VERSION ""

NS_ :

BS_:

BU_: Dummy_PCE EBOOST_OBD_PCE EOCM2cp_K2_PCE EPSb_PCE SDM_PCE EBCM_PCE EPSa_PCE CMMb_PCE CMMa_PCE CGM3b_PCE ADIMa_PCE
VAL_TABLE_ vt_BooleanValues 1 "true" 0 "false" ;
VAL_TABLE_ StgOvrdDetn 3 "Disabled" 2 "False" 1 "True" 0 "Initialization" ;
VAL_TABLE_ PriADSCmdMsgStat 3 "Dual Communication Failure" 2 "Secondary Communication Failed" 1 "Main Communication Failed" 0 "Communication Normal" ;
VAL_TABLE_ PriBrkSysArbStat 7 "Supervisor Override" 6 "Automatic Brake Apply 2" 5 "Automatic Brake Apply 1" 4 "CoPilot Override Request Honored" 3 "Redundant ADS Request Honored" 2 "Main ADS Request Honored" 1 "No Autonomous Request" 0 "Unknown" ;
VAL_TABLE_ StrgCmndMsgStat 3 "Dual Communication Failure" 2 "Redundant Communication Failed" 1 "Primary Communication Failed" 0 "Communication Normal" ;
VAL_TABLE_ StrgCmndMsgUtlzd 1 "Redundant Controller" 0 "Primary Controller" ;
VAL_TABLE_ AutoEstBrkTrqAppStat 2 "Valid" 1 "Reduced Accuracy" 0 "Invalid" ;
VAL_TABLE_ AutoBrkSysDrInfcStat 3 "Failed" 2 "Driver Intervention Not Detected" 1 "Driver Intervention Detected" 0 "Unknown" ;
VAL_TABLE_ BrkPedDrvOvrdDtdESC 3 "Unknown" 2 "External Source Building Pressure" 1 "ESC Building System Pressure" 0 "ESC System Pressure Inactive" ;
VAL_TABLE_ ActrBrkFldFlwReqStat 2 "qTarget_EBRmaxPerformance" 1 "qTarget_EBR" 0 "qTarget_Off" ;
VAL_TABLE_ EstWhlBrkPrsStat 3 "Invalid" 2 "Reduced Accuracy" 1 "Valid" 0 "Unknown" ;
VAL_TABLE_ SpltMuCntrl 2 "Split Driver Side High" 1 "Split Driver Side Low" 0 "Inactive" ;
VAL_TABLE_ PriBrkModStat 3 "Failed" 2 "Active" 1 "Available" 0 "Not Available" ;
VAL_TABLE_ PrkBrkReqiB 1 "Apply" 0 "No Request" ;
VAL_TABLE_ ExtBrkReqStat 3 "External Brake Req Active" 2 "External Brake Req Available" 1 "External Brake Req Not Available" 0 "Unknown" ;
VAL_TABLE_ PedOvrdBrkiBst 3 "Unknown" 2 "External Override of Brake Pedal" 1 "iBooster EBR in Control" 0 "iBooster Inactive" ;
VAL_TABLE_ Qualifier 2 "Faulted" 1 "Normal" 0 "Unknown" ;
VAL_TABLE_ iBstStat 7 "iBooster Ready" 6 "iBooster PostRun Reduced" 5 "iBooster Reduced" 2 "iBooster Diagnosis" 1 "iBooster Failure iBoosterOff" 0 "Unknown" 3 "iBooster Autonomous Diagnosis" 4 "iBooster Standalone" ;
VAL_TABLE_ BrkRngLmtgStat 3 "Request Rate Limited" 2 "Req Value Limited Maximum" 1 "Req Value Limited Minimum" 0 "Request Not Limited" ;
VAL_TABLE_ BrkSysStat 6 "Degraded Mode 5" 5 "Degraded Mode 4" 4 "Degraded Mode 3" 3 "Degraded Mode 2" 2 "Degraded Mode 1" 1 "Full Function" 0 "Unknown" ;
VAL_TABLE_ SecBrkModSbSte 5 "Loss of Request" 4 "Full System" 3 "Failed Operational" 2 "Failed Degraded" 1 "Unable to Execute Requests" 0 "Faulted" ;
VAL_TABLE_ SecBrkModCapStat 1 "Active" 0 "Not Active" ;
VAL_TABLE_ EstSrfcMuTyp 3 "Invalid" 2 "Actual Surface Estimate" 1 "Minimum Surface Estimate" 0 "Unknown" ;
VAL_TABLE_ SecBrkModStat 3 "Failed" 2 "Active" 1 "Available" 0 "Not Available" ;
VAL_TABLE_ StgSysOtptStat 3 "Failed" 2 "Single Controller" 1 "Fail Operational" 0 "Unknown" ;
VAL_TABLE_ StgOtptTempLmtgSte 4 "Voltage" 3 "Thermal" 2 "Safety Limit Exceeded" 1 "Normal" 0 "Unknown" 7 "ECU Fault Limited" 6 "Friction Limited" 5 "Lash Exceeded" ;
VAL_TABLE_ AutoStrgCmndStat 6 "Failed" 5 "Emergency Steering Profile" 4 "Temporarily Limited" 3 "Active" 2 "Ready" 1 "Temporarily Inhibited" 0 "Unknown" ;
VAL_TABLE_ EPSWAR_ReqdState 2 "Active" 1 "Inactive" 0 "No Action" ;
VAL_TABLE_ EPBReq 2 "Request Release" 1 "Request Apply" 0 "No Request" ;
VAL_TABLE_ AutoBrkReqType 2 "Standstill Hold Request" 1 "Brake Torque Request" 0 "No Request" 3 "Brake Prefill" ;
VAL_TABLE_ ABRS2_SAAYawMtReqScBsSt 7 "Not Used 2" 6 "Not Used 1" 5 "Request Out Of Range" 4 "CAN Error" 3 "Failed" 2 "Limited" 1 "Active" 0 "Not Active" ;
VAL_TABLE_ ABRS2_BcupESCDatInpSt 1 "Failed" 0 "Normal" ;
VAL_TABLE_ ABRS2_ACCAutBkRqPrBsSt 7 "Not Used 2" 6 "Not Used 1" 5 "Request Out Of Range" 4 "CAN Error" 3 "Failed" 2 "Limited" 1 "Active" 0 "Not Active" ;
VAL_TABLE_ WhlRotDrctnlStatus 0 "Unknown" 1 "Forward" 2 "Reverse" 3 "Not Supported" 4 "Failed" 5 "Reserved 1" 6 "Reserved 2" 7 "Reserved 3" ;
VAL_TABLE_ ChsSysTrnsShfBhvRq 7 "Upshift" 6 "Downshift" 5 "Minimum Inertia" 4 "Immediate Mode" 3 "Inhibit Shift" 2 "Inhibit Upshift" 1 "Inhibit Downshift" 0 "No Action" ;
VAL_TABLE_ NotEventSta 2 "Pretensioner Deployment Event" 1 "Near Deployment Event" 0 "No Event" 3 "Airbag Deployment Event" ;
VAL_TABLE_ VDAvailability 1 "VirtualDeviceAvailable" 0 "VirtualDeviceUnavailable" ;
VAL_TABLE_ MaskStates 1 "Use Data" 0 "Don't Use Data" ;
VAL_TABLE_ VehSpdAvgDrvnSrc 1 "Wheel Speed" 0 "Transmission Output Speed" ;
VAL_TABLE_ StrWhlAngSenCalStat 2 "Calibrated" 1 "Estimated" 0 "Unknown" ;
VAL_TABLE_ EngSpdStat 3 "Invalid" 1 "Degraded Operation" 0 "Normal Operation" ;
VAL_TABLE_ Vtsig_Diagpresreqstat 4 "Request Cancelled " 3 "Secondary Braking Req Honored" 2 "Primary Braking Request Honored" 1 "No Dynamic Request" 0 "Unknown" ;
VAL_TABLE_ VD_CoPilotSysFltStat 5 "Copilot System Failure" 4 "Partial Function Fault Detected" 3 "Redundancy Fault Detected" 2 "Environmental Interference" 1 "Operational" 0 "Unknown" ;
VAL_TABLE_ SecVehSpdSrcDrvnRed 3 "Transmission Output Speed" 2 "Averaged Driven Wheel Speed" 1 "Motor RPM" 0 " No Source Available" ;
VAL_TABLE_ EPBStat 3 "Failed" 2 "Reduced Performance" 1 "Normal" 0 "Unknown" ;
VAL_TABLE_ EPBApplSt 3 "Applied" 2 "Transitioning" 1 "Released" 0 "Unknown" ;
VAL_TABLE_ BrkFldLvlIndStat 1 "Failed" 0 "Normal" ;
VAL_TABLE_ SystemStatus 3 "Failed" 2 "Active" 1 "Available" 0 "Unknown" ;
VAL_TABLE_ StrgAngTrqBsdEstSrfcMuConf 2 "Indeterminate" 1 "Use Data" 0 "Do Not Use Data" ;
VAL_TABLE_ VehMdMngrSt 0 "Unknown" 1 "Manual" 2 "Autonomous Supervised" 3 "Supervisor Override" 4 "Autonomous Unsupervised" 5 "Failed" ;
VAL_TABLE_ SysBkUpPwrMd 3 "Crank Request" 2 "Run" 1 "Accessory" 0 "Off" ;
VAL_TABLE_ SysPwrMd 3 "Crank Request" 2 "Run" 1 "Accessory" 0 "Off" ;
VAL_TABLE_ ValidityStates 1 "Invalid" 0 "Valid" ;

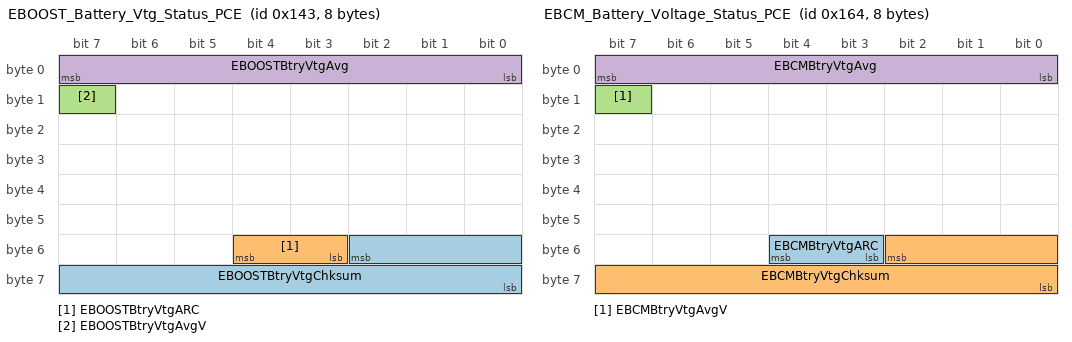
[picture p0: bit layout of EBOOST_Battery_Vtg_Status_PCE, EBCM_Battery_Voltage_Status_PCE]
BO_ 323 EBOOST_Battery_Vtg_Status_PCE: 8 EBOOST_OBD_PCE
 SG_ EBOOSTBtryVtgChksum : 50|11@0+ (1,0) [0|2047] ""  CGM3b_PCE
 SG_ EBOOSTBtryVtgARC : 52|2@0+ (1,0) [0|3] ""  CGM3b_PCE
 SG_ EBOOSTBtryVtgAvgV : 15|1@0+ (1,0) [0|1] ""  CGM3b_PCE
 SG_ EBOOSTBtryVtgAvg : 7|8@0+ (0.1,0) [0|25.5] "V"  CGM3b_PCE

BO_ 356 EBCM_Battery_Voltage_Status_PCE: 8 EBCM_PCE
 SG_ EBCMBtryVtgARC : 52|2@0+ (1,0) [0|3] ""  CGM3b_PCE
 SG_ EBCMBtryVtgChksum : 50|11@0+ (1,0) [0|2047] ""  CGM3b_PCE
 SG_ EBCMBtryVtgAvgV : 15|1@0+ (1,0) [0|1] ""  CGM3b_PCE
 SG_ EBCMBtryVtgAvg : 7|8@0+ (0.1,0) [0|25.5] "V"  CGM3b_PCE

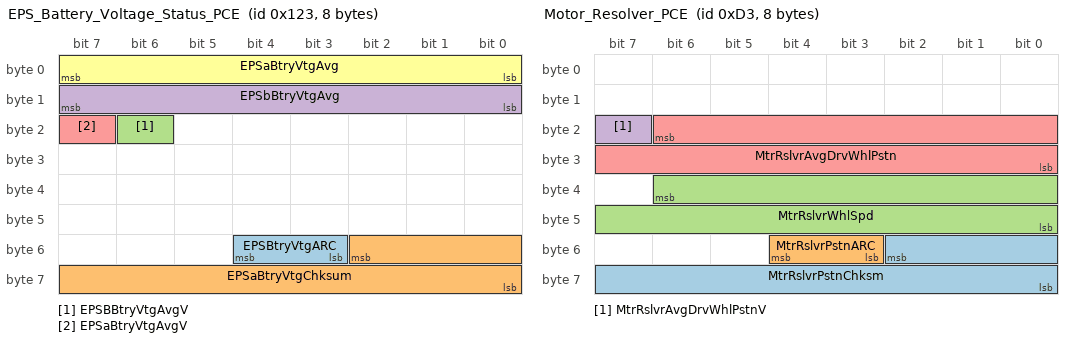
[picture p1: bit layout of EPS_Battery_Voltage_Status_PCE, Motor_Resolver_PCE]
BO_ 291 EPS_Battery_Voltage_Status_PCE: 8 EPSa_PCE
 SG_ EPSBtryVtgARC : 52|2@0+ (1,0) [0|3] ""  CGM3b_PCE
 SG_ EPSaBtryVtgChksum : 50|11@0+ (1,0) [0|2047] ""  CGM3b_PCE
 SG_ EPSBBtryVtgAvgV : 22|1@0+ (1,0) [0|1] ""  CGM3b_PCE
 SG_ EPSbBtryVtgAvg : 15|8@0+ (0.1,0) [0|25.5] "V"  CGM3b_PCE
 SG_ EPSaBtryVtgAvgV : 23|1@0+ (1,0) [0|1] ""  CGM3b_PCE
 SG_ EPSaBtryVtgAvg : 7|8@0+ (0.1,0) [0|25.5] "V"  CGM3b_PCE

BO_ 211 Motor_Resolver_PCE: 8 CGM3b_PCE
 SG_ MtrRslvrPstnChksm : 50|11@0+ (1,0) [0|2047] ""  CMMb_PCE,CMMa_PCE
 SG_ MtrRslvrPstnARC : 52|2@0+ (1,0) [0|3] ""  CMMb_PCE,CMMa_PCE
 SG_ MtrRslvrWhlSpd : 38|15@0+ (0.005035400390625,-15) [-15|149.994964599609] "radians/s"  CMMb_PCE,CMMa_PCE
 SG_ MtrRslvrAvgDrvWhlPstnV : 23|1@0+ (1,0) [0|1] ""  CMMb_PCE,CMMa_PCE
 SG_ MtrRslvrAvgDrvWhlPstn : 22|15@0+ (1,0) [0|32768] "Count"  CMMb_PCE,CMMa_PCE

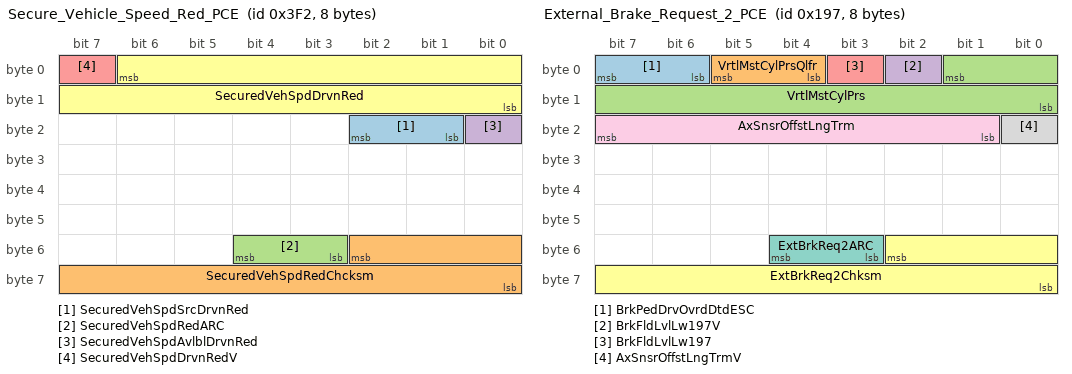
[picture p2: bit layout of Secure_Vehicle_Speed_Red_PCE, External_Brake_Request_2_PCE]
BO_ 1010 Secure_Vehicle_Speed_Red_PCE: 8 CGM3b_PCE
 SG_ SecuredVehSpdSrcDrvnRed : 18|2@0+ (1,0) [0|3] ""  EPSa_PCE,EBOOST_OBD_PCE
 SG_ SecuredVehSpdRedChcksm : 50|11@0+ (1,0) [0|2047] ""  EPSa_PCE,EBOOST_OBD_PCE
 SG_ SecuredVehSpdRedARC : 52|2@0+ (1,0) [0|3] ""  EPSa_PCE,EBOOST_OBD_PCE
 SG_ SecuredVehSpdAvlblDrvnRed : 16|1@0+ (1,0) [0|1] ""  EPSa_PCE,EBOOST_OBD_PCE
 SG_ SecuredVehSpdDrvnRedV : 7|1@0+ (1,0) [0|1] ""  EPSa_PCE,EBOOST_OBD_PCE
 SG_ SecuredVehSpdDrvnRed : 6|15@0+ (0.015625,0) [0|511.984375] "km/h"  EPSa_PCE,EBOOST_OBD_PCE

BO_ 1620 USDT_Resp_From_EBoost_PCE: 8 EBOOST_OBD_PCE
 SG_ DgnInf : 7|64@0+ (1,0) [0|1.84467440737096E+019] ""  CGM3b_PCE

BO_ 1611 USDT_Resp_From_EOCM2cp_K2_PCE: 8 EOCM2cp_K2_PCE
 SG_ DgnInf : 7|64@0+ (1,0) [0|1.84467440737096E+019] ""  CGM3b_PCE

BO_ 584 USDT_Req_to_EPSb_PCE: 8 CGM3b_PCE
 SG_ DgnInf : 7|64@0+ (1,0) [0|1.84467440737096E+019] ""  EPSb_PCE

BO_ 587 USDT_Req_to_EOCM2cp_K2_PCE: 8 CGM3b_PCE
 SG_ DgnInf : 7|64@0+ (1,0) [0|1.84467440737096E+019] ""  EOCM2cp_K2_PCE

BO_ 407 External_Brake_Request_2_PCE: 8 EBCM_PCE
 SG_ BrkPedDrvOvrdDtdESC : 7|2@0+ (1,0) [0|3] ""  EBOOST_OBD_PCE
 SG_ VrtlMstCylPrsQlfr : 5|2@0+ (1,0) [0|3] ""  EBOOST_OBD_PCE
 SG_ VrtlMstCylPrs : 1|10@0+ (0.25,0) [0|250] "bar"  EBOOST_OBD_PCE
 SG_ BrkFldLvlLw197V : 2|1@0+ (1,0) [0|1] ""  ADIMa_PCE,EBOOST_OBD_PCE
 SG_ BrkFldLvlLw197 : 3|1@0+ (1,0) [0|1] ""  ADIMa_PCE,EBOOST_OBD_PCE
 SG_ ExtBrkReq2Chksm : 50|11@0+ (1,0) [0|2047] ""  EBOOST_OBD_PCE
 SG_ ExtBrkReq2ARC : 52|2@0+ (1,0) [0|3] ""  EBOOST_OBD_PCE
 SG_ AxSnsrOffstLngTrmV : 16|1@0+ (1,0) [0|1] ""  EBOOST_OBD_PCE
 SG_ AxSnsrOffstLngTrm : 23|7@0+ (0.0675,-4) [-4|3.9375] "m/s2"  EBOOST_OBD_PCE

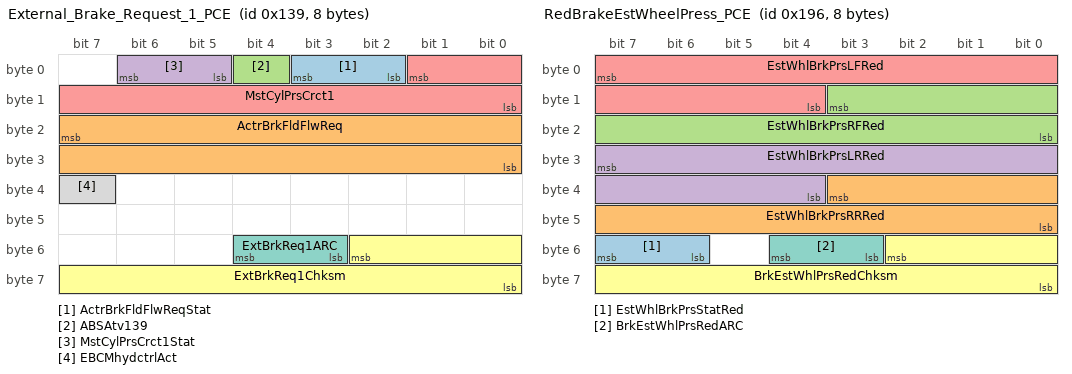
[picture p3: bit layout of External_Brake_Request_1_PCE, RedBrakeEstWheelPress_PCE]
BO_ 313 External_Brake_Request_1_PCE: 8 EBCM_PCE
 SG_ ActrBrkFldFlwReqStat : 3|2@0+ (1,0) [0|3] ""  EBOOST_OBD_PCE
 SG_ ActrBrkFldFlwReq : 23|16@0+ (0.0076904296875,-252) [-252|252] "mL/s"  EBOOST_OBD_PCE
 SG_ ABSAtv139 : 4|1@0+ (1,0) [0|1] ""  EBOOST_OBD_PCE
 SG_ MstCylPrsCrct1Stat : 6|2@0+ (1,0) [0|3] ""  ADIMa_PCE,EBOOST_OBD_PCE
 SG_ MstCylPrsCrct1 : 1|10@0+ (0.3,0) [0|276.6] "bar"  ADIMa_PCE,EBOOST_OBD_PCE
 SG_ ExtBrkReq1Chksm : 50|11@0+ (1,0) [0|2047] ""  EBOOST_OBD_PCE
 SG_ ExtBrkReq1ARC : 52|2@0+ (1,0) [0|3] ""  EBOOST_OBD_PCE
 SG_ EBCMhydctrlAct : 39|1@0+ (1,0) [0|1] ""  EBOOST_OBD_PCE

BO_ 406 RedBrakeEstWheelPress_PCE: 8 EBCM_PCE
 SG_ EstWhlBrkPrsStatRed : 55|2@0+ (1,0) [0|3] ""  EBOOST_OBD_PCE,ADIMa_PCE
 SG_ EstWhlBrkPrsRRRed : 35|12@0+ (10,0) [0|40950] "kPa"  EBOOST_OBD_PCE,ADIMa_PCE
 SG_ EstWhlBrkPrsRFRed : 11|12@0+ (10,0) [0|40950] "kPa"  EBOOST_OBD_PCE,ADIMa_PCE
 SG_ EstWhlBrkPrsLRRed : 31|12@0+ (10,0) [0|40950] "kPa"  EBOOST_OBD_PCE,ADIMa_PCE
 SG_ EstWhlBrkPrsLFRed : 7|12@0+ (10,0) [0|40950] "kPa"  EBOOST_OBD_PCE,ADIMa_PCE
 SG_ BrkEstWhlPrsRedChksm : 50|11@0+ (1,0) [0|2047] ""  EBOOST_OBD_PCE,ADIMa_PCE
 SG_ BrkEstWhlPrsRedARC : 52|2@0+ (1,0) [0|3] ""  EBOOST_OBD_PCE,ADIMa_PCE

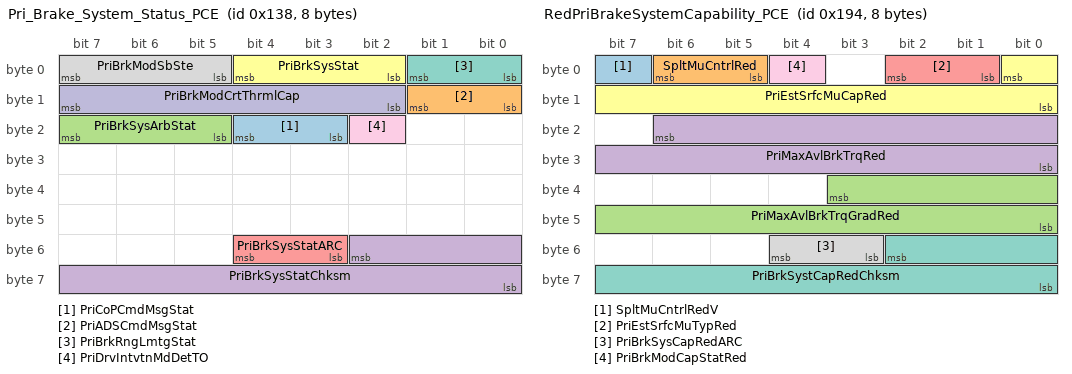
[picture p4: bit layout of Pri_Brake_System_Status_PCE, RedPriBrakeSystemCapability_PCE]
BO_ 312 Pri_Brake_System_Status_PCE: 8 EBCM_PCE
 SG_ PriCoPCmdMsgStat : 20|2@0+ (1,0) [0|3] ""  EBOOST_OBD_PCE,ADIMa_PCE
 SG_ PriADSCmdMsgStat : 9|2@0+ (1,0) [0|3] ""  EBOOST_OBD_PCE,ADIMa_PCE
 SG_ PriBrkSysArbStat : 23|3@0+ (1,0) [0|7] ""  EBOOST_OBD_PCE,ADIMa_PCE
 SG_ PriBrkSysStatChksm : 50|11@0+ (1,0) [0|2047] ""  ADIMa_PCE,EBOOST_OBD_PCE
 SG_ PriBrkSysStatARC : 52|2@0+ (1,0) [0|3] ""  ADIMa_PCE,EBOOST_OBD_PCE
 SG_ PriBrkSysStat : 4|3@0+ (1,0) [0|7] ""  ADIMa_PCE,EBOOST_OBD_PCE
 SG_ PriBrkRngLmtgStat : 1|2@0+ (1,0) [0|3] ""  ADIMa_PCE,EBOOST_OBD_PCE
 SG_ PriBrkModSbSte : 7|3@0+ (1,0) [0|7] ""  ADIMa_PCE,EBOOST_OBD_PCE
 SG_ PriDrvIntvtnMdDetTO : 18|1@0+ (1,0) [0|1] ""  ADIMa_PCE,EBOOST_OBD_PCE
 SG_ PriBrkModCrtThrmlCap : 15|6@0+ (1.5873,0) [0|100] "%"  EBOOST_OBD_PCE,ADIMa_PCE

BO_ 404 RedPriBrakeSystemCapability_PCE: 8 EBCM_PCE
 SG_ SpltMuCntrlRedV : 7|1@0+ (1,0) [0|1] ""  ADIMa_PCE
 SG_ SpltMuCntrlRed : 6|2@0+ (1,0) [0|3] ""  ADIMa_PCE
 SG_ PriMaxAvlBrkTrqGradRed : 35|12@0+ (100,0) [0|409500] ""  ADIMa_PCE
 SG_ PriMaxAvlBrkTrqRed : 22|15@0+ (2,-65534) [-65534|0] "Nm"  ADIMa_PCE
 SG_ PriEstSrfcMuTypRed : 2|2@0+ (1,0) [0|3] ""  ADIMa_PCE
 SG_ PriEstSrfcMuCapRed : 0|9@0+ (0.006,0) [0|3.066] ""  ADIMa_PCE
 SG_ PriBrkSystCapRedChksm : 50|11@0+ (1,0) [0|2047] ""  ADIMa_PCE
 SG_ PriBrkSysCapRedARC : 52|2@0+ (1,0) [0|3] ""  ADIMa_PCE
 SG_ PriBrkModCapStatRed : 4|1@0+ (1,0) [0|1] ""  ADIMa_PCE

BO_ 596 USDT_Req_to_EBoost_PCE: 8 CGM3b_PCE
 SG_ DgnInf : 7|64@0+ (1,0) [0|1.84467440737096E+019] ""  EBOOST_OBD_PCE

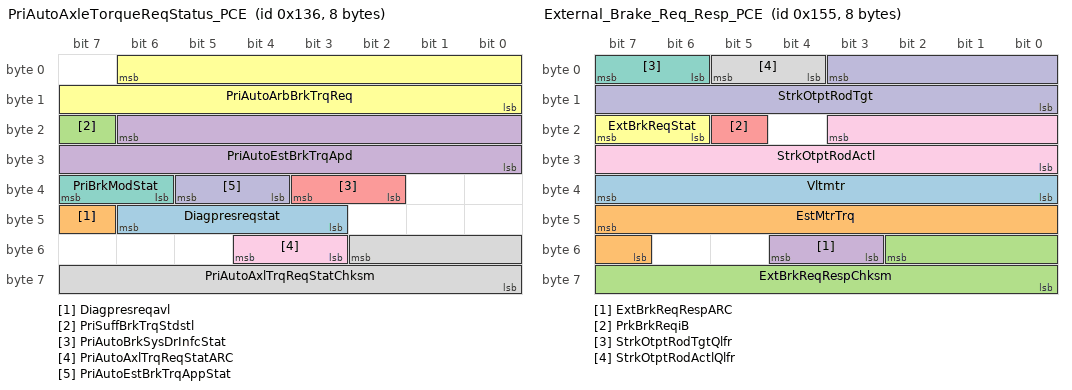
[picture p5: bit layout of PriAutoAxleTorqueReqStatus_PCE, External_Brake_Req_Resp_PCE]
BO_ 310 PriAutoAxleTorqueReqStatus_PCE: 8 EBCM_PCE
 SG_ Diagpresreqstat : 46|4@0+ (1,0) [0|0] ""  ADIMa_PCE
 SG_ Diagpresreqavl : 47|1@0+ (1,0) [0|1] ""  ADIMa_PCE
 SG_ PriSuffBrkTrqStdstl : 23|1@0+ (1,0) [0|1] ""  CGM3b_PCE,ADIMa_PCE
 SG_ PriAutoEstBrkTrqApd : 22|15@0+ (2,-65534) [-65534|0] "Nm"  CGM3b_PCE,ADIMa_PCE
 SG_ PriAutoBrkSysDrInfcStat : 35|2@0+ (1,0) [0|3] ""  EBOOST_OBD_PCE,CGM3b_PCE,ADIMa_PCE
 SG_ PriAutoArbBrkTrqReq : 6|15@0+ (2,-65534) [-65534|0] "Nm"  ADIMa_PCE,CGM3b_PCE
 SG_ PriBrkModStat : 39|2@0+ (1,0) [0|3] ""  ADIMa_PCE,CGM3b_PCE
 SG_ PriAutoAxlTrqReqStatChksm : 50|11@0+ (1,0) [0|2047] ""  CGM3b_PCE,ADIMa_PCE
 SG_ PriAutoAxlTrqReqStatARC : 52|2@0+ (1,0) [0|3] ""  ADIMa_PCE,CGM3b_PCE
 SG_ PriAutoEstBrkTrqAppStat : 37|2@0+ (1,0) [0|3] ""  CGM3b_PCE,ADIMa_PCE

BO_ 341 External_Brake_Req_Resp_PCE: 8 EBOOST_OBD_PCE
 SG_ Vltmtr : 39|8@0+ (0.1,0) [0|25.5] "V"  ADIMa_PCE
 SG_ EstMtrTrq : 47|9@0+ (0.01,0) [0|5.11] "Nm"  ADIMa_PCE
 SG_ ExtBrkReqRespChksm : 50|11@0+ (1,0) [0|2047] ""  EBCM_PCE
 SG_ ExtBrkReqRespARC : 52|2@0+ (1,0) [0|3] ""  EBCM_PCE
 SG_ PrkBrkReqiB : 21|1@0+ (1,0) [0|1] ""  EBCM_PCE
 SG_ ExtBrkReqStat : 23|2@0+ (1,0) [0|3] ""  EBCM_PCE
 SG_ StrkOtptRodTgtQlfr : 7|2@0+ (1,0) [0|3] ""  ADIMa_PCE,EBCM_PCE
 SG_ StrkOtptRodActlQlfr : 5|2@0+ (1,0) [0|3] ""  ADIMa_PCE,EBCM_PCE
 SG_ StrkOtptRodActl : 19|12@0+ (0.015625,0) [0|64] "mm"  ADIMa_PCE,EBCM_PCE
 SG_ StrkOtptRodTgt : 3|12@0+ (0.015625,0) [0|64] "mm"  ADIMa_PCE,EBCM_PCE

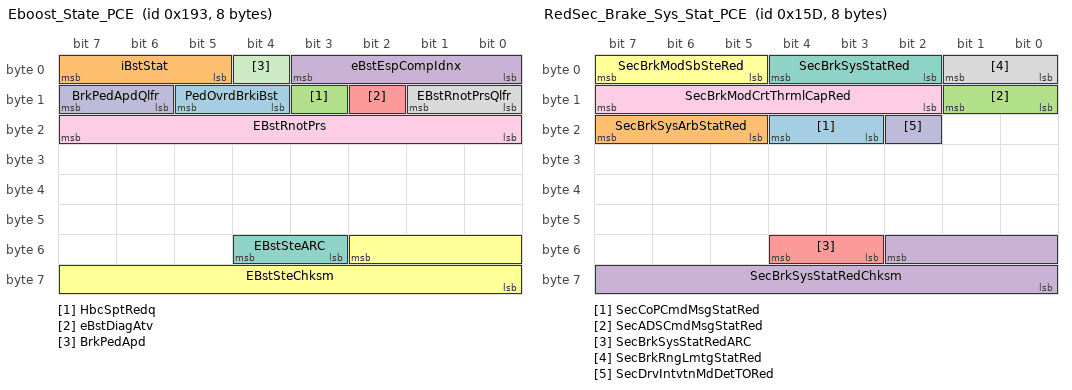
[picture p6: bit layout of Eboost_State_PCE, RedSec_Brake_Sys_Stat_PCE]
BO_ 403 Eboost_State_PCE: 8 EBOOST_OBD_PCE
 SG_ PedOvrdBrkiBst : 13|2@0+ (1,0) [0|3] ""  EBCM_PCE
 SG_ iBstStat : 7|3@0+ (1,0) [0|7] ""  EBCM_PCE
 SG_ HbcSptRedq : 11|1@0+ (1,0) [0|1] ""  EBCM_PCE
 SG_ eBstEspCompIdnx : 3|4@0+ (1,0) [0|15] ""  EBCM_PCE
 SG_ eBstDiagAtv : 10|1@0+ (1,0) [0|1] ""  EBCM_PCE
 SG_ EBstSteChksm : 50|11@0+ (1,0) [0|2047] ""  EBCM_PCE
 SG_ EBstSteARC : 52|2@0+ (1,0) [0|3] ""  EBCM_PCE
 SG_ EBstRnotPrsQlfr : 9|2@0+ (1,0) [0|3] ""  EBCM_PCE
 SG_ EBstRnotPrs : 23|8@0+ (1,0) [0|255] "bar"  EBCM_PCE
 SG_ BrkPedApdQlfr : 15|2@0+ (1,0) [0|3] ""  EBCM_PCE
 SG_ BrkPedApd : 4|1@0+ (1,0) [0|1] ""  EBCM_PCE

BO_ 349 RedSec_Brake_Sys_Stat_PCE: 8 EBOOST_OBD_PCE
 SG_ SecCoPCmdMsgStatRed : 20|2@0+ (1,0) [0|3] ""  EBCM_PCE,ADIMa_PCE
 SG_ SecBrkSysArbStatRed : 23|3@0+ (1,0) [0|7] ""  EBCM_PCE,ADIMa_PCE
 SG_ SecADSCmdMsgStatRed : 9|2@0+ (1,0) [0|3] ""  EBCM_PCE,ADIMa_PCE
 SG_ SecBrkSysStatRedChksm : 50|11@0+ (1,0) [0|2047] ""  ADIMa_PCE,EBCM_PCE
 SG_ SecBrkSysStatRedARC : 52|2@0+ (1,0) [0|3] ""  ADIMa_PCE,EBCM_PCE
 SG_ SecBrkModSbSteRed : 7|3@0+ (1,0) [0|7] ""  ADIMa_PCE,EBCM_PCE
 SG_ SecBrkSysStatRed : 4|3@0+ (1,0) [0|7] ""  ADIMa_PCE,EBCM_PCE
 SG_ SecBrkRngLmtgStatRed : 1|2@0+ (1,0) [0|3] ""  ADIMa_PCE,EBCM_PCE
 SG_ SecBrkModCrtThrmlCapRed : 15|6@0+ (1.5873,0) [0|100] "%"  ADIMa_PCE,EBCM_PCE
 SG_ SecDrvIntvtnMdDetTORed : 18|1@0+ (1,0) [0|1] ""  ADIMa_PCE,EBCM_PCE

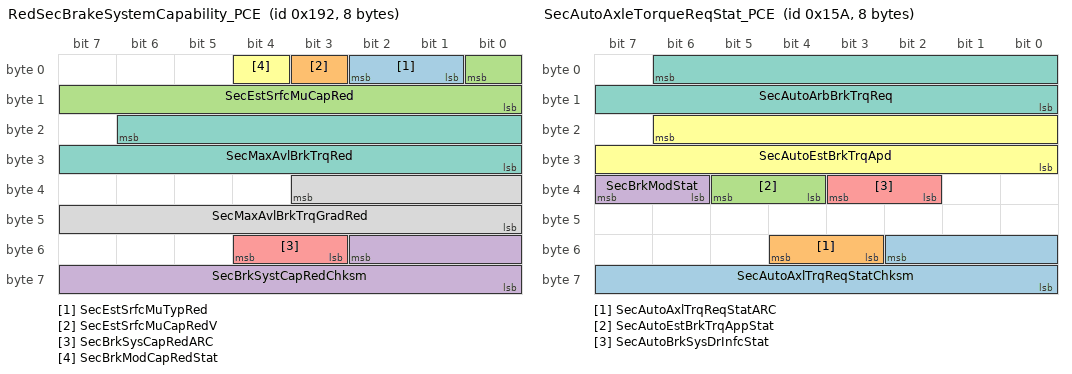
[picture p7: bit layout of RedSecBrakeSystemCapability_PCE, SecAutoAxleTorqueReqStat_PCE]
BO_ 402 RedSecBrakeSystemCapability_PCE: 8 EBOOST_OBD_PCE
 SG_ SecEstSrfcMuTypRed : 2|2@0+ (1,0) [0|3] ""  ADIMa_PCE
 SG_ SecEstSrfcMuCapRedV : 3|1@0+ (1,0) [0|1] ""  ADIMa_PCE
 SG_ SecEstSrfcMuCapRed : 0|9@0+ (0.006,0) [0|3.066] ""  ADIMa_PCE
 SG_ SecBrkSystCapRedChksm : 50|11@0+ (1,0) [0|2047] ""  ADIMa_PCE
 SG_ SecBrkSysCapRedARC : 52|2@0+ (1,0) [0|3] ""  ADIMa_PCE
 SG_ SecBrkModCapRedStat : 4|1@0+ (1,0) [0|1] ""  ADIMa_PCE
 SG_ SecMaxAvlBrkTrqRed : 22|15@0+ (2,-65534) [-65534|0] "Nm"  ADIMa_PCE
 SG_ SecMaxAvlBrkTrqGradRed : 35|12@0+ (100,0) [0|409500] ""  ADIMa_PCE

BO_ 346 SecAutoAxleTorqueReqStat_PCE: 8 EBOOST_OBD_PCE
 SG_ SecAutoAxlTrqReqStatChksm : 50|11@0+ (1,0) [0|2047] ""  EBCM_PCE,ADIMa_PCE
 SG_ SecAutoAxlTrqReqStatARC : 52|2@0+ (1,0) [0|3] ""  EBCM_PCE,ADIMa_PCE
 SG_ SecAutoEstBrkTrqAppStat : 37|2@0+ (1,0) [0|3] ""  EBCM_PCE,ADIMa_PCE
 SG_ SecBrkModStat : 39|2@0+ (1,0) [0|3] ""  EBCM_PCE,ADIMa_PCE
 SG_ SecAutoBrkSysDrInfcStat : 35|2@0+ (1,0) [0|3] ""  EBCM_PCE,ADIMa_PCE
 SG_ SecAutoEstBrkTrqApd : 22|15@0+ (2,-65534) [-65534|0] "Nm"  EBCM_PCE,ADIMa_PCE
 SG_ SecAutoArbBrkTrqReq : 6|15@0+ (2,-65534) [-65534|0] "Nm"  EBCM_PCE,ADIMa_PCE

BO_ 1627 USDT_Resp_From_CMM_PCE: 8 CMMa_PCE
 SG_ DgnInf : 7|64@0+ (1,0) [0|1.84467440737096E+019] ""  CGM3b_PCE

BO_ 1623 USDT_Resp_From_ADIMa_PCE: 8 ADIMa_PCE
 SG_ DgnInf : 7|64@0+ (1,0) [0|1.84467440737096E+019] ""  CGM3b_PCE

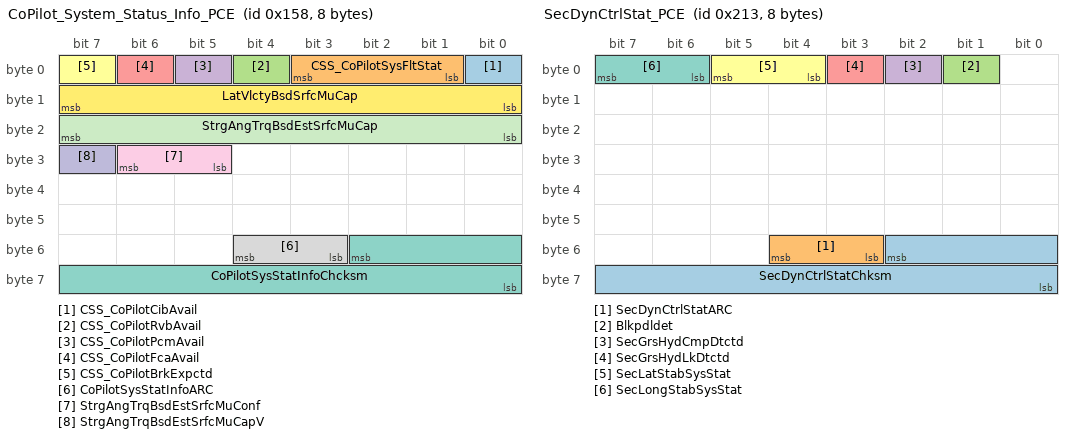
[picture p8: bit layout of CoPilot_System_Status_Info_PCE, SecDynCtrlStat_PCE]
BO_ 344 CoPilot_System_Status_Info_PCE: 8 EOCM2cp_K2_PCE
 SG_ CSS_CoPilotCibAvail : 0|1@0+ (1,0) [0|1] ""  EBCM_PCE,EBOOST_OBD_PCE,ADIMa_PCE
 SG_ CSS_CoPilotSysFltStat : 3|3@0+ (1,0) [0|7] ""  EBCM_PCE,EBOOST_OBD_PCE,ADIMa_PCE
 SG_ CSS_CoPilotRvbAvail : 4|1@0+ (1,0) [0|1] ""  EBCM_PCE,EBOOST_OBD_PCE,ADIMa_PCE
 SG_ CSS_CoPilotPcmAvail : 5|1@0+ (1,0) [0|1] ""  EBCM_PCE,EBOOST_OBD_PCE,ADIMa_PCE
 SG_ CSS_CoPilotFcaAvail : 6|1@0+ (1,0) [0|1] ""  EBCM_PCE,EBOOST_OBD_PCE,ADIMa_PCE
 SG_ CSS_CoPilotBrkExpctd : 7|1@0+ (1,0) [0|1] ""  EBCM_PCE,EBOOST_OBD_PCE,ADIMa_PCE
 SG_ CoPilotSysStatInfoChcksm : 50|11@0+ (1,0) [0|2047] ""  EBCM_PCE,EBOOST_OBD_PCE,ADIMa_PCE
 SG_ CoPilotSysStatInfoARC : 52|2@0+ (1,0) [0|0] ""  EBCM_PCE,EBOOST_OBD_PCE,ADIMa_PCE
 SG_ StrgAngTrqBsdEstSrfcMuConf : 30|2@0+ (1,0) [0|3] ""  EBCM_PCE,EBOOST_OBD_PCE,ADIMa_PCE
 SG_ StrgAngTrqBsdEstSrfcMuCapV : 31|1@0+ (1,0) [0|1] ""  EBCM_PCE,EBOOST_OBD_PCE,ADIMa_PCE
 SG_ StrgAngTrqBsdEstSrfcMuCap : 23|8@0+ (0.01,0) [0|2.55] ""  EBCM_PCE,EBOOST_OBD_PCE,ADIMa_PCE
 SG_ LatVlctyBsdSrfcMuCap : 15|8@0+ (0.01,0) [0|2.55] ""  EBCM_PCE,EBOOST_OBD_PCE,ADIMa_PCE

BO_ 531 SecDynCtrlStat_PCE: 8 EBOOST_OBD_PCE
 SG_ SecDynCtrlStatChksm : 50|11@0+ (1,0) [0|2047] ""  EBCM_PCE,ADIMa_PCE
 SG_ SecDynCtrlStatARC : 52|2@0+ (1,0) [0|3] ""  EBCM_PCE,ADIMa_PCE
 SG_ Blkpdldet : 1|1@0+ (1,0) [0|1] ""  ADIMa_PCE,EBCM_PCE
 SG_ SecGrsHydCmpDtctd : 2|1@0+ (1,0) [0|1] ""  EBCM_PCE,ADIMa_PCE
 SG_ SecGrsHydLkDtctd : 3|1@0+ (1,0) [0|1] ""  EBCM_PCE,ADIMa_PCE
 SG_ SecLatStabSysStat : 5|2@0+ (1,0) [0|0] ""  EBCM_PCE,ADIMa_PCE
 SG_ SecLongStabSysStat : 7|2@0+ (1,0) [0|3] ""  EBCM_PCE,ADIMa_PCE

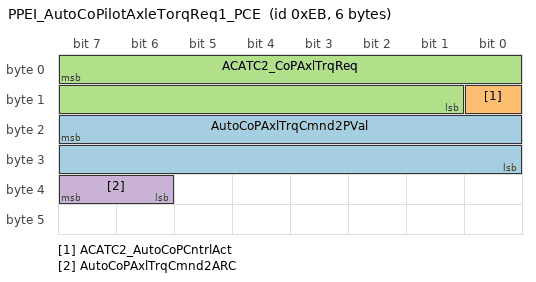
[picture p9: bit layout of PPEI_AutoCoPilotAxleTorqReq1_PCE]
BO_ 235 PPEI_AutoCoPilotAxleTorqReq1_PCE: 6 EOCM2cp_K2_PCE
 SG_ AutoCoPAxlTrqCmnd2PVal : 23|16@0+ (1,0) [0|65535] ""  ADIMa_PCE
 SG_ ACATC2_AutoCoPCntrlAct : 8|1@0+ (1,0) [0|1] ""  ADIMa_PCE
 SG_ ACATC2_CoPAxlTrqReq : 7|15@0+ (2,-22534) [-22534|43000] "Nm"  ADIMa_PCE
 SG_ AutoCoPAxlTrqCmnd2ARC : 39|2@0+ (1,0) [0|3] ""  ADIMa_PCE

BO_ 1366 UUDT_Resp_From_CMMb_PCE: 8 CMMb_PCE
 SG_ DgnInf_CE556 : 7|64@0+ (1,0) [0|1.84467440737096E+019] ""  CGM3b_PCE

BO_ 342 AutoSteeringStatus_PCE: 8 EPSa_PCE
 SG_ StgCmndTgtAng : 18|11@0- (1,0) [-1024|1023] "deg"  CMMb_PCE,CMMa_PCE,EOCM2cp_K2_PCE,ADIMa_PCE
 SG_ StrgCmndMsgStatV : 35|1@0+ (1,0) [0|1] ""  CMMb_PCE,CMMa_PCE,EOCM2cp_K2_PCE,ADIMa_PCE
 SG_ StrgCmndMsgStat : 5|2@0+ (1,0) [0|3] ""  CMMb_PCE,CMMa_PCE,EOCM2cp_K2_PCE,ADIMa_PCE
 SG_ StrgCmndMsgUtlzdV : 19|1@0+ (1,0) [0|1] ""  CMMb_PCE,CMMa_PCE,EOCM2cp_K2_PCE,ADIMa_PCE
 SG_ StrgCmndMsgUtlzd : 20|1@0+ (1,0) [0|1] ""  CMMb_PCE,CMMa_PCE,EOCM2cp_K2_PCE,ADIMa_PCE
 SG_ AutoStrgCmndStatV : 6|1@0+ (1,0) [0|1] ""  CMMb_PCE,CMMa_PCE,EOCM2cp_K2_PCE,ADIMa_PCE
 SG_ StgTtlEffTrqDlvd : 33|10@0- (0.25,0) [-128|127.75] ""  CMMb_PCE,CMMa_PCE,EOCM2cp_K2_PCE,ADIMa_PCE,EBOOST_OBD_PCE,EBCM_PCE
 SG_ StgTrqSnsrVStat : 39|1@0+ (1,0) [0|1] ""  CMMb_PCE,CMMa_PCE,EOCM2cp_K2_PCE,ADIMa_PCE,EBOOST_OBD_PCE,EBCM_PCE
 SG_ StgSysOtptStatV : 7|1@0+ (1,0) [0|1] ""  CMMb_PCE,CMMa_PCE,EOCM2cp_K2_PCE,ADIMa_PCE
 SG_ StgSysOtptStat : 3|2@0+ (1,0) [0|3] ""  CMMb_PCE,CMMa_PCE,EOCM2cp_K2_PCE,ADIMa_PCE
 SG_ StgOtptTempLmtgSte : 23|3@0+ (1,0) [0|7] ""  CMMb_PCE,CMMa_PCE,EOCM2cp_K2_PCE,ADIMa_PCE
 SG_ StgAngRtLmtV : 55|1@0+ (1,0) [0|1] ""  CMMb_PCE,CMMa_PCE,EOCM2cp_K2_PCE,ADIMa_PCE
 SG_ StgAngRtLmt : 1|10@0+ (1,0) [0|1023] "deg"  CMMb_PCE,CMMa_PCE,EOCM2cp_K2_PCE,ADIMa_PCE
 SG_ AutoStrgCmndStat : 38|3@0+ (1,0) [0|7] ""  CMMb_PCE,CMMa_PCE,EOCM2cp_K2_PCE,ADIMa_PCE
 SG_ AutoStgStatChksm : 50|11@0+ (1,0) [0|2047] ""  CMMb_PCE,CMMa_PCE,EOCM2cp_K2_PCE,ADIMa_PCE
 SG_ AutoStgStatARC : 52|2@0+ (1,0) [0|3] ""  CMMb_PCE,CMMa_PCE,EOCM2cp_K2_PCE,ADIMa_PCE
 SG_ StgOvrdDetn : 54|2@0+ (1,0) [0|3] ""  CMMb_PCE,CMMa_PCE,EOCM2cp_K2_PCE,ADIMa_PCE,EBOOST_OBD_PCE,EBCM_PCE

BO_ 354 PriDynCtrlStat_PCE: 8 EBCM_PCE
 SG_ EstBrkRtrTempStat : 40|1@0+ (1,0) [0|1] ""  EOCM2cp_K2_PCE,ADIMa_PCE
 SG_ PriDynCtrlStatChksm : 50|11@0+ (1,0) [0|2047] ""  ADIMa_PCE,EOCM2cp_K2_PCE
 SG_ PriDynCtrlStatARC : 52|2@0+ (1,0) [0|3] ""  ADIMa_PCE,EOCM2cp_K2_PCE
 SG_ EstBrkRtrTempRR : 31|6@0+ (8.5714,-40) [-40|500] "deg C"  EOCM2cp_K2_PCE,ADIMa_PCE
 SG_ EstBrkRtrTempRF : 15|6@0+ (8.5714,-40) [-40|500] "deg C"  EOCM2cp_K2_PCE,ADIMa_PCE
 SG_ EstBrkRtrTempLR : 23|6@0+ (8.5714,-40) [-40|500] "deg C"  EOCM2cp_K2_PCE,ADIMa_PCE
 SG_ EstBrkRtrTempLF : 7|6@0+ (8.5714,-40) [-40|500] "deg C"  EOCM2cp_K2_PCE,ADIMa_PCE
 SG_ PriGrsBrkIneffDtctd : 41|1@0+ (1,0) [0|1] ""  EOCM2cp_K2_PCE,ADIMa_PCE
 SG_ PriGrsHydCmpDtctd : 42|1@0+ (1,0) [0|1] ""  EOCM2cp_K2_PCE,ADIMa_PCE
 SG_ PriGrsHydLkDtctd : 43|1@0+ (1,0) [0|1] ""  EOCM2cp_K2_PCE,ADIMa_PCE
 SG_ RdRghnsStat : 44|1@0+ (1,0) [0|1] ""  EOCM2cp_K2_PCE,ADIMa_PCE
 SG_ RdRghnsIndctn : 39|5@0+ (3.2258,0) [0|100] "%"  EOCM2cp_K2_PCE,ADIMa_PCE
 SG_ EPBApplSt : 47|2@0+ (1,0) [0|3] ""  ADIMa_PCE,EOCM2cp_K2_PCE
 SG_ EPBStat : 34|2@0+ (1,0) [0|3] ""  ADIMa_PCE,EOCM2cp_K2_PCE
 SG_ BrkFldLvlIndStat : 45|1@0+ (1,0) [0|1] ""  EOCM2cp_K2_PCE,ADIMa_PCE
 SG_ BrkFldLvILwFldDtctd : 32|1@0+ (1,0) [0|1] ""  EOCM2cp_K2_PCE,ADIMa_PCE
 SG_ PriESCStat : 25|2@0+ (1,0) [0|3] ""  EOCM2cp_K2_PCE,ADIMa_PCE
 SG_ PriTCSStat : 17|2@0+ (1,0) [0|3] ""  EOCM2cp_K2_PCE,ADIMa_PCE
 SG_ PriABSStat : 9|2@0+ (1,0) [0|3] ""  EOCM2cp_K2_PCE,ADIMa_PCE
 SG_ PriDRPStat : 1|2@0+ (1,0) [0|3] ""  EOCM2cp_K2_PCE,ADIMa_PCE

CM_ "Private CE bus";
CM_ BU_ Dummy_PCE "This is to avoid single ended signalling";
CM_ BU_ EBOOST_OBD_PCE "Electric Brake Booster - OBD";
CM_ BU_ EOCM2cp_K2_PCE "External Object Control Module Safety co-pilot - K2 micro";
CM_ BU_ EPSb_PCE "Electronic Power Steering 2";
CM_ BU_ SDM_PCE "Sensing & Diagnostic Module (Airbag)";
CM_ BU_ EBCM_PCE "Electronic Brake Control Module";
CM_ BU_ EPSa_PCE "Electronic Power Steering";
CM_ BU_ CMMb_PCE "Chassis Motion Module";
CM_ BU_ CMMa_PCE "Chassis Motion Module";
CM_ BU_ CGM3b_PCE "Communication Gateway  - Secondary";
CM_ BU_ ADIMa_PCE "Autonomous Drive Interface Module";
CM_ SG_ 344 CSS_CoPilotCibAvail "Indicates if the CIB function is currently operational";
CM_ SG_ 344 CSS_CoPilotSysFltStat "

";
CM_ SG_ 344 CSS_CoPilotRvbAvail "CoPilot RVB Available";
CM_ SG_ 344 CSS_CoPilotPcmAvail "Indicates if the PCM function is currently operational";
CM_ SG_ 344 CSS_CoPilotFcaAvail "Indicates if the FCA function is currentlay operational";
CM_ SG_ 344 CSS_CoPilotBrkExpctd "Is Emergency Braking function expected to be functioning";
BA_DEF_  "BusType" STRING ;
BA_DEF_ SG_  "VNSigSLHSSharedDiagnostic" ENUM  "No","Yes";
BA_DEF_ SG_  "SignalType" STRING ;
BA_DEF_ SG_  "PacketOrder" INT 0 65535;
BA_DEF_ SG_  "SignalLongName" STRING ;
BA_DEF_ SG_  "GenSigStartValue" INT 0 65535;
BA_DEF_ SG_  "VNSigAllNodes" ENUM  "No","Yes";
BA_DEF_ SG_  "GenSigSendType" ENUM  "not used","not used","not used","not used","not used","not used","not used","NoSigSendType","not used","not used","OnAnyChange","OnChangeIfActive","OnDelta";
BA_DEF_ SG_  "GenSigSendOnInit" ENUM  "Not Initialized","Application","Handler";
BA_DEF_ BO_  "AppGenMsgCycleTime" INT 0 0;
BA_DEF_ BO_  "GenMsgILSupport" ENUM  "No","Yes";
BA_DEF_ BO_  "TpApplType" STRING ;
BA_DEF_ BO_  "Prio" INT 0 7;
BA_DEF_ BO_  "MessageSubnet" ENUM  "LS","HS","CE","PE","HV","FO","LE","HE2","PHS","PCE","DLCLS","DLCHS","DLCCE","DLCFO";
BA_DEF_ BO_  "GenMsgMandatoryToSupervision" ENUM  "No","Yes";
BA_DEF_ BO_  "DiagState" ENUM  "No","Yes";
BA_DEF_ BO_  "GenMsgDelayTime" INT 0 100000;
BA_DEF_ BO_  "GenMsgCycleTime" INT 0 100000;
BA_DEF_ BO_  "GenMsgSendType" ENUM  "cyclicX","spontanX","cyclicIfActiveX","spontanWithDelay","cyclicAndSpontanX","cyclicAndSpontanWithDelay","spontanWithRepitition","cyclicIfActiveAndSpontanWD";
BA_DEF_ BO_  "DiagResponse" ENUM  "No","Yes";
BA_DEF_ BO_  "DiagRequest" ENUM  "No","Yes";
BA_DEF_ BO_  "NmMessage" ENUM  "No","Yes";
BA_DEF_ BU_  "MessageManagerUsed" ENUM  "No","Yes";
BA_DEF_ BU_  "NmNode" ENUM  "No","Yes";
BA_DEF_ BU_  "ILUsed" ENUM  "No","Yes";
BA_DEF_ BU_  "NodeLayerModules" STRING ;
BA_DEF_ BU_  "VNECUSLHSSharedDiagnostic" ENUM  "None","Activator","Remoted","Activator and Remoted","Shared Local";
BA_DEF_ BU_  "VNECUAllNodes" ENUM  "None","Activator","Remoted","Activator and Remoted","Shared Local";
BA_DEF_ BU_  "ECU_Id" HEX 0 255;
BA_DEF_ BU_  "SourceId" HEX 0 253;
BA_DEF_  "VersionMonth" INT 0 255;
BA_DEF_  "SyncJumpWidthMax" INT 0 255;
BA_DEF_  "SyncJumpWidthMin" INT 0 255;
BA_DEF_  "SamplePointMax" FLOAT 0 100;
BA_DEF_  "SamplePointMin" FLOAT 0 100;
BA_DEF_  "Baudrate" INT 0 1000000;
BA_DEF_  "VehicleArchitecture" STRING ;
BA_DEF_  "VNInitActSLHSSharedDiagnostic" ENUM  "No","Yes";
BA_DEF_  "VN_SLHSSharedDiagnostic" INT 0 255;
BA_DEF_  "VersionNumber" INT 0 65535;
BA_DEF_  "NmMessageCount" INT 0 32;
BA_DEF_  "NmBaseAddress" HEX 0 2032;
BA_DEF_  "NetworkType" STRING ;
BA_DEF_  "VNMFPeriodicInterval" INT 0 65535;
BA_DEF_  "BusWakeUpDelay" INT 0 65535;
BA_DEF_  "BusOffRecoveryTime" INT 0 65535;
BA_DEF_  "NodeStatusMsgID" HEX 0 536870911;
BA_DEF_  "NodeStatusMsgCycleTime" INT 0 65535;
BA_DEF_  "NodeStatusMsgTimeoutTime" INT 0 65535;
BA_DEF_  "UseGMParameterIDs" INT 0 1;
BA_DEF_  "VersionWeek" INT 0 255;
BA_DEF_  "VersionYear" INT 0 255;
BA_DEF_  "VN_AllNodes" INT 0 255;
BA_DEF_  "Manufacturer" ENUM  "DBAG","VAG","BMW","PAG","GM";
BA_DEF_  "NmType" STRING ;
BA_DEF_REL_ BU_SG_REL_  "GenSigSuprvRespComment" STRING ;
BA_DEF_REL_ BU_SG_REL_  "GenSigVBitResp" ENUM  "No","Yes";
BA_DEF_REL_ BU_SG_REL_  "GenSigVBitRespComment" STRING ;
BA_DEF_REL_ BU_SG_REL_  "GenSigVDAFailComment" STRING ;
BA_DEF_REL_ BU_SG_REL_  "GenSigVDAFailResp" ENUM  "No","Yes";
BA_DEF_REL_ BU_SG_REL_  "GenSigRxStartValue" STRING ;
BA_DEF_REL_ BU_SG_REL_  "GenSigSuprvResp" ENUM  "None","Notify App","Substitute Default";
BA_DEF_REL_ BU_SG_REL_  "GenSigTimeoutMsg" HEX 0 268435455;
BA_DEF_REL_ BU_SG_REL_  "GenSigTimeoutTime" INT 0 15000;
BA_DEF_DEF_  "BusType" "";
BA_DEF_DEF_  "VNSigSLHSSharedDiagnostic" "No";
BA_DEF_DEF_  "SignalType" "";
BA_DEF_DEF_  "PacketOrder" 0;
BA_DEF_DEF_  "SignalLongName" "";
BA_DEF_DEF_  "GenSigStartValue" 0;
BA_DEF_DEF_  "VNSigAllNodes" "No";
BA_DEF_DEF_  "GenSigSendType" "NoSigSendType";
BA_DEF_DEF_  "GenSigSendOnInit" "Not Initialized";
BA_DEF_DEF_  "AppGenMsgCycleTime" 0;
BA_DEF_DEF_  "GenMsgILSupport" "Yes";
BA_DEF_DEF_  "TpApplType" "";
BA_DEF_DEF_  "Prio" 4;
BA_DEF_DEF_  "MessageSubnet" "LS";
BA_DEF_DEF_  "GenMsgMandatoryToSupervision" "No";
BA_DEF_DEF_  "DiagState" "No";
BA_DEF_DEF_  "GenMsgDelayTime" 0;
BA_DEF_DEF_  "GenMsgCycleTime" 0;
BA_DEF_DEF_  "GenMsgSendType" "spontanX";
BA_DEF_DEF_  "DiagResponse" "No";
BA_DEF_DEF_  "DiagRequest" "No";
BA_DEF_DEF_  "NmMessage" "No";
BA_DEF_DEF_REL_ "GenSigSuprvRespComment" "";
BA_DEF_DEF_REL_ "GenSigVBitResp" "No";
BA_DEF_DEF_REL_ "GenSigVBitRespComment" "";
BA_DEF_DEF_REL_ "GenSigVDAFailComment" "";
BA_DEF_DEF_REL_ "GenSigVDAFailResp" "No";
BA_DEF_DEF_REL_ "GenSigRxStartValue" "";
BA_DEF_DEF_REL_ "GenSigSuprvResp" "None";
BA_DEF_DEF_REL_ "GenSigTimeoutMsg" 0;
BA_DEF_DEF_REL_ "GenSigTimeoutTime" 0;
BA_DEF_DEF_  "MessageManagerUsed" "Yes";
BA_DEF_DEF_  "NmNode" "Yes";
BA_DEF_DEF_  "ILUsed" "Yes";
BA_DEF_DEF_  "NodeLayerModules" "gmlan02.dll";
BA_DEF_DEF_  "VNECUSLHSSharedDiagnostic" "None";
BA_DEF_DEF_  "VNECUAllNodes" "None";
BA_DEF_DEF_  "ECU_Id" 0;
BA_DEF_DEF_  "SourceId" 0;
BA_DEF_DEF_  "VersionMonth" 0;
BA_DEF_DEF_  "SyncJumpWidthMax" 0;
BA_DEF_DEF_  "SyncJumpWidthMin" 0;
BA_DEF_DEF_  "SamplePointMax" 0;
BA_DEF_DEF_  "SamplePointMin" 0;
BA_DEF_DEF_  "Baudrate" 0;
BA_DEF_DEF_  "VehicleArchitecture" "";
BA_DEF_DEF_  "VNInitActSLHSSharedDiagnostic" "No";
BA_DEF_DEF_  "VN_SLHSSharedDiagnostic" 0;
BA_DEF_DEF_  "VersionNumber" 0;
BA_DEF_DEF_  "NmMessageCount" 32;
BA_DEF_DEF_  "NmBaseAddress" 1568;
BA_DEF_DEF_  "NetworkType" "";
BA_DEF_DEF_  "VNMFPeriodicInterval" 3000;
BA_DEF_DEF_  "BusWakeUpDelay" 100;
BA_DEF_DEF_  "BusOffRecoveryTime" 0;
BA_DEF_DEF_  "NodeStatusMsgID" 268427264;
BA_DEF_DEF_  "NodeStatusMsgCycleTime" 1200;
BA_DEF_DEF_  "NodeStatusMsgTimeoutTime" 0;
BA_DEF_DEF_  "UseGMParameterIDs" 1;
BA_DEF_DEF_  "VersionWeek" 0;
BA_DEF_DEF_  "VersionYear" 0;
BA_DEF_DEF_  "VN_AllNodes" 1;
BA_DEF_DEF_  "Manufacturer" "GM";
BA_DEF_DEF_  "NmType" "GMLAN";
BA_ "VersionMonth" 19;
BA_ "SyncJumpWidthMax" 4;
BA_ "SyncJumpWidthMin" 3;
BA_ "SamplePointMax" 81.25;
BA_ "SamplePointMin" 80;
BA_ "Baudrate" 500000;
BA_ "VehicleArchitecture" "Autonomous";
BA_ "VNInitActSLHSSharedDiagnostic" 1;
BA_ "NmMessageCount" 16;
BA_ "NmBaseAddress" 1536;
BA_ "NetworkType" "Powertrain";
BA_ "BusOffRecoveryTime" 160;
BA_ "NodeStatusMsgID" 0;
BA_ "UseGMParameterIDs" 0;
BA_ "VersionWeek" 38;
BA_ "VersionYear" 19;
BA_ "BusType" "CAN";
BA_ "VNECUSLHSSharedDiagnostic" BU_ Dummy_PCE 4;
BA_ "VNECUAllNodes" BU_ Dummy_PCE 4;
BA_ "VNECUSLHSSharedDiagnostic" BU_ EBOOST_OBD_PCE 4;
BA_ "VNECUAllNodes" BU_ EBOOST_OBD_PCE 4;
BA_ "ECU_Id" BU_ EBOOST_OBD_PCE 20;
BA_ "SourceId" BU_ EBOOST_OBD_PCE 43;
BA_ "VNECUSLHSSharedDiagnostic" BU_ EOCM2cp_K2_PCE 4;
BA_ "VNECUAllNodes" BU_ EOCM2cp_K2_PCE 4;
BA_ "ECU_Id" BU_ EOCM2cp_K2_PCE 11;
BA_ "SourceId" BU_ EOCM2cp_K2_PCE 219;
BA_ "VNECUSLHSSharedDiagnostic" BU_ EPSb_PCE 4;
BA_ "VNECUAllNodes" BU_ EPSb_PCE 4;
BA_ "ECU_Id" BU_ EPSb_PCE 10;
BA_ "SourceId" BU_ EPSb_PCE 48;
BA_ "VNECUSLHSSharedDiagnostic" BU_ SDM_PCE 4;
BA_ "VNECUAllNodes" BU_ SDM_PCE 4;
BA_ "ECU_Id" BU_ SDM_PCE 7;
BA_ "SourceId" BU_ SDM_PCE 88;
BA_ "VNECUSLHSSharedDiagnostic" BU_ EBCM_PCE 4;
BA_ "VNECUAllNodes" BU_ EBCM_PCE 4;
BA_ "ECU_Id" BU_ EBCM_PCE 3;
BA_ "SourceId" BU_ EBCM_PCE 40;
BA_ "VNECUSLHSSharedDiagnostic" BU_ EPSa_PCE 4;
BA_ "VNECUAllNodes" BU_ EPSa_PCE 4;
BA_ "ECU_Id" BU_ EPSa_PCE 2;
BA_ "SourceId" BU_ EPSa_PCE 49;
BA_ "VNECUSLHSSharedDiagnostic" BU_ CMMb_PCE 4;
BA_ "VNECUAllNodes" BU_ CMMb_PCE 4;
BA_ "ECU_Id" BU_ CMMb_PCE 22;
BA_ "SourceId" BU_ CMMb_PCE 62;
BA_ "VNECUSLHSSharedDiagnostic" BU_ CMMa_PCE 4;
BA_ "VNECUAllNodes" BU_ CMMa_PCE 4;
BA_ "ECU_Id" BU_ CMMa_PCE 27;
BA_ "SourceId" BU_ CMMa_PCE 61;
BA_ "VNECUSLHSSharedDiagnostic" BU_ CGM3b_PCE 4;
BA_ "VNECUAllNodes" BU_ CGM3b_PCE 4;
BA_ "ECU_Id" BU_ CGM3b_PCE 29;
BA_ "SourceId" BU_ CGM3b_PCE 72;
BA_ "VNECUSLHSSharedDiagnostic" BU_ ADIMa_PCE 4;
BA_ "VNECUAllNodes" BU_ ADIMa_PCE 4;
BA_ "ECU_Id" BU_ ADIMa_PCE 23;
BA_ "SourceId" BU_ ADIMa_PCE 9;
BA_ "Prio" BO_ 323 0;
BA_ "MessageSubnet" BO_ 323 9;
BA_ "GenMsgMandatoryToSupervision" BO_ 323 1;
BA_ "GenMsgCycleTime" BO_ 323 100;
BA_ "GenMsgSendType" BO_ 323 0;
BA_ "Prio" BO_ 356 0;
BA_ "MessageSubnet" BO_ 356 9;
BA_ "GenMsgMandatoryToSupervision" BO_ 356 1;
BA_ "GenMsgCycleTime" BO_ 356 100;
BA_ "GenMsgSendType" BO_ 356 0;
BA_ "Prio" BO_ 291 0;
BA_ "MessageSubnet" BO_ 291 9;
BA_ "GenMsgMandatoryToSupervision" BO_ 291 1;
BA_ "GenMsgCycleTime" BO_ 291 100;
BA_ "GenMsgSendType" BO_ 291 0;
BA_ "Prio" BO_ 211 0;
BA_ "MessageSubnet" BO_ 211 9;
BA_ "GenMsgCycleTime" BO_ 211 12;
BA_ "GenMsgSendType" BO_ 211 0;
BA_ "Prio" BO_ 1010 0;
BA_ "MessageSubnet" BO_ 1010 9;
BA_ "GenMsgCycleTime" BO_ 1010 100;
BA_ "GenMsgSendType" BO_ 1010 0;
BA_ "Prio" BO_ 1620 0;
BA_ "MessageSubnet" BO_ 1620 9;
BA_ "DiagResponse" BO_ 1620 1;
BA_ "Prio" BO_ 1611 0;
BA_ "MessageSubnet" BO_ 1611 9;
BA_ "DiagResponse" BO_ 1611 1;
BA_ "Prio" BO_ 584 0;
BA_ "MessageSubnet" BO_ 584 9;
BA_ "DiagRequest" BO_ 584 1;
BA_ "GenMsgILSupport" BO_ 587 0;
BA_ "Prio" BO_ 587 0;
BA_ "MessageSubnet" BO_ 587 9;
BA_ "DiagRequest" BO_ 587 1;
BA_ "Prio" BO_ 407 0;
BA_ "MessageSubnet" BO_ 407 9;
BA_ "GenMsgCycleTime" BO_ 407 20;
BA_ "GenMsgSendType" BO_ 407 0;
BA_ "MessageSubnet" BO_ 313 9;
BA_ "GenMsgCycleTime" BO_ 313 10;
BA_ "GenMsgSendType" BO_ 313 0;
BA_ "Prio" BO_ 406 0;
BA_ "MessageSubnet" BO_ 406 9;
BA_ "GenMsgCycleTime" BO_ 406 20;
BA_ "GenMsgSendType" BO_ 406 0;
BA_ "Prio" BO_ 312 0;
BA_ "MessageSubnet" BO_ 312 9;
BA_ "GenMsgCycleTime" BO_ 312 10;
BA_ "GenMsgSendType" BO_ 312 0;
BA_ "MessageSubnet" BO_ 404 9;
BA_ "GenMsgCycleTime" BO_ 404 20;
BA_ "GenMsgSendType" BO_ 404 0;
BA_ "Prio" BO_ 596 0;
BA_ "MessageSubnet" BO_ 596 9;
BA_ "DiagRequest" BO_ 596 1;
BA_ "Prio" BO_ 310 0;
BA_ "MessageSubnet" BO_ 310 9;
BA_ "GenMsgCycleTime" BO_ 310 10;
BA_ "GenMsgSendType" BO_ 310 0;
BA_ "Prio" BO_ 341 0;
BA_ "MessageSubnet" BO_ 341 9;
BA_ "GenMsgCycleTime" BO_ 341 10;
BA_ "GenMsgSendType" BO_ 341 0;
BA_ "Prio" BO_ 403 0;
BA_ "MessageSubnet" BO_ 403 9;
BA_ "GenMsgCycleTime" BO_ 403 20;
BA_ "GenMsgSendType" BO_ 403 0;
BA_ "Prio" BO_ 349 0;
BA_ "MessageSubnet" BO_ 349 9;
BA_ "GenMsgCycleTime" BO_ 349 10;
BA_ "GenMsgSendType" BO_ 349 0;
BA_ "Prio" BO_ 402 0;
BA_ "MessageSubnet" BO_ 402 9;
BA_ "GenMsgCycleTime" BO_ 402 20;
BA_ "GenMsgSendType" BO_ 402 0;
BA_ "Prio" BO_ 346 0;
BA_ "MessageSubnet" BO_ 346 9;
BA_ "GenMsgCycleTime" BO_ 346 10;
BA_ "GenMsgSendType" BO_ 346 0;
BA_ "Prio" BO_ 1627 0;
BA_ "MessageSubnet" BO_ 1627 9;
BA_ "DiagResponse" BO_ 1627 1;
BA_ "Prio" BO_ 1623 0;
BA_ "MessageSubnet" BO_ 1623 9;
BA_ "DiagResponse" BO_ 1623 1;
BA_ "MessageSubnet" BO_ 344 9;
BA_ "GenMsgCycleTime" BO_ 344 10;
BA_ "GenMsgSendType" BO_ 344 0;
BA_ "MessageSubnet" BO_ 531 9;
BA_ "GenMsgCycleTime" BO_ 531 20;
BA_ "GenMsgSendType" BO_ 531 0;
BA_ "Prio" BO_ 235 0;
BA_ "MessageSubnet" BO_ 235 9;
BA_ "GenMsgCycleTime" BO_ 235 10;
BA_ "GenMsgSendType" BO_ 235 0;
BA_ "GenMsgILSupport" BO_ 1366 0;
BA_ "TpApplType" BO_ 1366 "DiagUUDTResponse";
BA_ "Prio" BO_ 1366 0;
BA_ "MessageSubnet" BO_ 1366 9;
BA_ "Prio" BO_ 342 0;
BA_ "MessageSubnet" BO_ 342 9;
BA_ "GenMsgCycleTime" BO_ 342 10;
BA_ "GenMsgSendType" BO_ 342 0;
BA_ "Prio" BO_ 354 0;
BA_ "MessageSubnet" BO_ 354 9;
BA_ "GenMsgCycleTime" BO_ 354 10;
BA_ "GenMsgSendType" BO_ 354 0;
BA_ "SignalType" SG_ 323 EBOOSTBtryVtgChksum "UNM";
BA_ "SignalLongName" SG_ 323 EBOOSTBtryVtgChksum "EBOOST Battery Voltage Status Checksum";
BA_ "VNSigAllNodes" SG_ 323 EBOOSTBtryVtgChksum 1;
BA_ "SignalType" SG_ 323 EBOOSTBtryVtgARC "UNM";
BA_ "SignalLongName" SG_ 323 EBOOSTBtryVtgARC "EBOOST Battery Voltage Status Alive Rolling Count";
BA_ "VNSigAllNodes" SG_ 323 EBOOSTBtryVtgARC 1;
BA_ "SignalType" SG_ 323 EBOOSTBtryVtgAvgV "ENM";
BA_ "SignalLongName" SG_ 323 EBOOSTBtryVtgAvgV "EBOOST Battery Voltage Average Validity";
BA_ "VNSigAllNodes" SG_ 323 EBOOSTBtryVtgAvgV 1;
BA_ "SignalType" SG_ 323 EBOOSTBtryVtgAvg "UNM";
BA_ "SignalLongName" SG_ 323 EBOOSTBtryVtgAvg "EBOOST Battery Voltage Average";
BA_ "VNSigAllNodes" SG_ 323 EBOOSTBtryVtgAvg 1;
BA_ "SignalType" SG_ 356 EBCMBtryVtgARC "UNM";
BA_ "SignalLongName" SG_ 356 EBCMBtryVtgARC "EBCM Battery Voltage Status Alive Rolling Count";
BA_ "VNSigAllNodes" SG_ 356 EBCMBtryVtgARC 1;
BA_ "SignalType" SG_ 356 EBCMBtryVtgChksum "UNM";
BA_ "SignalLongName" SG_ 356 EBCMBtryVtgChksum "EBCM Battery Voltage Status Checksum";
BA_ "VNSigAllNodes" SG_ 356 EBCMBtryVtgChksum 1;
BA_ "SignalType" SG_ 356 EBCMBtryVtgAvgV "ENM";
BA_ "SignalLongName" SG_ 356 EBCMBtryVtgAvgV "EBCM Battery Voltage Average Validity";
BA_ "VNSigAllNodes" SG_ 356 EBCMBtryVtgAvgV 1;
BA_ "SignalType" SG_ 356 EBCMBtryVtgAvg "UNM";
BA_ "SignalLongName" SG_ 356 EBCMBtryVtgAvg "EBCM Battery Voltage Average";
BA_ "VNSigAllNodes" SG_ 356 EBCMBtryVtgAvg 1;
BA_ "SignalType" SG_ 291 EPSBtryVtgARC "UNM";
BA_ "SignalLongName" SG_ 291 EPSBtryVtgARC "EPS Battery Voltage Status Alive Rolling Count";
BA_ "VNSigAllNodes" SG_ 291 EPSBtryVtgARC 1;
BA_ "SignalType" SG_ 291 EPSaBtryVtgChksum "UNM";
BA_ "SignalLongName" SG_ 291 EPSaBtryVtgChksum "EPS Battery Voltage Status Checksum";
BA_ "VNSigAllNodes" SG_ 291 EPSaBtryVtgChksum 1;
BA_ "SignalType" SG_ 291 EPSBBtryVtgAvgV "ENM";
BA_ "SignalLongName" SG_ 291 EPSBBtryVtgAvgV "EPS B Battery Voltage Average Validity";
BA_ "VNSigAllNodes" SG_ 291 EPSBBtryVtgAvgV 1;
BA_ "SignalType" SG_ 291 EPSbBtryVtgAvg "UNM";
BA_ "SignalLongName" SG_ 291 EPSbBtryVtgAvg "EPS B Battery Voltage Average";
BA_ "VNSigAllNodes" SG_ 291 EPSbBtryVtgAvg 1;
BA_ "SignalType" SG_ 291 EPSaBtryVtgAvgV "ENM";
BA_ "SignalLongName" SG_ 291 EPSaBtryVtgAvgV "EPS A Battery Voltage Average Validity";
BA_ "VNSigAllNodes" SG_ 291 EPSaBtryVtgAvgV 1;
BA_ "SignalType" SG_ 291 EPSaBtryVtgAvg "UNM";
BA_ "SignalLongName" SG_ 291 EPSaBtryVtgAvg "EPS A Battery Voltage Average";
BA_ "VNSigAllNodes" SG_ 291 EPSaBtryVtgAvg 1;
BA_ "SignalType" SG_ 211 MtrRslvrPstnChksm "UNM";
BA_ "SignalLongName" SG_ 211 MtrRslvrPstnChksm "Motor Resolver Position Checksum";
BA_ "VNSigAllNodes" SG_ 211 MtrRslvrPstnChksm 1;
BA_ "SignalType" SG_ 211 MtrRslvrPstnARC "UNM";
BA_ "SignalLongName" SG_ 211 MtrRslvrPstnARC "Motor Resolver Position Alive Rolling Count";
BA_ "VNSigAllNodes" SG_ 211 MtrRslvrPstnARC 1;
BA_ "SignalType" SG_ 211 MtrRslvrWhlSpd "UNM";
BA_ "SignalLongName" SG_ 211 MtrRslvrWhlSpd "Motor Resolver Based Wheel Velocity";
BA_ "GenSigStartValue" SG_ 211 MtrRslvrWhlSpd 2978.90909090909;
BA_ "VNSigAllNodes" SG_ 211 MtrRslvrWhlSpd 1;
BA_ "SignalType" SG_ 211 MtrRslvrAvgDrvWhlPstnV "ENM";
BA_ "SignalLongName" SG_ 211 MtrRslvrAvgDrvWhlPstnV "Motor Resolver Average Drive Wheel Position Validity";
BA_ "VNSigAllNodes" SG_ 211 MtrRslvrAvgDrvWhlPstnV 1;
BA_ "SignalType" SG_ 211 MtrRslvrAvgDrvWhlPstn "UNM";
BA_ "SignalLongName" SG_ 211 MtrRslvrAvgDrvWhlPstn "Motor Resolver Average Drive Wheel Position";
BA_ "VNSigAllNodes" SG_ 211 MtrRslvrAvgDrvWhlPstn 1;
BA_ "SignalType" SG_ 1010 SecuredVehSpdSrcDrvnRed "ENM";
BA_ "SignalLongName" SG_ 1010 SecuredVehSpdSrcDrvnRed "Secured Vehicle Speed Source Driven Redundant";
BA_ "VNSigAllNodes" SG_ 1010 SecuredVehSpdSrcDrvnRed 1;
BA_ "SignalType" SG_ 1010 SecuredVehSpdRedChcksm "UNM";
BA_ "SignalLongName" SG_ 1010 SecuredVehSpdRedChcksm "Secured Vehicle Speed Redundant Checksum";
BA_ "VNSigAllNodes" SG_ 1010 SecuredVehSpdRedChcksm 1;
BA_ "SignalType" SG_ 1010 SecuredVehSpdRedARC "UNM";
BA_ "SignalLongName" SG_ 1010 SecuredVehSpdRedARC "Secured Vehicle Speed Redundant Alive Rolling Count";
BA_ "VNSigAllNodes" SG_ 1010 SecuredVehSpdRedARC 1;
BA_ "SignalType" SG_ 1010 SecuredVehSpdAvlblDrvnRed "BLN";
BA_ "SignalLongName" SG_ 1010 SecuredVehSpdAvlblDrvnRed "Secured Vehicle Speed Available Driven Redundant";
BA_ "VNSigAllNodes" SG_ 1010 SecuredVehSpdAvlblDrvnRed 1;
BA_ "SignalType" SG_ 1010 SecuredVehSpdDrvnRedV "ENM";
BA_ "SignalLongName" SG_ 1010 SecuredVehSpdDrvnRedV "Secured Vehicle Speed  Driven Redundant Validity";
BA_ "VNSigAllNodes" SG_ 1010 SecuredVehSpdDrvnRedV 1;
BA_ "SignalType" SG_ 1010 SecuredVehSpdDrvnRed "UNM";
BA_ "SignalLongName" SG_ 1010 SecuredVehSpdDrvnRed "Secured Vehicle Speed Driven Redundant";
BA_ "VNSigAllNodes" SG_ 1010 SecuredVehSpdDrvnRed 1;
BA_ "VNSigSLHSSharedDiagnostic" SG_ 1620 DgnInf 1;
BA_ "SignalType" SG_ 1620 DgnInf "UNM";
BA_ "SignalLongName" SG_ 1620 DgnInf "Diagnostic Information";
BA_ "VNSigAllNodes" SG_ 1620 DgnInf 1;
BA_ "VNSigSLHSSharedDiagnostic" SG_ 1611 DgnInf 1;
BA_ "SignalType" SG_ 1611 DgnInf "UNM";
BA_ "SignalLongName" SG_ 1611 DgnInf "Diagnostic Information";
BA_ "VNSigAllNodes" SG_ 1611 DgnInf 1;
BA_ "VNSigSLHSSharedDiagnostic" SG_ 584 DgnInf 1;
BA_ "SignalType" SG_ 584 DgnInf "UNM";
BA_ "SignalLongName" SG_ 584 DgnInf "Diagnostic Information";
BA_ "VNSigAllNodes" SG_ 584 DgnInf 1;
BA_ "VNSigSLHSSharedDiagnostic" SG_ 587 DgnInf 1;
BA_ "SignalType" SG_ 587 DgnInf "UNM";
BA_ "SignalLongName" SG_ 587 DgnInf "Diagnostic Information";
BA_ "VNSigAllNodes" SG_ 587 DgnInf 1;
BA_ "SignalType" SG_ 407 BrkPedDrvOvrdDtdESC "ENM";
BA_ "SignalLongName" SG_ 407 BrkPedDrvOvrdDtdESC "Brake Pedal Driver Override Detected by ESC";
BA_ "GenSigStartValue" SG_ 407 BrkPedDrvOvrdDtdESC 3;
BA_ "VNSigAllNodes" SG_ 407 BrkPedDrvOvrdDtdESC 1;
BA_ "SignalType" SG_ 407 VrtlMstCylPrsQlfr "ENM";
BA_ "SignalLongName" SG_ 407 VrtlMstCylPrsQlfr "Virtual Master Cylinder Pressure Qualifier";
BA_ "VNSigAllNodes" SG_ 407 VrtlMstCylPrsQlfr 1;
BA_ "SignalType" SG_ 407 VrtlMstCylPrs "UNM";
BA_ "SignalLongName" SG_ 407 VrtlMstCylPrs "Virtual Master Cylinder Pressure";
BA_ "VNSigAllNodes" SG_ 407 VrtlMstCylPrs 1;
BA_ "SignalType" SG_ 407 BrkFldLvlLw197V "ENM";
BA_ "SignalLongName" SG_ 407 BrkFldLvlLw197V "Brake Fluid Level Low 197 Validity";
BA_ "VNSigAllNodes" SG_ 407 BrkFldLvlLw197V 1;
BA_ "SignalType" SG_ 407 BrkFldLvlLw197 "BLN";
BA_ "SignalLongName" SG_ 407 BrkFldLvlLw197 "Brake Fluid Level Low 197";
BA_ "VNSigAllNodes" SG_ 407 BrkFldLvlLw197 1;
BA_ "SignalType" SG_ 407 ExtBrkReq2Chksm "UNM";
BA_ "SignalLongName" SG_ 407 ExtBrkReq2Chksm "External Brake Request 2 Checksum";
BA_ "VNSigAllNodes" SG_ 407 ExtBrkReq2Chksm 1;
BA_ "SignalType" SG_ 407 ExtBrkReq2ARC "UNM";
BA_ "SignalLongName" SG_ 407 ExtBrkReq2ARC "External Brake Request 2 Alive Rolling Count";
BA_ "VNSigAllNodes" SG_ 407 ExtBrkReq2ARC 1;
BA_ "SignalType" SG_ 407 AxSnsrOffstLngTrmV "ENM";
BA_ "SignalLongName" SG_ 407 AxSnsrOffstLngTrmV "Ax Sensor Offset Long Term Validity";
BA_ "VNSigAllNodes" SG_ 407 AxSnsrOffstLngTrmV 1;
BA_ "SignalType" SG_ 407 AxSnsrOffstLngTrm "UNM";
BA_ "SignalLongName" SG_ 407 AxSnsrOffstLngTrm "Ax Sensor Offset Long Term";
BA_ "GenSigStartValue" SG_ 407 AxSnsrOffstLngTrm 59;
BA_ "VNSigAllNodes" SG_ 407 AxSnsrOffstLngTrm 1;
BA_ "SignalType" SG_ 313 ActrBrkFldFlwReqStat "ENM";
BA_ "SignalLongName" SG_ 313 ActrBrkFldFlwReqStat "Actuator Brake Fluid Flow Request Status";
BA_ "VNSigAllNodes" SG_ 313 ActrBrkFldFlwReqStat 1;
BA_ "SignalType" SG_ 313 ActrBrkFldFlwReq "UNM";
BA_ "SignalLongName" SG_ 313 ActrBrkFldFlwReq "Actuator Brake Fluid Flow Request";
BA_ "GenSigStartValue" SG_ 313 ActrBrkFldFlwReq 32768;
BA_ "VNSigAllNodes" SG_ 313 ActrBrkFldFlwReq 1;
BA_ "SignalType" SG_ 313 ABSAtv139 "BLN";
BA_ "SignalLongName" SG_ 313 ABSAtv139 "Antilock Brake System Active 139";
BA_ "VNSigAllNodes" SG_ 313 ABSAtv139 1;
BA_ "SignalType" SG_ 313 MstCylPrsCrct1Stat "ENM";
BA_ "SignalLongName" SG_ 313 MstCylPrsCrct1Stat "Master Cylinder Pressure Circuit 1 Status";
BA_ "VNSigAllNodes" SG_ 313 MstCylPrsCrct1Stat 1;
BA_ "SignalType" SG_ 313 MstCylPrsCrct1 "UNM";
BA_ "SignalLongName" SG_ 313 MstCylPrsCrct1 "Master Cylinder Pressure Circuit 1";
BA_ "VNSigAllNodes" SG_ 313 MstCylPrsCrct1 1;
BA_ "SignalType" SG_ 313 ExtBrkReq1Chksm "UNM";
BA_ "SignalLongName" SG_ 313 ExtBrkReq1Chksm "External Brake Request 1 Checksum";
BA_ "VNSigAllNodes" SG_ 313 ExtBrkReq1Chksm 1;
BA_ "SignalType" SG_ 313 ExtBrkReq1ARC "UNM";
BA_ "SignalLongName" SG_ 313 ExtBrkReq1ARC "External Brake Request 1 Alive Rolling Count";
BA_ "VNSigAllNodes" SG_ 313 ExtBrkReq1ARC 1;
BA_ "SignalType" SG_ 313 EBCMhydctrlAct "BLN";
BA_ "SignalLongName" SG_ 313 EBCMhydctrlAct "EBCM Hydraulic Control Active";
BA_ "VNSigAllNodes" SG_ 313 EBCMhydctrlAct 1;
BA_ "SignalType" SG_ 406 EstWhlBrkPrsStatRed "ENM";
BA_ "SignalLongName" SG_ 406 EstWhlBrkPrsStatRed "Estimated Wheel Brake Pressure Status Redundant";
BA_ "VNSigAllNodes" SG_ 406 EstWhlBrkPrsStatRed 1;
BA_ "SignalType" SG_ 406 EstWhlBrkPrsRRRed "UNM";
BA_ "SignalLongName" SG_ 406 EstWhlBrkPrsRRRed "Estimated Wheel Brake Pressure Right Rear Redundant";
BA_ "VNSigAllNodes" SG_ 406 EstWhlBrkPrsRRRed 1;
BA_ "SignalType" SG_ 406 EstWhlBrkPrsRFRed "UNM";
BA_ "SignalLongName" SG_ 406 EstWhlBrkPrsRFRed "Estimated Wheel Brake Pressure Right Front Redundant";
BA_ "VNSigAllNodes" SG_ 406 EstWhlBrkPrsRFRed 1;
BA_ "SignalType" SG_ 406 EstWhlBrkPrsLRRed "UNM";
BA_ "SignalLongName" SG_ 406 EstWhlBrkPrsLRRed "Estimated Wheel Brake Pressure Left Rear Redundant";
BA_ "VNSigAllNodes" SG_ 406 EstWhlBrkPrsLRRed 1;
BA_ "SignalType" SG_ 406 EstWhlBrkPrsLFRed "UNM";
BA_ "SignalLongName" SG_ 406 EstWhlBrkPrsLFRed "Estimated Wheel Brake Pressure Left Front Redundant";
BA_ "VNSigAllNodes" SG_ 406 EstWhlBrkPrsLFRed 1;
BA_ "SignalType" SG_ 406 BrkEstWhlPrsRedChksm "UNM";
BA_ "SignalLongName" SG_ 406 BrkEstWhlPrsRedChksm "Brake Estimated Wheel Pressure Redundant Checksum";
BA_ "VNSigAllNodes" SG_ 406 BrkEstWhlPrsRedChksm 1;
BA_ "SignalType" SG_ 406 BrkEstWhlPrsRedARC "UNM";
BA_ "SignalLongName" SG_ 406 BrkEstWhlPrsRedARC "Brake Estimated Wheel Pressure Redundant Alive Rolling Count";
BA_ "VNSigAllNodes" SG_ 406 BrkEstWhlPrsRedARC 1;
BA_ "SignalType" SG_ 312 PriCoPCmdMsgStat "ENM";
BA_ "SignalLongName" SG_ 312 PriCoPCmdMsgStat "Primary CoPilot Command Message Status";
BA_ "VNSigAllNodes" SG_ 312 PriCoPCmdMsgStat 1;
BA_ "SignalType" SG_ 312 PriADSCmdMsgStat "ENM";
BA_ "SignalLongName" SG_ 312 PriADSCmdMsgStat "Primary ADS Command Message Status";
BA_ "VNSigAllNodes" SG_ 312 PriADSCmdMsgStat 1;
BA_ "SignalType" SG_ 312 PriBrkSysArbStat "ENM";
BA_ "SignalLongName" SG_ 312 PriBrkSysArbStat "Primary Brake System Arbitration Status";
BA_ "VNSigAllNodes" SG_ 312 PriBrkSysArbStat 1;
BA_ "SignalType" SG_ 312 PriBrkSysStatChksm "UNM";
BA_ "SignalLongName" SG_ 312 PriBrkSysStatChksm "Primary Brake System Status Checksum";
BA_ "VNSigAllNodes" SG_ 312 PriBrkSysStatChksm 1;
BA_ "SignalType" SG_ 312 PriBrkSysStatARC "UNM";
BA_ "SignalLongName" SG_ 312 PriBrkSysStatARC "Primary Brake System Status Alive Rolling Count";
BA_ "VNSigAllNodes" SG_ 312 PriBrkSysStatARC 1;
BA_ "SignalType" SG_ 312 PriBrkSysStat "ENM";
BA_ "SignalLongName" SG_ 312 PriBrkSysStat "Primary Brake System Status";
BA_ "VNSigAllNodes" SG_ 312 PriBrkSysStat 1;
BA_ "SignalType" SG_ 312 PriBrkRngLmtgStat "ENM";
BA_ "SignalLongName" SG_ 312 PriBrkRngLmtgStat "Primary Brake Range Limiting Status";
BA_ "VNSigAllNodes" SG_ 312 PriBrkRngLmtgStat 1;
BA_ "SignalType" SG_ 312 PriBrkModSbSte "ENM";
BA_ "SignalLongName" SG_ 312 PriBrkModSbSte "Primary Brake Module Sub State";
BA_ "VNSigAllNodes" SG_ 312 PriBrkModSbSte 1;
BA_ "SignalType" SG_ 312 PriDrvIntvtnMdDetTO "BLN";
BA_ "SignalLongName" SG_ 312 PriDrvIntvtnMdDetTO "Primary Driver Intervention Mode Detection Timeout";
BA_ "VNSigAllNodes" SG_ 312 PriDrvIntvtnMdDetTO 1;
BA_ "SignalType" SG_ 312 PriBrkModCrtThrmlCap "UNM";
BA_ "SignalLongName" SG_ 312 PriBrkModCrtThrmlCap "Primary Brake Module Current Thermal Capacity";
BA_ "VNSigAllNodes" SG_ 312 PriBrkModCrtThrmlCap 1;
BA_ "SignalType" SG_ 404 SpltMuCntrlRedV "ENM";
BA_ "SignalLongName" SG_ 404 SpltMuCntrlRedV "Split Mu Control Redundant Validity";
BA_ "VNSigAllNodes" SG_ 404 SpltMuCntrlRedV 1;
BA_ "SignalType" SG_ 404 SpltMuCntrlRed "ENM";
BA_ "SignalLongName" SG_ 404 SpltMuCntrlRed "Split Mu Control Redundant";
BA_ "VNSigAllNodes" SG_ 404 SpltMuCntrlRed 1;
BA_ "SignalType" SG_ 404 PriMaxAvlBrkTrqGradRed "UNM";
BA_ "SignalLongName" SG_ 404 PriMaxAvlBrkTrqGradRed "Primary Maximum Available Brake Torque Gradient Redundant";
BA_ "VNSigAllNodes" SG_ 404 PriMaxAvlBrkTrqGradRed 1;
BA_ "SignalType" SG_ 404 PriMaxAvlBrkTrqRed "UNM";
BA_ "SignalLongName" SG_ 404 PriMaxAvlBrkTrqRed "Primary Maximum Available Brake Torque Redundant";
BA_ "GenSigStartValue" SG_ 404 PriMaxAvlBrkTrqRed 32767;
BA_ "VNSigAllNodes" SG_ 404 PriMaxAvlBrkTrqRed 1;
BA_ "SignalType" SG_ 404 PriEstSrfcMuTypRed "ENM";
BA_ "SignalLongName" SG_ 404 PriEstSrfcMuTypRed "Primary Estimated Surface Mu Type Redundant";
BA_ "VNSigAllNodes" SG_ 404 PriEstSrfcMuTypRed 1;
BA_ "SignalType" SG_ 404 PriEstSrfcMuCapRed "UNM";
BA_ "SignalLongName" SG_ 404 PriEstSrfcMuCapRed "Primary Estimated Surface Mu Capacity Redundant";
BA_ "VNSigAllNodes" SG_ 404 PriEstSrfcMuCapRed 1;
BA_ "SignalType" SG_ 404 PriBrkSystCapRedChksm "UNM";
BA_ "SignalLongName" SG_ 404 PriBrkSystCapRedChksm "Primary Brake System Capability Redundant Checksum";
BA_ "VNSigAllNodes" SG_ 404 PriBrkSystCapRedChksm 1;
BA_ "SignalType" SG_ 404 PriBrkSysCapRedARC "UNM";
BA_ "SignalLongName" SG_ 404 PriBrkSysCapRedARC "Primary Brake System Capability Redundant Alive Rolling Count";
BA_ "VNSigAllNodes" SG_ 404 PriBrkSysCapRedARC 1;
BA_ "SignalType" SG_ 404 PriBrkModCapStatRed "ENM";
BA_ "SignalLongName" SG_ 404 PriBrkModCapStatRed "Primary Brake Module Capability Status Redundant";
BA_ "VNSigAllNodes" SG_ 404 PriBrkModCapStatRed 1;
BA_ "VNSigSLHSSharedDiagnostic" SG_ 596 DgnInf 1;
BA_ "SignalType" SG_ 596 DgnInf "UNM";
BA_ "SignalLongName" SG_ 596 DgnInf "Diagnostic Information";
BA_ "VNSigAllNodes" SG_ 596 DgnInf 1;
BA_ "SignalType" SG_ 310 Diagpresreqstat "ENM";
BA_ "SignalLongName" SG_ 310 Diagpresreqstat "Diagnostic Pressure Request Status";
BA_ "VNSigAllNodes" SG_ 310 Diagpresreqstat 1;
BA_ "SignalType" SG_ 310 Diagpresreqavl "ENM";
BA_ "SignalLongName" SG_ 310 Diagpresreqavl "Diagnostic Pressure Request Available";
BA_ "VNSigAllNodes" SG_ 310 Diagpresreqavl 1;
BA_ "SignalType" SG_ 310 PriSuffBrkTrqStdstl "BLN";
BA_ "SignalLongName" SG_ 310 PriSuffBrkTrqStdstl "Primary Sufficient Brake Torque for Standstill";
BA_ "VNSigAllNodes" SG_ 310 PriSuffBrkTrqStdstl 1;
BA_ "SignalType" SG_ 310 PriAutoEstBrkTrqApd "UNM";
BA_ "SignalLongName" SG_ 310 PriAutoEstBrkTrqApd "Primary Autonomous Estimated Brake Torque Applied";
BA_ "GenSigStartValue" SG_ 310 PriAutoEstBrkTrqApd 32767;
BA_ "VNSigAllNodes" SG_ 310 PriAutoEstBrkTrqApd 1;
BA_ "SignalType" SG_ 310 PriAutoBrkSysDrInfcStat "ENM";
BA_ "SignalLongName" SG_ 310 PriAutoBrkSysDrInfcStat "Primary Autonomous Brake System Driver Interference Detected Status";
BA_ "VNSigAllNodes" SG_ 310 PriAutoBrkSysDrInfcStat 1;
BA_ "SignalType" SG_ 310 PriAutoArbBrkTrqReq "UNM";
BA_ "SignalLongName" SG_ 310 PriAutoArbBrkTrqReq "Primary Autonomous Arbitrated Brake Torque Request";
BA_ "GenSigStartValue" SG_ 310 PriAutoArbBrkTrqReq 32767;
BA_ "VNSigAllNodes" SG_ 310 PriAutoArbBrkTrqReq 1;
BA_ "SignalType" SG_ 310 PriBrkModStat "ENM";
BA_ "SignalLongName" SG_ 310 PriBrkModStat "Primary Brake Module Status";
BA_ "VNSigAllNodes" SG_ 310 PriBrkModStat 1;
BA_ "SignalType" SG_ 310 PriAutoAxlTrqReqStatChksm "UNM";
BA_ "SignalLongName" SG_ 310 PriAutoAxlTrqReqStatChksm "Primary Autonomous Axle Torque Request Status Checksum";
BA_ "VNSigAllNodes" SG_ 310 PriAutoAxlTrqReqStatChksm 1;
BA_ "SignalType" SG_ 310 PriAutoAxlTrqReqStatARC "UNM";
BA_ "SignalLongName" SG_ 310 PriAutoAxlTrqReqStatARC "Primary Autonomous Axle Torque Request Status Alive Rolling Count";
BA_ "VNSigAllNodes" SG_ 310 PriAutoAxlTrqReqStatARC 1;
BA_ "SignalType" SG_ 310 PriAutoEstBrkTrqAppStat "ENM";
BA_ "SignalLongName" SG_ 310 PriAutoEstBrkTrqAppStat "Primary Autonomous Estimated Brake Torque Applied Status";
BA_ "VNSigAllNodes" SG_ 310 PriAutoEstBrkTrqAppStat 1;
BA_ "SignalType" SG_ 341 Vltmtr "UNM";
BA_ "SignalLongName" SG_ 341 Vltmtr "Voltage at Motor";
BA_ "VNSigAllNodes" SG_ 341 Vltmtr 1;
BA_ "SignalType" SG_ 341 EstMtrTrq "UNM";
BA_ "SignalLongName" SG_ 341 EstMtrTrq "Estimated Motor Torque";
BA_ "VNSigAllNodes" SG_ 341 EstMtrTrq 1;
BA_ "SignalType" SG_ 341 ExtBrkReqRespChksm "UNM";
BA_ "SignalLongName" SG_ 341 ExtBrkReqRespChksm "External Brake Request Response Checksum";
BA_ "VNSigAllNodes" SG_ 341 ExtBrkReqRespChksm 1;
BA_ "SignalType" SG_ 341 ExtBrkReqRespARC "UNM";
BA_ "SignalLongName" SG_ 341 ExtBrkReqRespARC "External Brake Request Response Alive Rolling Count";
BA_ "VNSigAllNodes" SG_ 341 ExtBrkReqRespARC 1;
BA_ "SignalType" SG_ 341 PrkBrkReqiB "ENM";
BA_ "SignalLongName" SG_ 341 PrkBrkReqiB "Park Brake Request iBoost";
BA_ "VNSigAllNodes" SG_ 341 PrkBrkReqiB 1;
BA_ "SignalType" SG_ 341 ExtBrkReqStat "ENM";
BA_ "SignalLongName" SG_ 341 ExtBrkReqStat "External Brake Request Status";
BA_ "VNSigAllNodes" SG_ 341 ExtBrkReqStat 1;
BA_ "SignalType" SG_ 341 StrkOtptRodTgtQlfr "ENM";
BA_ "SignalLongName" SG_ 341 StrkOtptRodTgtQlfr "Stroke Output Rod Target Qualifier";
BA_ "VNSigAllNodes" SG_ 341 StrkOtptRodTgtQlfr 1;
BA_ "SignalType" SG_ 341 StrkOtptRodActlQlfr "ENM";
BA_ "SignalLongName" SG_ 341 StrkOtptRodActlQlfr "Stroke Output Rod Actual Qualifier";
BA_ "VNSigAllNodes" SG_ 341 StrkOtptRodActlQlfr 1;
BA_ "SignalType" SG_ 341 StrkOtptRodActl "UNM";
BA_ "SignalLongName" SG_ 341 StrkOtptRodActl "Stroke Output Rod Actual";
BA_ "VNSigAllNodes" SG_ 341 StrkOtptRodActl 1;
BA_ "SignalType" SG_ 341 StrkOtptRodTgt "UNM";
BA_ "SignalLongName" SG_ 341 StrkOtptRodTgt "Stroke Output Rod Target";
BA_ "VNSigAllNodes" SG_ 341 StrkOtptRodTgt 1;
BA_ "SignalType" SG_ 403 PedOvrdBrkiBst "ENM";
BA_ "SignalLongName" SG_ 403 PedOvrdBrkiBst "Pedal Override Brake iBooster";
BA_ "GenSigStartValue" SG_ 403 PedOvrdBrkiBst 3;
BA_ "VNSigAllNodes" SG_ 403 PedOvrdBrkiBst 1;
BA_ "SignalType" SG_ 403 iBstStat "ENM";
BA_ "SignalLongName" SG_ 403 iBstStat "iBooster Status";
BA_ "VNSigAllNodes" SG_ 403 iBstStat 1;
BA_ "SignalType" SG_ 403 HbcSptRedq "BLN";
BA_ "SignalLongName" SG_ 403 HbcSptRedq "Hbc Support Requested";
BA_ "VNSigAllNodes" SG_ 403 HbcSptRedq 1;
BA_ "SignalType" SG_ 403 eBstEspCompIdnx "UNM";
BA_ "SignalLongName" SG_ 403 eBstEspCompIdnx "eBooster Esp Compatibility Index";
BA_ "VNSigAllNodes" SG_ 403 eBstEspCompIdnx 1;
BA_ "SignalType" SG_ 403 eBstDiagAtv "BLN";
BA_ "SignalLongName" SG_ 403 eBstDiagAtv "eBooster Diagnostic Active";
BA_ "VNSigAllNodes" SG_ 403 eBstDiagAtv 1;
BA_ "SignalType" SG_ 403 EBstSteChksm "UNM";
BA_ "SignalLongName" SG_ 403 EBstSteChksm "EBoost State Checksum";
BA_ "VNSigAllNodes" SG_ 403 EBstSteChksm 1;
BA_ "SignalType" SG_ 403 EBstSteARC "UNM";
BA_ "SignalLongName" SG_ 403 EBstSteARC "EBoost State Alive Rolling Count";
BA_ "VNSigAllNodes" SG_ 403 EBstSteARC 1;
BA_ "SignalType" SG_ 403 EBstRnotPrsQlfr "ENM";
BA_ "SignalLongName" SG_ 403 EBstRnotPrsQlfr "Eboost Runout Pressure Qualifier";
BA_ "VNSigAllNodes" SG_ 403 EBstRnotPrsQlfr 1;
BA_ "SignalType" SG_ 403 EBstRnotPrs "UNM";
BA_ "SignalLongName" SG_ 403 EBstRnotPrs "Eboost Runout Pressure";
BA_ "VNSigAllNodes" SG_ 403 EBstRnotPrs 1;
BA_ "SignalType" SG_ 403 BrkPedApdQlfr "ENM";
BA_ "SignalLongName" SG_ 403 BrkPedApdQlfr "Brake Pedal Applied Qualifier";
BA_ "VNSigAllNodes" SG_ 403 BrkPedApdQlfr 1;
BA_ "SignalType" SG_ 403 BrkPedApd "BLN";
BA_ "SignalLongName" SG_ 403 BrkPedApd "Brake Pedal Applied";
BA_ "VNSigAllNodes" SG_ 403 BrkPedApd 1;
BA_ "SignalType" SG_ 349 SecCoPCmdMsgStatRed "ENM";
BA_ "SignalLongName" SG_ 349 SecCoPCmdMsgStatRed "Secondary CoPilot Command Message Status Redundant";
BA_ "VNSigAllNodes" SG_ 349 SecCoPCmdMsgStatRed 1;
BA_ "SignalType" SG_ 349 SecBrkSysArbStatRed "ENM";
BA_ "SignalLongName" SG_ 349 SecBrkSysArbStatRed "Secondary Brake System Arbitration Status Redundant";
BA_ "VNSigAllNodes" SG_ 349 SecBrkSysArbStatRed 1;
BA_ "SignalType" SG_ 349 SecADSCmdMsgStatRed "ENM";
BA_ "SignalLongName" SG_ 349 SecADSCmdMsgStatRed "Secondary ADS Command Message Status Redundant";
BA_ "VNSigAllNodes" SG_ 349 SecADSCmdMsgStatRed 1;
BA_ "SignalType" SG_ 349 SecBrkSysStatRedChksm "UNM";
BA_ "SignalLongName" SG_ 349 SecBrkSysStatRedChksm "Secondary Brake System Status Redundant Checksum";
BA_ "VNSigAllNodes" SG_ 349 SecBrkSysStatRedChksm 1;
BA_ "SignalType" SG_ 349 SecBrkSysStatRedARC "UNM";
BA_ "SignalLongName" SG_ 349 SecBrkSysStatRedARC "Secondary Brake System Status Redundant Alive Rolling Count";
BA_ "VNSigAllNodes" SG_ 349 SecBrkSysStatRedARC 1;
BA_ "SignalType" SG_ 349 SecBrkModSbSteRed "ENM";
BA_ "SignalLongName" SG_ 349 SecBrkModSbSteRed "Secondary Brake Module Sub State Redundant";
BA_ "VNSigAllNodes" SG_ 349 SecBrkModSbSteRed 1;
BA_ "SignalType" SG_ 349 SecBrkSysStatRed "ENM";
BA_ "SignalLongName" SG_ 349 SecBrkSysStatRed "Secondary Brake System Status Redundant";
BA_ "VNSigAllNodes" SG_ 349 SecBrkSysStatRed 1;
BA_ "SignalType" SG_ 349 SecBrkRngLmtgStatRed "ENM";
BA_ "SignalLongName" SG_ 349 SecBrkRngLmtgStatRed "Secondary Brake Range Limiting Status Redundant";
BA_ "VNSigAllNodes" SG_ 349 SecBrkRngLmtgStatRed 1;
BA_ "SignalType" SG_ 349 SecBrkModCrtThrmlCapRed "UNM";
BA_ "SignalLongName" SG_ 349 SecBrkModCrtThrmlCapRed "Secondary Brake Module Current Thermal Capacity Redundant";
BA_ "VNSigAllNodes" SG_ 349 SecBrkModCrtThrmlCapRed 1;
BA_ "SignalType" SG_ 349 SecDrvIntvtnMdDetTORed "BLN";
BA_ "SignalLongName" SG_ 349 SecDrvIntvtnMdDetTORed "Secondary Driver Intervention Mode Detection Timeout Redundant";
BA_ "VNSigAllNodes" SG_ 349 SecDrvIntvtnMdDetTORed 1;
BA_ "SignalType" SG_ 402 SecEstSrfcMuTypRed "ENM";
BA_ "SignalLongName" SG_ 402 SecEstSrfcMuTypRed "Secondary Estimated Surface Mu Type Redundant";
BA_ "VNSigAllNodes" SG_ 402 SecEstSrfcMuTypRed 1;
BA_ "SignalType" SG_ 402 SecEstSrfcMuCapRedV "ENM";
BA_ "SignalLongName" SG_ 402 SecEstSrfcMuCapRedV "Secondary Estimated Surface Mu Capacity Redundant Validity";
BA_ "VNSigAllNodes" SG_ 402 SecEstSrfcMuCapRedV 1;
BA_ "SignalType" SG_ 402 SecEstSrfcMuCapRed "UNM";
BA_ "SignalLongName" SG_ 402 SecEstSrfcMuCapRed "Secondary Estimated Surface Mu Capacity Redundant";
BA_ "VNSigAllNodes" SG_ 402 SecEstSrfcMuCapRed 1;
BA_ "SignalType" SG_ 402 SecBrkSystCapRedChksm "UNM";
BA_ "SignalLongName" SG_ 402 SecBrkSystCapRedChksm "Secondary Brake System Capability Redundant Checksum";
BA_ "VNSigAllNodes" SG_ 402 SecBrkSystCapRedChksm 1;
BA_ "SignalType" SG_ 402 SecBrkSysCapRedARC "UNM";
BA_ "SignalLongName" SG_ 402 SecBrkSysCapRedARC "Secondary Brake System Capability Redundant Alive Rolling Count";
BA_ "VNSigAllNodes" SG_ 402 SecBrkSysCapRedARC 1;
BA_ "SignalType" SG_ 402 SecBrkModCapRedStat "ENM";
BA_ "SignalLongName" SG_ 402 SecBrkModCapRedStat "Secondary Brake Module Capability Redundant Status";
BA_ "VNSigAllNodes" SG_ 402 SecBrkModCapRedStat 1;
BA_ "SignalType" SG_ 402 SecMaxAvlBrkTrqRed "UNM";
BA_ "SignalLongName" SG_ 402 SecMaxAvlBrkTrqRed "Secondary Maximum Available Brake Torque Redundant";
BA_ "GenSigStartValue" SG_ 402 SecMaxAvlBrkTrqRed 32767;
BA_ "VNSigAllNodes" SG_ 402 SecMaxAvlBrkTrqRed 1;
BA_ "SignalType" SG_ 402 SecMaxAvlBrkTrqGradRed "UNM";
BA_ "SignalLongName" SG_ 402 SecMaxAvlBrkTrqGradRed "Secondary Maximum Available Brake Torque Gradient Redundant";
BA_ "VNSigAllNodes" SG_ 402 SecMaxAvlBrkTrqGradRed 1;
BA_ "SignalType" SG_ 346 SecAutoAxlTrqReqStatChksm "UNM";
BA_ "SignalLongName" SG_ 346 SecAutoAxlTrqReqStatChksm "Secondary Autonomous Axle Torque Request Status Checksum";
BA_ "VNSigAllNodes" SG_ 346 SecAutoAxlTrqReqStatChksm 1;
BA_ "SignalType" SG_ 346 SecAutoAxlTrqReqStatARC "UNM";
BA_ "SignalLongName" SG_ 346 SecAutoAxlTrqReqStatARC "Secondary Autonomous Axle Torque Request Status Alive Rolling Count";
BA_ "VNSigAllNodes" SG_ 346 SecAutoAxlTrqReqStatARC 1;
BA_ "SignalType" SG_ 346 SecAutoEstBrkTrqAppStat "ENM";
BA_ "SignalLongName" SG_ 346 SecAutoEstBrkTrqAppStat "Secondary Autonomous Estimated Brake Torque Applied Status";
BA_ "VNSigAllNodes" SG_ 346 SecAutoEstBrkTrqAppStat 1;
BA_ "SignalType" SG_ 346 SecBrkModStat "ENM";
BA_ "SignalLongName" SG_ 346 SecBrkModStat "Secondary Brake Module Status";
BA_ "VNSigAllNodes" SG_ 346 SecBrkModStat 1;
BA_ "SignalType" SG_ 346 SecAutoBrkSysDrInfcStat "ENM";
BA_ "SignalLongName" SG_ 346 SecAutoBrkSysDrInfcStat "Secondary Autonomous Brake System Driver Interference Detected Status";
BA_ "VNSigAllNodes" SG_ 346 SecAutoBrkSysDrInfcStat 1;
BA_ "SignalType" SG_ 346 SecAutoEstBrkTrqApd "UNM";
BA_ "SignalLongName" SG_ 346 SecAutoEstBrkTrqApd "Secondary Autonomous Estimated Brake Torque Applied";
BA_ "GenSigStartValue" SG_ 346 SecAutoEstBrkTrqApd 32767;
BA_ "VNSigAllNodes" SG_ 346 SecAutoEstBrkTrqApd 1;
BA_ "SignalType" SG_ 346 SecAutoArbBrkTrqReq "UNM";
BA_ "SignalLongName" SG_ 346 SecAutoArbBrkTrqReq "Secondary Automomous Arbitrated Brake Torque Request";
BA_ "GenSigStartValue" SG_ 346 SecAutoArbBrkTrqReq 32767;
BA_ "VNSigAllNodes" SG_ 346 SecAutoArbBrkTrqReq 1;
BA_ "VNSigSLHSSharedDiagnostic" SG_ 1627 DgnInf 1;
BA_ "SignalType" SG_ 1627 DgnInf "UNM";
BA_ "SignalLongName" SG_ 1627 DgnInf "Diagnostic Information";
BA_ "VNSigAllNodes" SG_ 1627 DgnInf 1;
BA_ "VNSigSLHSSharedDiagnostic" SG_ 1623 DgnInf 1;
BA_ "SignalType" SG_ 1623 DgnInf "UNM";
BA_ "SignalLongName" SG_ 1623 DgnInf "Diagnostic Information";
BA_ "VNSigAllNodes" SG_ 1623 DgnInf 1;
BA_ "SignalType" SG_ 344 CSS_CoPilotCibAvail "BLN";
BA_ "SignalLongName" SG_ 344 CSS_CoPilotCibAvail "CoPilot System Status : CoPilot Collision Imminent Braking Available";
BA_ "VNSigAllNodes" SG_ 344 CSS_CoPilotCibAvail 1;
BA_ "SignalType" SG_ 344 CSS_CoPilotSysFltStat "ENM";
BA_ "SignalLongName" SG_ 344 CSS_CoPilotSysFltStat "CoPilot System Status : CoPilot System Fault Status";
BA_ "VNSigAllNodes" SG_ 344 CSS_CoPilotSysFltStat 1;
BA_ "SignalType" SG_ 344 CSS_CoPilotRvbAvail "BLN";
BA_ "SignalLongName" SG_ 344 CSS_CoPilotRvbAvail "CoPilot System Status : CoPilot Rear Virtual Bumper Available";
BA_ "VNSigAllNodes" SG_ 344 CSS_CoPilotRvbAvail 1;
BA_ "SignalType" SG_ 344 CSS_CoPilotPcmAvail "BLN";
BA_ "SignalLongName" SG_ 344 CSS_CoPilotPcmAvail "CoPilot System Status : CoPilot Pedestrian Collision Mitigation Available";
BA_ "VNSigAllNodes" SG_ 344 CSS_CoPilotPcmAvail 1;
BA_ "SignalType" SG_ 344 CSS_CoPilotFcaAvail "BLN";
BA_ "SignalLongName" SG_ 344 CSS_CoPilotFcaAvail "CoPilot System Status : CoPilot Forward Collision Alert Available";
BA_ "VNSigAllNodes" SG_ 344 CSS_CoPilotFcaAvail 1;
BA_ "SignalType" SG_ 344 CSS_CoPilotBrkExpctd "BLN";
BA_ "SignalLongName" SG_ 344 CSS_CoPilotBrkExpctd "CoPilot System Status : CoPilot Braking Expected";
BA_ "VNSigAllNodes" SG_ 344 CSS_CoPilotBrkExpctd 1;
BA_ "SignalType" SG_ 344 CoPilotSysStatInfoChcksm "UNM";
BA_ "SignalLongName" SG_ 344 CoPilotSysStatInfoChcksm "CoPilot System Status Info Checksum";
BA_ "VNSigAllNodes" SG_ 344 CoPilotSysStatInfoChcksm 1;
BA_ "SignalType" SG_ 344 CoPilotSysStatInfoARC "UNM";
BA_ "SignalLongName" SG_ 344 CoPilotSysStatInfoARC "CoPilot System Status Info Alive Rolling Count";
BA_ "VNSigAllNodes" SG_ 344 CoPilotSysStatInfoARC 1;
BA_ "SignalType" SG_ 344 StrgAngTrqBsdEstSrfcMuConf "ENM";
BA_ "SignalLongName" SG_ 344 StrgAngTrqBsdEstSrfcMuConf "Steering Angle Torque Based Estimated Surface Mu Confidence";
BA_ "VNSigAllNodes" SG_ 344 StrgAngTrqBsdEstSrfcMuConf 1;
BA_ "SignalType" SG_ 344 StrgAngTrqBsdEstSrfcMuCapV "ENM";
BA_ "SignalLongName" SG_ 344 StrgAngTrqBsdEstSrfcMuCapV "Steering Angle Torque Based Estimated Surface Mu Capacity Validity";
BA_ "VNSigAllNodes" SG_ 344 StrgAngTrqBsdEstSrfcMuCapV 1;
BA_ "SignalType" SG_ 344 StrgAngTrqBsdEstSrfcMuCap "UNM";
BA_ "SignalLongName" SG_ 344 StrgAngTrqBsdEstSrfcMuCap "Steering Angle Torque Based Estimated Surface Mu Capacity";
BA_ "VNSigAllNodes" SG_ 344 StrgAngTrqBsdEstSrfcMuCap 1;
BA_ "SignalType" SG_ 344 LatVlctyBsdSrfcMuCap "UNM";
BA_ "SignalLongName" SG_ 344 LatVlctyBsdSrfcMuCap "Lateral Velocity Based Surface Mu Capacity";
BA_ "VNSigAllNodes" SG_ 344 LatVlctyBsdSrfcMuCap 1;
BA_ "SignalType" SG_ 531 SecDynCtrlStatChksm "UNM";
BA_ "SignalLongName" SG_ 531 SecDynCtrlStatChksm "Secondary Dynamic Control Status Checksum";
BA_ "VNSigAllNodes" SG_ 531 SecDynCtrlStatChksm 1;
BA_ "SignalType" SG_ 531 SecDynCtrlStatARC "UNM";
BA_ "SignalLongName" SG_ 531 SecDynCtrlStatARC "Secondary Dynamic Control Status Alive Rolling Count";
BA_ "VNSigAllNodes" SG_ 531 SecDynCtrlStatARC 1;
BA_ "SignalType" SG_ 531 Blkpdldet "BLN";
BA_ "SignalLongName" SG_ 531 Blkpdldet "Blocked Pedal Detected ";
BA_ "VNSigAllNodes" SG_ 531 Blkpdldet 1;
BA_ "SignalType" SG_ 531 SecGrsHydCmpDtctd "BLN";
BA_ "SignalLongName" SG_ 531 SecGrsHydCmpDtctd "Secondary Gross Hydraulic Compliance Detected";
BA_ "VNSigAllNodes" SG_ 531 SecGrsHydCmpDtctd 1;
BA_ "SignalType" SG_ 531 SecGrsHydLkDtctd "BLN";
BA_ "SignalLongName" SG_ 531 SecGrsHydLkDtctd "Secondary Gross Hydraulic Leak Detected";
BA_ "VNSigAllNodes" SG_ 531 SecGrsHydLkDtctd 1;
BA_ "SignalType" SG_ 531 SecLatStabSysStat "ENM";
BA_ "SignalLongName" SG_ 531 SecLatStabSysStat "Secondary Lateral Stability System Status";
BA_ "VNSigAllNodes" SG_ 531 SecLatStabSysStat 1;
BA_ "SignalType" SG_ 531 SecLongStabSysStat "ENM";
BA_ "SignalLongName" SG_ 531 SecLongStabSysStat "Secondary Longitudinal Stability System Status";
BA_ "VNSigAllNodes" SG_ 531 SecLongStabSysStat 1;
BA_ "SignalType" SG_ 235 AutoCoPAxlTrqCmnd2PVal "UNM";
BA_ "SignalLongName" SG_ 235 AutoCoPAxlTrqCmnd2PVal "Autonomous CoPilot Axle Torque Command 2 Protection Value";
BA_ "VNSigAllNodes" SG_ 235 AutoCoPAxlTrqCmnd2PVal 1;
BA_ "SignalType" SG_ 235 ACATC2_AutoCoPCntrlAct "BLN";
BA_ "SignalLongName" SG_ 235 ACATC2_AutoCoPCntrlAct "Autonomous CoPilot Axle Torque Command 2: Autonomous CoPilot Control Active";
BA_ "VNSigAllNodes" SG_ 235 ACATC2_AutoCoPCntrlAct 1;
BA_ "SignalType" SG_ 235 ACATC2_CoPAxlTrqReq "UNM";
BA_ "SignalLongName" SG_ 235 ACATC2_CoPAxlTrqReq "Autonomous CoPilot Axle Torque Command 2: CoPilot Axle Torque Request";
BA_ "GenSigStartValue" SG_ 235 ACATC2_CoPAxlTrqReq 11267;
BA_ "VNSigAllNodes" SG_ 235 ACATC2_CoPAxlTrqReq 1;
BA_ "SignalType" SG_ 235 AutoCoPAxlTrqCmnd2ARC "UNM";
BA_ "SignalLongName" SG_ 235 AutoCoPAxlTrqCmnd2ARC "Autonomous CoPilot Axle Torque Command 2 Alive Rolling Count";
BA_ "VNSigAllNodes" SG_ 235 AutoCoPAxlTrqCmnd2ARC 1;
BA_ "VNSigSLHSSharedDiagnostic" SG_ 1366 DgnInf_CE556 1;
BA_ "SignalType" SG_ 1366 DgnInf_CE556 "UNM";
BA_ "SignalLongName" SG_ 1366 DgnInf_CE556 "Diagnostic Information CE556";
BA_ "VNSigAllNodes" SG_ 1366 DgnInf_CE556 1;
BA_ "SignalType" SG_ 342 StgCmndTgtAng "SNM";
BA_ "SignalLongName" SG_ 342 StgCmndTgtAng "Steering Command Target Angle";
BA_ "VNSigAllNodes" SG_ 342 StgCmndTgtAng 1;
BA_ "SignalType" SG_ 342 StrgCmndMsgStatV "ENM";
BA_ "SignalLongName" SG_ 342 StrgCmndMsgStatV "Steering Command Message Status Validity";
BA_ "VNSigAllNodes" SG_ 342 StrgCmndMsgStatV 1;
BA_ "SignalType" SG_ 342 StrgCmndMsgStat "ENM";
BA_ "SignalLongName" SG_ 342 StrgCmndMsgStat "Steering Command Message Status";
BA_ "VNSigAllNodes" SG_ 342 StrgCmndMsgStat 1;
BA_ "SignalType" SG_ 342 StrgCmndMsgUtlzdV "ENM";
BA_ "SignalLongName" SG_ 342 StrgCmndMsgUtlzdV "Steering Command Message Utilized Validity";
BA_ "VNSigAllNodes" SG_ 342 StrgCmndMsgUtlzdV 1;
BA_ "SignalType" SG_ 342 StrgCmndMsgUtlzd "ENM";
BA_ "SignalLongName" SG_ 342 StrgCmndMsgUtlzd "Steering Command Message Utilized";
BA_ "VNSigAllNodes" SG_ 342 StrgCmndMsgUtlzd 1;
BA_ "SignalType" SG_ 342 AutoStrgCmndStatV "ENM";
BA_ "SignalLongName" SG_ 342 AutoStrgCmndStatV "Autonomous Steering Command Status Validity";
BA_ "VNSigAllNodes" SG_ 342 AutoStrgCmndStatV 1;
BA_ "SignalType" SG_ 342 StgTtlEffTrqDlvd "SNM";
BA_ "SignalLongName" SG_ 342 StgTtlEffTrqDlvd "Steering Total Effective Torque Delivered";
BA_ "VNSigAllNodes" SG_ 342 StgTtlEffTrqDlvd 1;
BA_ "SignalType" SG_ 342 StgTrqSnsrVStat "ENM";
BA_ "SignalLongName" SG_ 342 StgTrqSnsrVStat "Steering Torque Sensor Validity Status";
BA_ "VNSigAllNodes" SG_ 342 StgTrqSnsrVStat 1;
BA_ "SignalType" SG_ 342 StgSysOtptStatV "ENM";
BA_ "SignalLongName" SG_ 342 StgSysOtptStatV "Steering System Output Status Validity";
BA_ "VNSigAllNodes" SG_ 342 StgSysOtptStatV 1;
BA_ "SignalType" SG_ 342 StgSysOtptStat "ENM";
BA_ "SignalLongName" SG_ 342 StgSysOtptStat "Steering System Output Status";
BA_ "VNSigAllNodes" SG_ 342 StgSysOtptStat 1;
BA_ "SignalType" SG_ 342 StgOtptTempLmtgSte "ENM";
BA_ "SignalLongName" SG_ 342 StgOtptTempLmtgSte "Steering Output Temporarily Limiting State";
BA_ "VNSigAllNodes" SG_ 342 StgOtptTempLmtgSte 1;
BA_ "SignalType" SG_ 342 StgAngRtLmtV "ENM";
BA_ "SignalLongName" SG_ 342 StgAngRtLmtV "Steering Angle Rate Limit Validity";
BA_ "VNSigAllNodes" SG_ 342 StgAngRtLmtV 1;
BA_ "SignalType" SG_ 342 StgAngRtLmt "UNM";
BA_ "SignalLongName" SG_ 342 StgAngRtLmt "Steering Angle Rate Limit";
BA_ "VNSigAllNodes" SG_ 342 StgAngRtLmt 1;
BA_ "SignalType" SG_ 342 AutoStrgCmndStat "ENM";
BA_ "SignalLongName" SG_ 342 AutoStrgCmndStat "Autonomous Steering Command Status";
BA_ "VNSigAllNodes" SG_ 342 AutoStrgCmndStat 1;
BA_ "SignalType" SG_ 342 AutoStgStatChksm "UNM";
BA_ "SignalLongName" SG_ 342 AutoStgStatChksm "Autonomous Steering Status Checksum";
BA_ "VNSigAllNodes" SG_ 342 AutoStgStatChksm 1;
BA_ "SignalType" SG_ 342 AutoStgStatARC "UNM";
BA_ "SignalLongName" SG_ 342 AutoStgStatARC "Autonomous Steering Status Alive Rolling Count";
BA_ "VNSigAllNodes" SG_ 342 AutoStgStatARC 1;
BA_ "SignalType" SG_ 342 StgOvrdDetn "ENM";
BA_ "SignalLongName" SG_ 342 StgOvrdDetn "Steering Override Detection";
BA_ "VNSigAllNodes" SG_ 342 StgOvrdDetn 1;
BA_ "SignalType" SG_ 354 EstBrkRtrTempStat "ENM";
BA_ "SignalLongName" SG_ 354 EstBrkRtrTempStat "Estimated Brake Rotor Temperature Status";
BA_ "VNSigAllNodes" SG_ 354 EstBrkRtrTempStat 1;
BA_ "SignalType" SG_ 354 PriDynCtrlStatChksm "UNM";
BA_ "SignalLongName" SG_ 354 PriDynCtrlStatChksm "Primary Dynamic Control Status Checksum";
BA_ "VNSigAllNodes" SG_ 354 PriDynCtrlStatChksm 1;
BA_ "SignalType" SG_ 354 PriDynCtrlStatARC "UNM";
BA_ "SignalLongName" SG_ 354 PriDynCtrlStatARC "Primary Dynamic Control Status Alive Rolling Count";
BA_ "VNSigAllNodes" SG_ 354 PriDynCtrlStatARC 1;
BA_ "SignalType" SG_ 354 EstBrkRtrTempRR "UNM";
BA_ "SignalLongName" SG_ 354 EstBrkRtrTempRR "Estimated Brake Rotor Temperature Right Rear";
BA_ "GenSigStartValue" SG_ 354 EstBrkRtrTempRR 5;
BA_ "VNSigAllNodes" SG_ 354 EstBrkRtrTempRR 1;
BA_ "SignalType" SG_ 354 EstBrkRtrTempRF "UNM";
BA_ "SignalLongName" SG_ 354 EstBrkRtrTempRF "Estimated Brake Rotor Temperature Right Front";
BA_ "GenSigStartValue" SG_ 354 EstBrkRtrTempRF 5;
BA_ "VNSigAllNodes" SG_ 354 EstBrkRtrTempRF 1;
BA_ "SignalType" SG_ 354 EstBrkRtrTempLR "UNM";
BA_ "SignalLongName" SG_ 354 EstBrkRtrTempLR "Estimated Brake Rotor Temperature Left Rear";
BA_ "GenSigStartValue" SG_ 354 EstBrkRtrTempLR 5;
BA_ "VNSigAllNodes" SG_ 354 EstBrkRtrTempLR 1;
BA_ "SignalType" SG_ 354 EstBrkRtrTempLF "UNM";
BA_ "SignalLongName" SG_ 354 EstBrkRtrTempLF "Estimated Brake Rotor Temperature Left Front";
BA_ "GenSigStartValue" SG_ 354 EstBrkRtrTempLF 5;
BA_ "VNSigAllNodes" SG_ 354 EstBrkRtrTempLF 1;
BA_ "SignalType" SG_ 354 PriGrsBrkIneffDtctd "BLN";
BA_ "SignalLongName" SG_ 354 PriGrsBrkIneffDtctd "Primary Gross Brake Ineffectiveness Detected";
BA_ "VNSigAllNodes" SG_ 354 PriGrsBrkIneffDtctd 1;
BA_ "SignalType" SG_ 354 PriGrsHydCmpDtctd "BLN";
BA_ "SignalLongName" SG_ 354 PriGrsHydCmpDtctd "Primary Gross Hydraulic Compliance Detected";
BA_ "VNSigAllNodes" SG_ 354 PriGrsHydCmpDtctd 1;
BA_ "SignalType" SG_ 354 PriGrsHydLkDtctd "BLN";
BA_ "SignalLongName" SG_ 354 PriGrsHydLkDtctd "Primary Gross Hydraulic Leak Detected";
BA_ "VNSigAllNodes" SG_ 354 PriGrsHydLkDtctd 1;
BA_ "SignalType" SG_ 354 RdRghnsStat "ENM";
BA_ "SignalLongName" SG_ 354 RdRghnsStat "Road Roughness Status";
BA_ "VNSigAllNodes" SG_ 354 RdRghnsStat 1;
BA_ "SignalType" SG_ 354 RdRghnsIndctn "UNM";
BA_ "SignalLongName" SG_ 354 RdRghnsIndctn "Road Roughness Indication";
BA_ "VNSigAllNodes" SG_ 354 RdRghnsIndctn 1;
BA_ "SignalType" SG_ 354 EPBApplSt "ENM";
BA_ "SignalLongName" SG_ 354 EPBApplSt "Electric Park Brake Application State";
BA_ "VNSigAllNodes" SG_ 354 EPBApplSt 1;
BA_ "SignalType" SG_ 354 EPBStat "ENM";
BA_ "SignalLongName" SG_ 354 EPBStat "Electric Park Brake Status";
BA_ "VNSigAllNodes" SG_ 354 EPBStat 1;
BA_ "SignalType" SG_ 354 BrkFldLvlIndStat "ENM";
BA_ "SignalLongName" SG_ 354 BrkFldLvlIndStat "Brake Fluid Level Indicator Status";
BA_ "VNSigAllNodes" SG_ 354 BrkFldLvlIndStat 1;
BA_ "SignalType" SG_ 354 BrkFldLvILwFldDtctd "BLN";
BA_ "SignalLongName" SG_ 354 BrkFldLvILwFldDtctd "Brake Fluid Level Low Fluid Detected";
BA_ "VNSigAllNodes" SG_ 354 BrkFldLvILwFldDtctd 1;
BA_ "SignalType" SG_ 354 PriESCStat "ENM";
BA_ "SignalLongName" SG_ 354 PriESCStat "Primary Electronic Stability Control System Status";
BA_ "VNSigAllNodes" SG_ 354 PriESCStat 1;
BA_ "SignalType" SG_ 354 PriTCSStat "ENM";
BA_ "SignalLongName" SG_ 354 PriTCSStat "Primary Traction Control System Status";
BA_ "VNSigAllNodes" SG_ 354 PriTCSStat 1;
BA_ "SignalType" SG_ 354 PriABSStat "ENM";
BA_ "SignalLongName" SG_ 354 PriABSStat "Primary Antilock Brake System Status";
BA_ "VNSigAllNodes" SG_ 354 PriABSStat 1;
BA_ "SignalType" SG_ 354 PriDRPStat "ENM";
BA_ "SignalLongName" SG_ 354 PriDRPStat "Primary Dynamic Rear Proportioning Status";
BA_ "VNSigAllNodes" SG_ 354 PriDRPStat 1;
BA_REL_ "GenSigSuprvResp" BU_SG_REL_ CMMb_PCE SG_ 211 MtrRslvrPstnChksm 1;
BA_REL_ "GenSigTimeoutMsg" BU_SG_REL_ CMMb_PCE SG_ 211 MtrRslvrPstnChksm 211;
BA_REL_ "GenSigTimeoutTime" BU_SG_REL_ CMMb_PCE SG_ 211 MtrRslvrPstnChksm 37;
BA_REL_ "GenSigSuprvResp" BU_SG_REL_ CMMa_PCE SG_ 211 MtrRslvrPstnChksm 1;
BA_REL_ "GenSigTimeoutMsg" BU_SG_REL_ CMMa_PCE SG_ 211 MtrRslvrPstnChksm 211;
BA_REL_ "GenSigTimeoutTime" BU_SG_REL_ CMMa_PCE SG_ 211 MtrRslvrPstnChksm 37;
BA_REL_ "GenSigSuprvResp" BU_SG_REL_ CMMb_PCE SG_ 211 MtrRslvrPstnARC 1;
BA_REL_ "GenSigTimeoutMsg" BU_SG_REL_ CMMb_PCE SG_ 211 MtrRslvrPstnARC 211;
BA_REL_ "GenSigTimeoutTime" BU_SG_REL_ CMMb_PCE SG_ 211 MtrRslvrPstnARC 37;
BA_REL_ "GenSigSuprvResp" BU_SG_REL_ CMMa_PCE SG_ 211 MtrRslvrPstnARC 1;
BA_REL_ "GenSigTimeoutMsg" BU_SG_REL_ CMMa_PCE SG_ 211 MtrRslvrPstnARC 211;
BA_REL_ "GenSigTimeoutTime" BU_SG_REL_ CMMa_PCE SG_ 211 MtrRslvrPstnARC 37;
BA_REL_ "GenSigSuprvResp" BU_SG_REL_ CMMb_PCE SG_ 211 MtrRslvrWhlSpd 1;
BA_REL_ "GenSigTimeoutMsg" BU_SG_REL_ CMMb_PCE SG_ 211 MtrRslvrWhlSpd 211;
BA_REL_ "GenSigTimeoutTime" BU_SG_REL_ CMMb_PCE SG_ 211 MtrRslvrWhlSpd 37;
BA_REL_ "GenSigSuprvResp" BU_SG_REL_ CMMa_PCE SG_ 211 MtrRslvrWhlSpd 1;
BA_REL_ "GenSigTimeoutMsg" BU_SG_REL_ CMMa_PCE SG_ 211 MtrRslvrWhlSpd 211;
BA_REL_ "GenSigTimeoutTime" BU_SG_REL_ CMMa_PCE SG_ 211 MtrRslvrWhlSpd 37;
BA_REL_ "GenSigSuprvResp" BU_SG_REL_ CMMb_PCE SG_ 211 MtrRslvrAvgDrvWhlPstnV 1;
BA_REL_ "GenSigTimeoutTime" BU_SG_REL_ CMMb_PCE SG_ 211 MtrRslvrAvgDrvWhlPstnV 37;
BA_REL_ "GenSigSuprvResp" BU_SG_REL_ CMMa_PCE SG_ 211 MtrRslvrAvgDrvWhlPstnV 1;
BA_REL_ "GenSigTimeoutTime" BU_SG_REL_ CMMa_PCE SG_ 211 MtrRslvrAvgDrvWhlPstnV 37;
BA_REL_ "GenSigSuprvResp" BU_SG_REL_ CMMb_PCE SG_ 211 MtrRslvrAvgDrvWhlPstn 1;
BA_REL_ "GenSigTimeoutMsg" BU_SG_REL_ CMMb_PCE SG_ 211 MtrRslvrAvgDrvWhlPstn 211;
BA_REL_ "GenSigTimeoutTime" BU_SG_REL_ CMMb_PCE SG_ 211 MtrRslvrAvgDrvWhlPstn 37;
BA_REL_ "GenSigSuprvResp" BU_SG_REL_ CMMa_PCE SG_ 211 MtrRslvrAvgDrvWhlPstn 1;
BA_REL_ "GenSigTimeoutMsg" BU_SG_REL_ CMMa_PCE SG_ 211 MtrRslvrAvgDrvWhlPstn 211;
BA_REL_ "GenSigTimeoutTime" BU_SG_REL_ CMMa_PCE SG_ 211 MtrRslvrAvgDrvWhlPstn 37;
BA_REL_ "GenSigSuprvResp" BU_SG_REL_ EPSa_PCE SG_ 1010 SecuredVehSpdSrcDrvnRed 1;
BA_REL_ "GenSigTimeoutMsg" BU_SG_REL_ EPSa_PCE SG_ 1010 SecuredVehSpdSrcDrvnRed 1010;
BA_REL_ "GenSigTimeoutTime" BU_SG_REL_ EPSa_PCE SG_ 1010 SecuredVehSpdSrcDrvnRed 250;
BA_REL_ "GenSigSuprvResp" BU_SG_REL_ EBOOST_OBD_PCE SG_ 1010 SecuredVehSpdSrcDrvnRed 1;
BA_REL_ "GenSigTimeoutMsg" BU_SG_REL_ EBOOST_OBD_PCE SG_ 1010 SecuredVehSpdSrcDrvnRed 1010;
BA_REL_ "GenSigTimeoutTime" BU_SG_REL_ EBOOST_OBD_PCE SG_ 1010 SecuredVehSpdSrcDrvnRed 250;
BA_REL_ "GenSigTimeoutTime" BU_SG_REL_ EBOOST_OBD_PCE SG_ 1010 SecuredVehSpdRedChcksm 250;
BA_REL_ "GenSigTimeoutTime" BU_SG_REL_ EBOOST_OBD_PCE SG_ 1010 SecuredVehSpdRedARC 250;
BA_REL_ "GenSigSuprvResp" BU_SG_REL_ EPSa_PCE SG_ 1010 SecuredVehSpdAvlblDrvnRed 1;
BA_REL_ "GenSigTimeoutMsg" BU_SG_REL_ EPSa_PCE SG_ 1010 SecuredVehSpdAvlblDrvnRed 1010;
BA_REL_ "GenSigTimeoutTime" BU_SG_REL_ EPSa_PCE SG_ 1010 SecuredVehSpdAvlblDrvnRed 250;
BA_REL_ "GenSigSuprvResp" BU_SG_REL_ EBOOST_OBD_PCE SG_ 1010 SecuredVehSpdAvlblDrvnRed 1;
BA_REL_ "GenSigTimeoutMsg" BU_SG_REL_ EBOOST_OBD_PCE SG_ 1010 SecuredVehSpdAvlblDrvnRed 1010;
BA_REL_ "GenSigTimeoutTime" BU_SG_REL_ EBOOST_OBD_PCE SG_ 1010 SecuredVehSpdAvlblDrvnRed 250;
BA_REL_ "GenSigTimeoutTime" BU_SG_REL_ EBOOST_OBD_PCE SG_ 1010 SecuredVehSpdDrvnRedV 250;
BA_REL_ "GenSigSuprvResp" BU_SG_REL_ EPSa_PCE SG_ 1010 SecuredVehSpdDrvnRed 1;
BA_REL_ "GenSigTimeoutMsg" BU_SG_REL_ EPSa_PCE SG_ 1010 SecuredVehSpdDrvnRed 1010;
BA_REL_ "GenSigTimeoutTime" BU_SG_REL_ EPSa_PCE SG_ 1010 SecuredVehSpdDrvnRed 250;
BA_REL_ "GenSigSuprvResp" BU_SG_REL_ EBOOST_OBD_PCE SG_ 1010 SecuredVehSpdDrvnRed 1;
BA_REL_ "GenSigTimeoutMsg" BU_SG_REL_ EBOOST_OBD_PCE SG_ 1010 SecuredVehSpdDrvnRed 1010;
BA_REL_ "GenSigTimeoutTime" BU_SG_REL_ EBOOST_OBD_PCE SG_ 1010 SecuredVehSpdDrvnRed 250;
BA_REL_ "GenSigRxStartValue" BU_SG_REL_ EBOOST_OBD_PCE SG_ 407 BrkPedDrvOvrdDtdESC "0";
BA_REL_ "GenSigSuprvResp" BU_SG_REL_ EBOOST_OBD_PCE SG_ 407 BrkPedDrvOvrdDtdESC 1;
BA_REL_ "GenSigTimeoutMsg" BU_SG_REL_ EBOOST_OBD_PCE SG_ 407 BrkPedDrvOvrdDtdESC 407;
BA_REL_ "GenSigTimeoutTime" BU_SG_REL_ EBOOST_OBD_PCE SG_ 407 BrkPedDrvOvrdDtdESC 50;
BA_REL_ "GenSigRxStartValue" BU_SG_REL_ EBOOST_OBD_PCE SG_ 407 VrtlMstCylPrsQlfr "0";
BA_REL_ "GenSigRxStartValue" BU_SG_REL_ EBOOST_OBD_PCE SG_ 407 VrtlMstCylPrs "0";
BA_REL_ "GenSigSuprvResp" BU_SG_REL_ EBOOST_OBD_PCE SG_ 407 VrtlMstCylPrs 1;
BA_REL_ "GenSigTimeoutMsg" BU_SG_REL_ EBOOST_OBD_PCE SG_ 407 VrtlMstCylPrs 407;
BA_REL_ "GenSigTimeoutTime" BU_SG_REL_ EBOOST_OBD_PCE SG_ 407 VrtlMstCylPrs 50;
BA_REL_ "GenSigRxStartValue" BU_SG_REL_ ADIMa_PCE SG_ 407 BrkFldLvlLw197V "Valid";
BA_REL_ "GenSigRxStartValue" BU_SG_REL_ EBOOST_OBD_PCE SG_ 407 BrkFldLvlLw197V "Valid";
BA_REL_ "GenSigVBitResp" BU_SG_REL_ ADIMa_PCE SG_ 407 BrkFldLvlLw197 1;
BA_REL_ "GenSigRxStartValue" BU_SG_REL_ ADIMa_PCE SG_ 407 BrkFldLvlLw197 "False";
BA_REL_ "GenSigSuprvResp" BU_SG_REL_ ADIMa_PCE SG_ 407 BrkFldLvlLw197 1;
BA_REL_ "GenSigTimeoutMsg" BU_SG_REL_ ADIMa_PCE SG_ 407 BrkFldLvlLw197 407;
BA_REL_ "GenSigTimeoutTime" BU_SG_REL_ ADIMa_PCE SG_ 407 BrkFldLvlLw197 50;
BA_REL_ "GenSigVBitResp" BU_SG_REL_ EBOOST_OBD_PCE SG_ 407 BrkFldLvlLw197 1;
BA_REL_ "GenSigRxStartValue" BU_SG_REL_ EBOOST_OBD_PCE SG_ 407 BrkFldLvlLw197 "False";
BA_REL_ "GenSigSuprvResp" BU_SG_REL_ EBOOST_OBD_PCE SG_ 407 BrkFldLvlLw197 1;
BA_REL_ "GenSigTimeoutMsg" BU_SG_REL_ EBOOST_OBD_PCE SG_ 407 BrkFldLvlLw197 407;
BA_REL_ "GenSigTimeoutTime" BU_SG_REL_ EBOOST_OBD_PCE SG_ 407 BrkFldLvlLw197 50;
BA_REL_ "GenSigRxStartValue" BU_SG_REL_ EBOOST_OBD_PCE SG_ 407 ExtBrkReq2Chksm "0";
BA_REL_ "GenSigRxStartValue" BU_SG_REL_ EBOOST_OBD_PCE SG_ 407 ExtBrkReq2ARC "0";
BA_REL_ "GenSigRxStartValue" BU_SG_REL_ EBOOST_OBD_PCE SG_ 407 AxSnsrOffstLngTrm "0";
BA_REL_ "GenSigSuprvResp" BU_SG_REL_ EBOOST_OBD_PCE SG_ 407 AxSnsrOffstLngTrm 1;
BA_REL_ "GenSigTimeoutMsg" BU_SG_REL_ EBOOST_OBD_PCE SG_ 407 AxSnsrOffstLngTrm 407;
BA_REL_ "GenSigTimeoutTime" BU_SG_REL_ EBOOST_OBD_PCE SG_ 407 AxSnsrOffstLngTrm 50;
BA_REL_ "GenSigRxStartValue" BU_SG_REL_ EBOOST_OBD_PCE SG_ 313 ActrBrkFldFlwReqStat "0";
BA_REL_ "GenSigSuprvResp" BU_SG_REL_ EBOOST_OBD_PCE SG_ 313 ActrBrkFldFlwReqStat 1;
BA_REL_ "GenSigTimeoutMsg" BU_SG_REL_ EBOOST_OBD_PCE SG_ 313 ActrBrkFldFlwReqStat 313;
BA_REL_ "GenSigTimeoutTime" BU_SG_REL_ EBOOST_OBD_PCE SG_ 313 ActrBrkFldFlwReqStat 25;
BA_REL_ "GenSigRxStartValue" BU_SG_REL_ EBOOST_OBD_PCE SG_ 313 ActrBrkFldFlwReq "0";
BA_REL_ "GenSigSuprvResp" BU_SG_REL_ EBOOST_OBD_PCE SG_ 313 ActrBrkFldFlwReq 1;
BA_REL_ "GenSigTimeoutMsg" BU_SG_REL_ EBOOST_OBD_PCE SG_ 313 ActrBrkFldFlwReq 313;
BA_REL_ "GenSigTimeoutTime" BU_SG_REL_ EBOOST_OBD_PCE SG_ 313 ActrBrkFldFlwReq 25;
BA_REL_ "GenSigRxStartValue" BU_SG_REL_ EBOOST_OBD_PCE SG_ 313 ABSAtv139 "False";
BA_REL_ "GenSigSuprvResp" BU_SG_REL_ EBOOST_OBD_PCE SG_ 313 ABSAtv139 1;
BA_REL_ "GenSigTimeoutMsg" BU_SG_REL_ EBOOST_OBD_PCE SG_ 313 ABSAtv139 313;
BA_REL_ "GenSigTimeoutTime" BU_SG_REL_ EBOOST_OBD_PCE SG_ 313 ABSAtv139 25;
BA_REL_ "GenSigSuprvResp" BU_SG_REL_ ADIMa_PCE SG_ 313 MstCylPrsCrct1Stat 1;
BA_REL_ "GenSigTimeoutMsg" BU_SG_REL_ ADIMa_PCE SG_ 313 MstCylPrsCrct1Stat 313;
BA_REL_ "GenSigTimeoutTime" BU_SG_REL_ ADIMa_PCE SG_ 313 MstCylPrsCrct1Stat 25;
BA_REL_ "GenSigRxStartValue" BU_SG_REL_ EBOOST_OBD_PCE SG_ 313 MstCylPrsCrct1Stat "0";
BA_REL_ "GenSigSuprvResp" BU_SG_REL_ EBOOST_OBD_PCE SG_ 313 MstCylPrsCrct1Stat 1;
BA_REL_ "GenSigTimeoutMsg" BU_SG_REL_ EBOOST_OBD_PCE SG_ 313 MstCylPrsCrct1Stat 313;
BA_REL_ "GenSigTimeoutTime" BU_SG_REL_ EBOOST_OBD_PCE SG_ 313 MstCylPrsCrct1Stat 25;
BA_REL_ "GenSigSuprvResp" BU_SG_REL_ ADIMa_PCE SG_ 313 MstCylPrsCrct1 1;
BA_REL_ "GenSigTimeoutMsg" BU_SG_REL_ ADIMa_PCE SG_ 313 MstCylPrsCrct1 313;
BA_REL_ "GenSigTimeoutTime" BU_SG_REL_ ADIMa_PCE SG_ 313 MstCylPrsCrct1 25;
BA_REL_ "GenSigRxStartValue" BU_SG_REL_ EBOOST_OBD_PCE SG_ 313 MstCylPrsCrct1 "0";
BA_REL_ "GenSigSuprvResp" BU_SG_REL_ EBOOST_OBD_PCE SG_ 313 MstCylPrsCrct1 1;
BA_REL_ "GenSigTimeoutMsg" BU_SG_REL_ EBOOST_OBD_PCE SG_ 313 MstCylPrsCrct1 313;
BA_REL_ "GenSigTimeoutTime" BU_SG_REL_ EBOOST_OBD_PCE SG_ 313 MstCylPrsCrct1 25;
BA_REL_ "GenSigRxStartValue" BU_SG_REL_ EBOOST_OBD_PCE SG_ 313 ExtBrkReq1Chksm "0";
BA_REL_ "GenSigRxStartValue" BU_SG_REL_ EBOOST_OBD_PCE SG_ 313 ExtBrkReq1ARC "0";
BA_REL_ "GenSigSuprvResp" BU_SG_REL_ EBOOST_OBD_PCE SG_ 313 EBCMhydctrlAct 1;
BA_REL_ "GenSigTimeoutMsg" BU_SG_REL_ EBOOST_OBD_PCE SG_ 313 EBCMhydctrlAct 313;
BA_REL_ "GenSigTimeoutTime" BU_SG_REL_ EBOOST_OBD_PCE SG_ 313 EBCMhydctrlAct 250;
BA_REL_ "GenSigRxStartValue" BU_SG_REL_ EBOOST_OBD_PCE SG_ 406 EstWhlBrkPrsStatRed "Unknown";
BA_REL_ "GenSigSuprvResp" BU_SG_REL_ EBOOST_OBD_PCE SG_ 406 EstWhlBrkPrsStatRed 1;
BA_REL_ "GenSigTimeoutMsg" BU_SG_REL_ EBOOST_OBD_PCE SG_ 406 EstWhlBrkPrsStatRed 406;
BA_REL_ "GenSigTimeoutTime" BU_SG_REL_ EBOOST_OBD_PCE SG_ 406 EstWhlBrkPrsStatRed 50;
BA_REL_ "GenSigRxStartValue" BU_SG_REL_ ADIMa_PCE SG_ 406 EstWhlBrkPrsStatRed "0";
BA_REL_ "GenSigSuprvResp" BU_SG_REL_ ADIMa_PCE SG_ 406 EstWhlBrkPrsStatRed 1;
BA_REL_ "GenSigTimeoutMsg" BU_SG_REL_ ADIMa_PCE SG_ 406 EstWhlBrkPrsStatRed 406;
BA_REL_ "GenSigTimeoutTime" BU_SG_REL_ ADIMa_PCE SG_ 406 EstWhlBrkPrsStatRed 50;
BA_REL_ "GenSigRxStartValue" BU_SG_REL_ EBOOST_OBD_PCE SG_ 406 EstWhlBrkPrsRRRed "0";
BA_REL_ "GenSigSuprvResp" BU_SG_REL_ EBOOST_OBD_PCE SG_ 406 EstWhlBrkPrsRRRed 1;
BA_REL_ "GenSigTimeoutMsg" BU_SG_REL_ EBOOST_OBD_PCE SG_ 406 EstWhlBrkPrsRRRed 406;
BA_REL_ "GenSigTimeoutTime" BU_SG_REL_ EBOOST_OBD_PCE SG_ 406 EstWhlBrkPrsRRRed 50;
BA_REL_ "GenSigRxStartValue" BU_SG_REL_ ADIMa_PCE SG_ 406 EstWhlBrkPrsRRRed "0";
BA_REL_ "GenSigSuprvResp" BU_SG_REL_ ADIMa_PCE SG_ 406 EstWhlBrkPrsRRRed 1;
BA_REL_ "GenSigTimeoutMsg" BU_SG_REL_ ADIMa_PCE SG_ 406 EstWhlBrkPrsRRRed 406;
BA_REL_ "GenSigTimeoutTime" BU_SG_REL_ ADIMa_PCE SG_ 406 EstWhlBrkPrsRRRed 50;
BA_REL_ "GenSigRxStartValue" BU_SG_REL_ EBOOST_OBD_PCE SG_ 406 EstWhlBrkPrsRFRed "0";
BA_REL_ "GenSigSuprvResp" BU_SG_REL_ EBOOST_OBD_PCE SG_ 406 EstWhlBrkPrsRFRed 1;
BA_REL_ "GenSigTimeoutMsg" BU_SG_REL_ EBOOST_OBD_PCE SG_ 406 EstWhlBrkPrsRFRed 406;
BA_REL_ "GenSigTimeoutTime" BU_SG_REL_ EBOOST_OBD_PCE SG_ 406 EstWhlBrkPrsRFRed 50;
BA_REL_ "GenSigRxStartValue" BU_SG_REL_ ADIMa_PCE SG_ 406 EstWhlBrkPrsRFRed "0";
BA_REL_ "GenSigSuprvResp" BU_SG_REL_ ADIMa_PCE SG_ 406 EstWhlBrkPrsRFRed 1;
BA_REL_ "GenSigTimeoutMsg" BU_SG_REL_ ADIMa_PCE SG_ 406 EstWhlBrkPrsRFRed 406;
BA_REL_ "GenSigTimeoutTime" BU_SG_REL_ ADIMa_PCE SG_ 406 EstWhlBrkPrsRFRed 50;
BA_REL_ "GenSigRxStartValue" BU_SG_REL_ EBOOST_OBD_PCE SG_ 406 EstWhlBrkPrsLRRed "0";
BA_REL_ "GenSigSuprvResp" BU_SG_REL_ EBOOST_OBD_PCE SG_ 406 EstWhlBrkPrsLRRed 1;
BA_REL_ "GenSigTimeoutMsg" BU_SG_REL_ EBOOST_OBD_PCE SG_ 406 EstWhlBrkPrsLRRed 406;
BA_REL_ "GenSigTimeoutTime" BU_SG_REL_ EBOOST_OBD_PCE SG_ 406 EstWhlBrkPrsLRRed 50;
BA_REL_ "GenSigRxStartValue" BU_SG_REL_ ADIMa_PCE SG_ 406 EstWhlBrkPrsLRRed "0";
BA_REL_ "GenSigSuprvResp" BU_SG_REL_ ADIMa_PCE SG_ 406 EstWhlBrkPrsLRRed 1;
BA_REL_ "GenSigTimeoutMsg" BU_SG_REL_ ADIMa_PCE SG_ 406 EstWhlBrkPrsLRRed 406;
BA_REL_ "GenSigTimeoutTime" BU_SG_REL_ ADIMa_PCE SG_ 406 EstWhlBrkPrsLRRed 50;
BA_REL_ "GenSigRxStartValue" BU_SG_REL_ EBOOST_OBD_PCE SG_ 406 EstWhlBrkPrsLFRed "0";
BA_REL_ "GenSigSuprvResp" BU_SG_REL_ EBOOST_OBD_PCE SG_ 406 EstWhlBrkPrsLFRed 1;
BA_REL_ "GenSigTimeoutMsg" BU_SG_REL_ EBOOST_OBD_PCE SG_ 406 EstWhlBrkPrsLFRed 406;
BA_REL_ "GenSigTimeoutTime" BU_SG_REL_ EBOOST_OBD_PCE SG_ 406 EstWhlBrkPrsLFRed 50;
BA_REL_ "GenSigRxStartValue" BU_SG_REL_ ADIMa_PCE SG_ 406 EstWhlBrkPrsLFRed "0";
BA_REL_ "GenSigSuprvResp" BU_SG_REL_ ADIMa_PCE SG_ 406 EstWhlBrkPrsLFRed 1;
BA_REL_ "GenSigTimeoutMsg" BU_SG_REL_ ADIMa_PCE SG_ 406 EstWhlBrkPrsLFRed 406;
BA_REL_ "GenSigTimeoutTime" BU_SG_REL_ ADIMa_PCE SG_ 406 EstWhlBrkPrsLFRed 50;
BA_REL_ "GenSigRxStartValue" BU_SG_REL_ EBOOST_OBD_PCE SG_ 406 BrkEstWhlPrsRedChksm "0";
BA_REL_ "GenSigRxStartValue" BU_SG_REL_ ADIMa_PCE SG_ 406 BrkEstWhlPrsRedChksm "0";
BA_REL_ "GenSigRxStartValue" BU_SG_REL_ EBOOST_OBD_PCE SG_ 406 BrkEstWhlPrsRedARC "0";
BA_REL_ "GenSigRxStartValue" BU_SG_REL_ ADIMa_PCE SG_ 406 BrkEstWhlPrsRedARC "0";
BA_REL_ "GenSigRxStartValue" BU_SG_REL_ EBOOST_OBD_PCE SG_ 312 PriCoPCmdMsgStat "Normal Communication";
BA_REL_ "GenSigSuprvResp" BU_SG_REL_ EBOOST_OBD_PCE SG_ 312 PriCoPCmdMsgStat 1;
BA_REL_ "GenSigTimeoutMsg" BU_SG_REL_ EBOOST_OBD_PCE SG_ 312 PriCoPCmdMsgStat 312;
BA_REL_ "GenSigTimeoutTime" BU_SG_REL_ EBOOST_OBD_PCE SG_ 312 PriCoPCmdMsgStat 25;
BA_REL_ "GenSigRxStartValue" BU_SG_REL_ ADIMa_PCE SG_ 312 PriCoPCmdMsgStat "Normal Communication";
BA_REL_ "GenSigSuprvResp" BU_SG_REL_ ADIMa_PCE SG_ 312 PriCoPCmdMsgStat 1;
BA_REL_ "GenSigTimeoutMsg" BU_SG_REL_ ADIMa_PCE SG_ 312 PriCoPCmdMsgStat 312;
BA_REL_ "GenSigTimeoutTime" BU_SG_REL_ ADIMa_PCE SG_ 312 PriCoPCmdMsgStat 25;
BA_REL_ "GenSigRxStartValue" BU_SG_REL_ EBOOST_OBD_PCE SG_ 312 PriADSCmdMsgStat "Normal Communication";
BA_REL_ "GenSigSuprvResp" BU_SG_REL_ EBOOST_OBD_PCE SG_ 312 PriADSCmdMsgStat 1;
BA_REL_ "GenSigTimeoutMsg" BU_SG_REL_ EBOOST_OBD_PCE SG_ 312 PriADSCmdMsgStat 312;
BA_REL_ "GenSigTimeoutTime" BU_SG_REL_ EBOOST_OBD_PCE SG_ 312 PriADSCmdMsgStat 25;
BA_REL_ "GenSigRxStartValue" BU_SG_REL_ ADIMa_PCE SG_ 312 PriADSCmdMsgStat "Normal Communication";
BA_REL_ "GenSigSuprvResp" BU_SG_REL_ ADIMa_PCE SG_ 312 PriADSCmdMsgStat 1;
BA_REL_ "GenSigTimeoutMsg" BU_SG_REL_ ADIMa_PCE SG_ 312 PriADSCmdMsgStat 312;
BA_REL_ "GenSigTimeoutTime" BU_SG_REL_ ADIMa_PCE SG_ 312 PriADSCmdMsgStat 25;
BA_REL_ "GenSigRxStartValue" BU_SG_REL_ EBOOST_OBD_PCE SG_ 312 PriBrkSysArbStat "Unknown";
BA_REL_ "GenSigSuprvResp" BU_SG_REL_ EBOOST_OBD_PCE SG_ 312 PriBrkSysArbStat 1;
BA_REL_ "GenSigTimeoutMsg" BU_SG_REL_ EBOOST_OBD_PCE SG_ 312 PriBrkSysArbStat 312;
BA_REL_ "GenSigTimeoutTime" BU_SG_REL_ EBOOST_OBD_PCE SG_ 312 PriBrkSysArbStat 25;
BA_REL_ "GenSigRxStartValue" BU_SG_REL_ ADIMa_PCE SG_ 312 PriBrkSysArbStat "Unknown";
BA_REL_ "GenSigSuprvResp" BU_SG_REL_ ADIMa_PCE SG_ 312 PriBrkSysArbStat 1;
BA_REL_ "GenSigTimeoutMsg" BU_SG_REL_ ADIMa_PCE SG_ 312 PriBrkSysArbStat 312;
BA_REL_ "GenSigTimeoutTime" BU_SG_REL_ ADIMa_PCE SG_ 312 PriBrkSysArbStat 25;
BA_REL_ "GenSigRxStartValue" BU_SG_REL_ ADIMa_PCE SG_ 312 PriBrkSysStatChksm "0";
BA_REL_ "GenSigRxStartValue" BU_SG_REL_ EBOOST_OBD_PCE SG_ 312 PriBrkSysStatChksm "0";
BA_REL_ "GenSigRxStartValue" BU_SG_REL_ ADIMa_PCE SG_ 312 PriBrkSysStatARC "0";
BA_REL_ "GenSigRxStartValue" BU_SG_REL_ EBOOST_OBD_PCE SG_ 312 PriBrkSysStatARC "0";
BA_REL_ "GenSigRxStartValue" BU_SG_REL_ ADIMa_PCE SG_ 312 PriBrkSysStat "0";
BA_REL_ "GenSigSuprvResp" BU_SG_REL_ ADIMa_PCE SG_ 312 PriBrkSysStat 1;
BA_REL_ "GenSigTimeoutMsg" BU_SG_REL_ ADIMa_PCE SG_ 312 PriBrkSysStat 312;
BA_REL_ "GenSigTimeoutTime" BU_SG_REL_ ADIMa_PCE SG_ 312 PriBrkSysStat 25;
BA_REL_ "GenSigRxStartValue" BU_SG_REL_ EBOOST_OBD_PCE SG_ 312 PriBrkSysStat "0";
BA_REL_ "GenSigSuprvResp" BU_SG_REL_ EBOOST_OBD_PCE SG_ 312 PriBrkSysStat 1;
BA_REL_ "GenSigTimeoutMsg" BU_SG_REL_ EBOOST_OBD_PCE SG_ 312 PriBrkSysStat 312;
BA_REL_ "GenSigTimeoutTime" BU_SG_REL_ EBOOST_OBD_PCE SG_ 312 PriBrkSysStat 25;
BA_REL_ "GenSigRxStartValue" BU_SG_REL_ ADIMa_PCE SG_ 312 PriBrkRngLmtgStat "0";
BA_REL_ "GenSigSuprvResp" BU_SG_REL_ ADIMa_PCE SG_ 312 PriBrkRngLmtgStat 1;
BA_REL_ "GenSigTimeoutMsg" BU_SG_REL_ ADIMa_PCE SG_ 312 PriBrkRngLmtgStat 312;
BA_REL_ "GenSigTimeoutTime" BU_SG_REL_ ADIMa_PCE SG_ 312 PriBrkRngLmtgStat 25;
BA_REL_ "GenSigRxStartValue" BU_SG_REL_ EBOOST_OBD_PCE SG_ 312 PriBrkRngLmtgStat "0";
BA_REL_ "GenSigSuprvResp" BU_SG_REL_ EBOOST_OBD_PCE SG_ 312 PriBrkRngLmtgStat 1;
BA_REL_ "GenSigTimeoutMsg" BU_SG_REL_ EBOOST_OBD_PCE SG_ 312 PriBrkRngLmtgStat 312;
BA_REL_ "GenSigTimeoutTime" BU_SG_REL_ EBOOST_OBD_PCE SG_ 312 PriBrkRngLmtgStat 25;
BA_REL_ "GenSigRxStartValue" BU_SG_REL_ ADIMa_PCE SG_ 312 PriBrkModSbSte "0";
BA_REL_ "GenSigSuprvResp" BU_SG_REL_ ADIMa_PCE SG_ 312 PriBrkModSbSte 1;
BA_REL_ "GenSigTimeoutMsg" BU_SG_REL_ ADIMa_PCE SG_ 312 PriBrkModSbSte 312;
BA_REL_ "GenSigTimeoutTime" BU_SG_REL_ ADIMa_PCE SG_ 312 PriBrkModSbSte 25;
BA_REL_ "GenSigRxStartValue" BU_SG_REL_ EBOOST_OBD_PCE SG_ 312 PriBrkModSbSte "0";
BA_REL_ "GenSigSuprvResp" BU_SG_REL_ EBOOST_OBD_PCE SG_ 312 PriBrkModSbSte 1;
BA_REL_ "GenSigTimeoutMsg" BU_SG_REL_ EBOOST_OBD_PCE SG_ 312 PriBrkModSbSte 312;
BA_REL_ "GenSigTimeoutTime" BU_SG_REL_ EBOOST_OBD_PCE SG_ 312 PriBrkModSbSte 25;
BA_REL_ "GenSigRxStartValue" BU_SG_REL_ ADIMa_PCE SG_ 312 PriDrvIntvtnMdDetTO "False";
BA_REL_ "GenSigSuprvResp" BU_SG_REL_ ADIMa_PCE SG_ 312 PriDrvIntvtnMdDetTO 1;
BA_REL_ "GenSigTimeoutMsg" BU_SG_REL_ ADIMa_PCE SG_ 312 PriDrvIntvtnMdDetTO 312;
BA_REL_ "GenSigTimeoutTime" BU_SG_REL_ ADIMa_PCE SG_ 312 PriDrvIntvtnMdDetTO 25;
BA_REL_ "GenSigRxStartValue" BU_SG_REL_ EBOOST_OBD_PCE SG_ 312 PriDrvIntvtnMdDetTO "False";
BA_REL_ "GenSigSuprvResp" BU_SG_REL_ EBOOST_OBD_PCE SG_ 312 PriDrvIntvtnMdDetTO 1;
BA_REL_ "GenSigTimeoutMsg" BU_SG_REL_ EBOOST_OBD_PCE SG_ 312 PriDrvIntvtnMdDetTO 312;
BA_REL_ "GenSigTimeoutTime" BU_SG_REL_ EBOOST_OBD_PCE SG_ 312 PriDrvIntvtnMdDetTO 25;
BA_REL_ "GenSigRxStartValue" BU_SG_REL_ EBOOST_OBD_PCE SG_ 312 PriBrkModCrtThrmlCap "0";
BA_REL_ "GenSigRxStartValue" BU_SG_REL_ ADIMa_PCE SG_ 312 PriBrkModCrtThrmlCap "0";
BA_REL_ "GenSigRxStartValue" BU_SG_REL_ ADIMa_PCE SG_ 404 SpltMuCntrlRedV "Valid";
BA_REL_ "GenSigVBitResp" BU_SG_REL_ ADIMa_PCE SG_ 404 SpltMuCntrlRed 1;
BA_REL_ "GenSigRxStartValue" BU_SG_REL_ ADIMa_PCE SG_ 404 SpltMuCntrlRed "Inactive";
BA_REL_ "GenSigSuprvResp" BU_SG_REL_ ADIMa_PCE SG_ 404 SpltMuCntrlRed 1;
BA_REL_ "GenSigTimeoutMsg" BU_SG_REL_ ADIMa_PCE SG_ 404 SpltMuCntrlRed 404;
BA_REL_ "GenSigTimeoutTime" BU_SG_REL_ ADIMa_PCE SG_ 404 SpltMuCntrlRed 50;
BA_REL_ "GenSigSuprvResp" BU_SG_REL_ ADIMa_PCE SG_ 404 PriMaxAvlBrkTrqGradRed 1;
BA_REL_ "GenSigTimeoutMsg" BU_SG_REL_ ADIMa_PCE SG_ 404 PriMaxAvlBrkTrqGradRed 404;
BA_REL_ "GenSigTimeoutTime" BU_SG_REL_ ADIMa_PCE SG_ 404 PriMaxAvlBrkTrqGradRed 50;
BA_REL_ "GenSigSuprvResp" BU_SG_REL_ ADIMa_PCE SG_ 404 PriMaxAvlBrkTrqRed 1;
BA_REL_ "GenSigTimeoutMsg" BU_SG_REL_ ADIMa_PCE SG_ 404 PriMaxAvlBrkTrqRed 404;
BA_REL_ "GenSigTimeoutTime" BU_SG_REL_ ADIMa_PCE SG_ 404 PriMaxAvlBrkTrqRed 50;
BA_REL_ "GenSigSuprvResp" BU_SG_REL_ ADIMa_PCE SG_ 404 PriEstSrfcMuTypRed 1;
BA_REL_ "GenSigTimeoutMsg" BU_SG_REL_ ADIMa_PCE SG_ 404 PriEstSrfcMuTypRed 404;
BA_REL_ "GenSigTimeoutTime" BU_SG_REL_ ADIMa_PCE SG_ 404 PriEstSrfcMuTypRed 50;
BA_REL_ "GenSigVBitResp" BU_SG_REL_ ADIMa_PCE SG_ 404 PriEstSrfcMuCapRed 1;
BA_REL_ "GenSigSuprvResp" BU_SG_REL_ ADIMa_PCE SG_ 404 PriEstSrfcMuCapRed 1;
BA_REL_ "GenSigTimeoutMsg" BU_SG_REL_ ADIMa_PCE SG_ 404 PriEstSrfcMuCapRed 404;
BA_REL_ "GenSigTimeoutTime" BU_SG_REL_ ADIMa_PCE SG_ 404 PriEstSrfcMuCapRed 50;
BA_REL_ "GenSigSuprvResp" BU_SG_REL_ ADIMa_PCE SG_ 404 PriBrkModCapStatRed 1;
BA_REL_ "GenSigTimeoutMsg" BU_SG_REL_ ADIMa_PCE SG_ 404 PriBrkModCapStatRed 404;
BA_REL_ "GenSigTimeoutTime" BU_SG_REL_ ADIMa_PCE SG_ 404 PriBrkModCapStatRed 50;
BA_REL_ "GenSigSuprvResp" BU_SG_REL_ ADIMa_PCE SG_ 310 Diagpresreqstat 1;
BA_REL_ "GenSigTimeoutMsg" BU_SG_REL_ ADIMa_PCE SG_ 310 Diagpresreqstat 310;
BA_REL_ "GenSigTimeoutTime" BU_SG_REL_ ADIMa_PCE SG_ 310 Diagpresreqstat 50;
BA_REL_ "GenSigSuprvResp" BU_SG_REL_ ADIMa_PCE SG_ 310 Diagpresreqavl 1;
BA_REL_ "GenSigTimeoutMsg" BU_SG_REL_ ADIMa_PCE SG_ 310 Diagpresreqavl 310;
BA_REL_ "GenSigTimeoutTime" BU_SG_REL_ ADIMa_PCE SG_ 310 Diagpresreqavl 50;
BA_REL_ "GenSigRxStartValue" BU_SG_REL_ ADIMa_PCE SG_ 310 PriSuffBrkTrqStdstl "False";
BA_REL_ "GenSigSuprvResp" BU_SG_REL_ ADIMa_PCE SG_ 310 PriSuffBrkTrqStdstl 1;
BA_REL_ "GenSigTimeoutMsg" BU_SG_REL_ ADIMa_PCE SG_ 310 PriSuffBrkTrqStdstl 310;
BA_REL_ "GenSigTimeoutTime" BU_SG_REL_ ADIMa_PCE SG_ 310 PriSuffBrkTrqStdstl 25;
BA_REL_ "GenSigRxStartValue" BU_SG_REL_ ADIMa_PCE SG_ 310 PriAutoEstBrkTrqApd "0";
BA_REL_ "GenSigSuprvResp" BU_SG_REL_ ADIMa_PCE SG_ 310 PriAutoEstBrkTrqApd 1;
BA_REL_ "GenSigTimeoutMsg" BU_SG_REL_ ADIMa_PCE SG_ 310 PriAutoEstBrkTrqApd 310;
BA_REL_ "GenSigTimeoutTime" BU_SG_REL_ ADIMa_PCE SG_ 310 PriAutoEstBrkTrqApd 25;
BA_REL_ "GenSigRxStartValue" BU_SG_REL_ EBOOST_OBD_PCE SG_ 310 PriAutoBrkSysDrInfcStat "Unknown";
BA_REL_ "GenSigSuprvResp" BU_SG_REL_ EBOOST_OBD_PCE SG_ 310 PriAutoBrkSysDrInfcStat 1;
BA_REL_ "GenSigTimeoutMsg" BU_SG_REL_ EBOOST_OBD_PCE SG_ 310 PriAutoBrkSysDrInfcStat 310;
BA_REL_ "GenSigTimeoutTime" BU_SG_REL_ EBOOST_OBD_PCE SG_ 310 PriAutoBrkSysDrInfcStat 25;
BA_REL_ "GenSigRxStartValue" BU_SG_REL_ ADIMa_PCE SG_ 310 PriAutoBrkSysDrInfcStat "0";
BA_REL_ "GenSigSuprvResp" BU_SG_REL_ ADIMa_PCE SG_ 310 PriAutoBrkSysDrInfcStat 1;
BA_REL_ "GenSigTimeoutMsg" BU_SG_REL_ ADIMa_PCE SG_ 310 PriAutoBrkSysDrInfcStat 310;
BA_REL_ "GenSigTimeoutTime" BU_SG_REL_ ADIMa_PCE SG_ 310 PriAutoBrkSysDrInfcStat 25;
BA_REL_ "GenSigRxStartValue" BU_SG_REL_ ADIMa_PCE SG_ 310 PriAutoArbBrkTrqReq "0";
BA_REL_ "GenSigSuprvResp" BU_SG_REL_ ADIMa_PCE SG_ 310 PriAutoArbBrkTrqReq 1;
BA_REL_ "GenSigTimeoutMsg" BU_SG_REL_ ADIMa_PCE SG_ 310 PriAutoArbBrkTrqReq 310;
BA_REL_ "GenSigTimeoutTime" BU_SG_REL_ ADIMa_PCE SG_ 310 PriAutoArbBrkTrqReq 25;
BA_REL_ "GenSigRxStartValue" BU_SG_REL_ ADIMa_PCE SG_ 310 PriBrkModStat "0";
BA_REL_ "GenSigSuprvResp" BU_SG_REL_ ADIMa_PCE SG_ 310 PriBrkModStat 1;
BA_REL_ "GenSigTimeoutMsg" BU_SG_REL_ ADIMa_PCE SG_ 310 PriBrkModStat 310;
BA_REL_ "GenSigTimeoutTime" BU_SG_REL_ ADIMa_PCE SG_ 310 PriBrkModStat 25;
BA_REL_ "GenSigRxStartValue" BU_SG_REL_ ADIMa_PCE SG_ 310 PriAutoAxlTrqReqStatChksm "0";
BA_REL_ "GenSigRxStartValue" BU_SG_REL_ ADIMa_PCE SG_ 310 PriAutoAxlTrqReqStatARC "0";
BA_REL_ "GenSigRxStartValue" BU_SG_REL_ ADIMa_PCE SG_ 310 PriAutoEstBrkTrqAppStat "0";
BA_REL_ "GenSigSuprvResp" BU_SG_REL_ ADIMa_PCE SG_ 310 PriAutoEstBrkTrqAppStat 1;
BA_REL_ "GenSigTimeoutMsg" BU_SG_REL_ ADIMa_PCE SG_ 310 PriAutoEstBrkTrqAppStat 310;
BA_REL_ "GenSigTimeoutTime" BU_SG_REL_ ADIMa_PCE SG_ 310 PriAutoEstBrkTrqAppStat 25;
BA_REL_ "GenSigSuprvResp" BU_SG_REL_ ADIMa_PCE SG_ 341 Vltmtr 1;
BA_REL_ "GenSigTimeoutMsg" BU_SG_REL_ ADIMa_PCE SG_ 341 Vltmtr 341;
BA_REL_ "GenSigTimeoutTime" BU_SG_REL_ ADIMa_PCE SG_ 341 Vltmtr 25;
BA_REL_ "GenSigSuprvResp" BU_SG_REL_ ADIMa_PCE SG_ 341 EstMtrTrq 1;
BA_REL_ "GenSigTimeoutMsg" BU_SG_REL_ ADIMa_PCE SG_ 341 EstMtrTrq 341;
BA_REL_ "GenSigTimeoutTime" BU_SG_REL_ ADIMa_PCE SG_ 341 EstMtrTrq 25;
BA_REL_ "GenSigRxStartValue" BU_SG_REL_ EBCM_PCE SG_ 341 ExtBrkReqRespChksm "0";
BA_REL_ "GenSigRxStartValue" BU_SG_REL_ EBCM_PCE SG_ 341 ExtBrkReqRespARC "0";
BA_REL_ "GenSigRxStartValue" BU_SG_REL_ EBCM_PCE SG_ 341 PrkBrkReqiB "0";
BA_REL_ "GenSigSuprvResp" BU_SG_REL_ EBCM_PCE SG_ 341 PrkBrkReqiB 1;
BA_REL_ "GenSigTimeoutMsg" BU_SG_REL_ EBCM_PCE SG_ 341 PrkBrkReqiB 350;
BA_REL_ "GenSigTimeoutTime" BU_SG_REL_ EBCM_PCE SG_ 341 PrkBrkReqiB 25;
BA_REL_ "GenSigRxStartValue" BU_SG_REL_ EBCM_PCE SG_ 341 ExtBrkReqStat "0";
BA_REL_ "GenSigSuprvResp" BU_SG_REL_ EBCM_PCE SG_ 341 ExtBrkReqStat 1;
BA_REL_ "GenSigTimeoutMsg" BU_SG_REL_ EBCM_PCE SG_ 341 ExtBrkReqStat 350;
BA_REL_ "GenSigTimeoutTime" BU_SG_REL_ EBCM_PCE SG_ 341 ExtBrkReqStat 25;
BA_REL_ "GenSigSuprvResp" BU_SG_REL_ ADIMa_PCE SG_ 341 StrkOtptRodTgtQlfr 1;
BA_REL_ "GenSigTimeoutMsg" BU_SG_REL_ ADIMa_PCE SG_ 341 StrkOtptRodTgtQlfr 341;
BA_REL_ "GenSigTimeoutTime" BU_SG_REL_ ADIMa_PCE SG_ 341 StrkOtptRodTgtQlfr 25;
BA_REL_ "GenSigRxStartValue" BU_SG_REL_ EBCM_PCE SG_ 341 StrkOtptRodTgtQlfr "0";
BA_REL_ "GenSigSuprvResp" BU_SG_REL_ EBCM_PCE SG_ 341 StrkOtptRodTgtQlfr 1;
BA_REL_ "GenSigTimeoutMsg" BU_SG_REL_ EBCM_PCE SG_ 341 StrkOtptRodTgtQlfr 350;
BA_REL_ "GenSigTimeoutTime" BU_SG_REL_ EBCM_PCE SG_ 341 StrkOtptRodTgtQlfr 25;
BA_REL_ "GenSigSuprvResp" BU_SG_REL_ ADIMa_PCE SG_ 341 StrkOtptRodActlQlfr 1;
BA_REL_ "GenSigTimeoutMsg" BU_SG_REL_ ADIMa_PCE SG_ 341 StrkOtptRodActlQlfr 341;
BA_REL_ "GenSigTimeoutTime" BU_SG_REL_ ADIMa_PCE SG_ 341 StrkOtptRodActlQlfr 25;
BA_REL_ "GenSigRxStartValue" BU_SG_REL_ EBCM_PCE SG_ 341 StrkOtptRodActlQlfr "0";
BA_REL_ "GenSigSuprvResp" BU_SG_REL_ EBCM_PCE SG_ 341 StrkOtptRodActlQlfr 1;
BA_REL_ "GenSigTimeoutMsg" BU_SG_REL_ EBCM_PCE SG_ 341 StrkOtptRodActlQlfr 350;
BA_REL_ "GenSigTimeoutTime" BU_SG_REL_ EBCM_PCE SG_ 341 StrkOtptRodActlQlfr 25;
BA_REL_ "GenSigSuprvResp" BU_SG_REL_ ADIMa_PCE SG_ 341 StrkOtptRodActl 1;
BA_REL_ "GenSigTimeoutMsg" BU_SG_REL_ ADIMa_PCE SG_ 341 StrkOtptRodActl 341;
BA_REL_ "GenSigTimeoutTime" BU_SG_REL_ ADIMa_PCE SG_ 341 StrkOtptRodActl 25;
BA_REL_ "GenSigRxStartValue" BU_SG_REL_ EBCM_PCE SG_ 341 StrkOtptRodActl "0";
BA_REL_ "GenSigSuprvResp" BU_SG_REL_ EBCM_PCE SG_ 341 StrkOtptRodActl 1;
BA_REL_ "GenSigTimeoutMsg" BU_SG_REL_ EBCM_PCE SG_ 341 StrkOtptRodActl 350;
BA_REL_ "GenSigTimeoutTime" BU_SG_REL_ EBCM_PCE SG_ 341 StrkOtptRodActl 25;
BA_REL_ "GenSigSuprvResp" BU_SG_REL_ ADIMa_PCE SG_ 341 StrkOtptRodTgt 1;
BA_REL_ "GenSigTimeoutMsg" BU_SG_REL_ ADIMa_PCE SG_ 341 StrkOtptRodTgt 341;
BA_REL_ "GenSigTimeoutTime" BU_SG_REL_ ADIMa_PCE SG_ 341 StrkOtptRodTgt 25;
BA_REL_ "GenSigRxStartValue" BU_SG_REL_ EBCM_PCE SG_ 341 StrkOtptRodTgt "0";
BA_REL_ "GenSigSuprvResp" BU_SG_REL_ EBCM_PCE SG_ 341 StrkOtptRodTgt 1;
BA_REL_ "GenSigTimeoutMsg" BU_SG_REL_ EBCM_PCE SG_ 341 StrkOtptRodTgt 350;
BA_REL_ "GenSigTimeoutTime" BU_SG_REL_ EBCM_PCE SG_ 341 StrkOtptRodTgt 25;
BA_REL_ "GenSigRxStartValue" BU_SG_REL_ EBCM_PCE SG_ 403 PedOvrdBrkiBst "0";
BA_REL_ "GenSigSuprvResp" BU_SG_REL_ EBCM_PCE SG_ 403 PedOvrdBrkiBst 1;
BA_REL_ "GenSigTimeoutMsg" BU_SG_REL_ EBCM_PCE SG_ 403 PedOvrdBrkiBst 403;
BA_REL_ "GenSigTimeoutTime" BU_SG_REL_ EBCM_PCE SG_ 403 PedOvrdBrkiBst 50;
BA_REL_ "GenSigRxStartValue" BU_SG_REL_ EBCM_PCE SG_ 403 iBstStat "0";
BA_REL_ "GenSigSuprvResp" BU_SG_REL_ EBCM_PCE SG_ 403 iBstStat 1;
BA_REL_ "GenSigTimeoutMsg" BU_SG_REL_ EBCM_PCE SG_ 403 iBstStat 403;
BA_REL_ "GenSigTimeoutTime" BU_SG_REL_ EBCM_PCE SG_ 403 iBstStat 50;
BA_REL_ "GenSigRxStartValue" BU_SG_REL_ EBCM_PCE SG_ 403 HbcSptRedq "False";
BA_REL_ "GenSigSuprvResp" BU_SG_REL_ EBCM_PCE SG_ 403 HbcSptRedq 1;
BA_REL_ "GenSigTimeoutMsg" BU_SG_REL_ EBCM_PCE SG_ 403 HbcSptRedq 403;
BA_REL_ "GenSigTimeoutTime" BU_SG_REL_ EBCM_PCE SG_ 403 HbcSptRedq 50;
BA_REL_ "GenSigRxStartValue" BU_SG_REL_ EBCM_PCE SG_ 403 eBstEspCompIdnx "0";
BA_REL_ "GenSigSuprvResp" BU_SG_REL_ EBCM_PCE SG_ 403 eBstEspCompIdnx 1;
BA_REL_ "GenSigTimeoutMsg" BU_SG_REL_ EBCM_PCE SG_ 403 eBstEspCompIdnx 403;
BA_REL_ "GenSigTimeoutTime" BU_SG_REL_ EBCM_PCE SG_ 403 eBstEspCompIdnx 50;
BA_REL_ "GenSigRxStartValue" BU_SG_REL_ EBCM_PCE SG_ 403 eBstDiagAtv "False";
BA_REL_ "GenSigSuprvResp" BU_SG_REL_ EBCM_PCE SG_ 403 eBstDiagAtv 1;
BA_REL_ "GenSigTimeoutMsg" BU_SG_REL_ EBCM_PCE SG_ 403 eBstDiagAtv 403;
BA_REL_ "GenSigTimeoutTime" BU_SG_REL_ EBCM_PCE SG_ 403 eBstDiagAtv 50;
BA_REL_ "GenSigRxStartValue" BU_SG_REL_ EBCM_PCE SG_ 403 EBstSteChksm "0";
BA_REL_ "GenSigRxStartValue" BU_SG_REL_ EBCM_PCE SG_ 403 EBstSteARC "0";
BA_REL_ "GenSigRxStartValue" BU_SG_REL_ EBCM_PCE SG_ 403 EBstRnotPrsQlfr "0";
BA_REL_ "GenSigSuprvResp" BU_SG_REL_ EBCM_PCE SG_ 403 EBstRnotPrsQlfr 1;
BA_REL_ "GenSigTimeoutMsg" BU_SG_REL_ EBCM_PCE SG_ 403 EBstRnotPrsQlfr 403;
BA_REL_ "GenSigTimeoutTime" BU_SG_REL_ EBCM_PCE SG_ 403 EBstRnotPrsQlfr 50;
BA_REL_ "GenSigRxStartValue" BU_SG_REL_ EBCM_PCE SG_ 403 EBstRnotPrs "0";
BA_REL_ "GenSigSuprvResp" BU_SG_REL_ EBCM_PCE SG_ 403 EBstRnotPrs 1;
BA_REL_ "GenSigTimeoutMsg" BU_SG_REL_ EBCM_PCE SG_ 403 EBstRnotPrs 403;
BA_REL_ "GenSigTimeoutTime" BU_SG_REL_ EBCM_PCE SG_ 403 EBstRnotPrs 50;
BA_REL_ "GenSigRxStartValue" BU_SG_REL_ EBCM_PCE SG_ 403 BrkPedApdQlfr "0";
BA_REL_ "GenSigSuprvResp" BU_SG_REL_ EBCM_PCE SG_ 403 BrkPedApdQlfr 1;
BA_REL_ "GenSigTimeoutMsg" BU_SG_REL_ EBCM_PCE SG_ 403 BrkPedApdQlfr 403;
BA_REL_ "GenSigTimeoutTime" BU_SG_REL_ EBCM_PCE SG_ 403 BrkPedApdQlfr 50;
BA_REL_ "GenSigRxStartValue" BU_SG_REL_ EBCM_PCE SG_ 403 BrkPedApd "False";
BA_REL_ "GenSigSuprvResp" BU_SG_REL_ EBCM_PCE SG_ 403 BrkPedApd 1;
BA_REL_ "GenSigTimeoutMsg" BU_SG_REL_ EBCM_PCE SG_ 403 BrkPedApd 403;
BA_REL_ "GenSigTimeoutTime" BU_SG_REL_ EBCM_PCE SG_ 403 BrkPedApd 50;
BA_REL_ "GenSigRxStartValue" BU_SG_REL_ EBCM_PCE SG_ 349 SecCoPCmdMsgStatRed "Normal Communication";
BA_REL_ "GenSigSuprvResp" BU_SG_REL_ EBCM_PCE SG_ 349 SecCoPCmdMsgStatRed 1;
BA_REL_ "GenSigTimeoutMsg" BU_SG_REL_ EBCM_PCE SG_ 349 SecCoPCmdMsgStatRed 349;
BA_REL_ "GenSigTimeoutTime" BU_SG_REL_ EBCM_PCE SG_ 349 SecCoPCmdMsgStatRed 25;
BA_REL_ "GenSigRxStartValue" BU_SG_REL_ ADIMa_PCE SG_ 349 SecCoPCmdMsgStatRed "Normal Communication";
BA_REL_ "GenSigSuprvResp" BU_SG_REL_ ADIMa_PCE SG_ 349 SecCoPCmdMsgStatRed 1;
BA_REL_ "GenSigTimeoutMsg" BU_SG_REL_ ADIMa_PCE SG_ 349 SecCoPCmdMsgStatRed 349;
BA_REL_ "GenSigTimeoutTime" BU_SG_REL_ ADIMa_PCE SG_ 349 SecCoPCmdMsgStatRed 25;
BA_REL_ "GenSigRxStartValue" BU_SG_REL_ EBCM_PCE SG_ 349 SecBrkSysArbStatRed "Unknown";
BA_REL_ "GenSigSuprvResp" BU_SG_REL_ EBCM_PCE SG_ 349 SecBrkSysArbStatRed 1;
BA_REL_ "GenSigTimeoutMsg" BU_SG_REL_ EBCM_PCE SG_ 349 SecBrkSysArbStatRed 349;
BA_REL_ "GenSigTimeoutTime" BU_SG_REL_ EBCM_PCE SG_ 349 SecBrkSysArbStatRed 25;
BA_REL_ "GenSigRxStartValue" BU_SG_REL_ ADIMa_PCE SG_ 349 SecBrkSysArbStatRed "Unknown";
BA_REL_ "GenSigSuprvResp" BU_SG_REL_ ADIMa_PCE SG_ 349 SecBrkSysArbStatRed 1;
BA_REL_ "GenSigTimeoutMsg" BU_SG_REL_ ADIMa_PCE SG_ 349 SecBrkSysArbStatRed 349;
BA_REL_ "GenSigTimeoutTime" BU_SG_REL_ ADIMa_PCE SG_ 349 SecBrkSysArbStatRed 25;
BA_REL_ "GenSigRxStartValue" BU_SG_REL_ EBCM_PCE SG_ 349 SecADSCmdMsgStatRed "Normal Communication";
BA_REL_ "GenSigSuprvResp" BU_SG_REL_ EBCM_PCE SG_ 349 SecADSCmdMsgStatRed 1;
BA_REL_ "GenSigTimeoutMsg" BU_SG_REL_ EBCM_PCE SG_ 349 SecADSCmdMsgStatRed 349;
BA_REL_ "GenSigTimeoutTime" BU_SG_REL_ EBCM_PCE SG_ 349 SecADSCmdMsgStatRed 25;
BA_REL_ "GenSigRxStartValue" BU_SG_REL_ ADIMa_PCE SG_ 349 SecADSCmdMsgStatRed "Normal Communication";
BA_REL_ "GenSigSuprvResp" BU_SG_REL_ ADIMa_PCE SG_ 349 SecADSCmdMsgStatRed 1;
BA_REL_ "GenSigTimeoutMsg" BU_SG_REL_ ADIMa_PCE SG_ 349 SecADSCmdMsgStatRed 349;
BA_REL_ "GenSigTimeoutTime" BU_SG_REL_ ADIMa_PCE SG_ 349 SecADSCmdMsgStatRed 25;
BA_REL_ "GenSigRxStartValue" BU_SG_REL_ ADIMa_PCE SG_ 349 SecBrkSysStatRedChksm "0";
BA_REL_ "GenSigRxStartValue" BU_SG_REL_ EBCM_PCE SG_ 349 SecBrkSysStatRedChksm "0";
BA_REL_ "GenSigRxStartValue" BU_SG_REL_ ADIMa_PCE SG_ 349 SecBrkSysStatRedARC "0";
BA_REL_ "GenSigRxStartValue" BU_SG_REL_ EBCM_PCE SG_ 349 SecBrkSysStatRedARC "0";
BA_REL_ "GenSigRxStartValue" BU_SG_REL_ ADIMa_PCE SG_ 349 SecBrkModSbSteRed "0";
BA_REL_ "GenSigSuprvResp" BU_SG_REL_ ADIMa_PCE SG_ 349 SecBrkModSbSteRed 1;
BA_REL_ "GenSigTimeoutMsg" BU_SG_REL_ ADIMa_PCE SG_ 349 SecBrkModSbSteRed 349;
BA_REL_ "GenSigTimeoutTime" BU_SG_REL_ ADIMa_PCE SG_ 349 SecBrkModSbSteRed 25;
BA_REL_ "GenSigRxStartValue" BU_SG_REL_ EBCM_PCE SG_ 349 SecBrkModSbSteRed "0";
BA_REL_ "GenSigSuprvResp" BU_SG_REL_ EBCM_PCE SG_ 349 SecBrkModSbSteRed 1;
BA_REL_ "GenSigTimeoutMsg" BU_SG_REL_ EBCM_PCE SG_ 349 SecBrkModSbSteRed 349;
BA_REL_ "GenSigTimeoutTime" BU_SG_REL_ EBCM_PCE SG_ 349 SecBrkModSbSteRed 25;
BA_REL_ "GenSigRxStartValue" BU_SG_REL_ ADIMa_PCE SG_ 349 SecBrkSysStatRed "0";
BA_REL_ "GenSigSuprvResp" BU_SG_REL_ ADIMa_PCE SG_ 349 SecBrkSysStatRed 1;
BA_REL_ "GenSigTimeoutMsg" BU_SG_REL_ ADIMa_PCE SG_ 349 SecBrkSysStatRed 349;
BA_REL_ "GenSigTimeoutTime" BU_SG_REL_ ADIMa_PCE SG_ 349 SecBrkSysStatRed 25;
BA_REL_ "GenSigRxStartValue" BU_SG_REL_ EBCM_PCE SG_ 349 SecBrkSysStatRed "0";
BA_REL_ "GenSigSuprvResp" BU_SG_REL_ EBCM_PCE SG_ 349 SecBrkSysStatRed 1;
BA_REL_ "GenSigTimeoutMsg" BU_SG_REL_ EBCM_PCE SG_ 349 SecBrkSysStatRed 349;
BA_REL_ "GenSigTimeoutTime" BU_SG_REL_ EBCM_PCE SG_ 349 SecBrkSysStatRed 25;
BA_REL_ "GenSigRxStartValue" BU_SG_REL_ ADIMa_PCE SG_ 349 SecBrkRngLmtgStatRed "0";
BA_REL_ "GenSigSuprvResp" BU_SG_REL_ ADIMa_PCE SG_ 349 SecBrkRngLmtgStatRed 1;
BA_REL_ "GenSigTimeoutMsg" BU_SG_REL_ ADIMa_PCE SG_ 349 SecBrkRngLmtgStatRed 349;
BA_REL_ "GenSigTimeoutTime" BU_SG_REL_ ADIMa_PCE SG_ 349 SecBrkRngLmtgStatRed 25;
BA_REL_ "GenSigRxStartValue" BU_SG_REL_ EBCM_PCE SG_ 349 SecBrkRngLmtgStatRed "0";
BA_REL_ "GenSigSuprvResp" BU_SG_REL_ EBCM_PCE SG_ 349 SecBrkRngLmtgStatRed 1;
BA_REL_ "GenSigTimeoutMsg" BU_SG_REL_ EBCM_PCE SG_ 349 SecBrkRngLmtgStatRed 349;
BA_REL_ "GenSigTimeoutTime" BU_SG_REL_ EBCM_PCE SG_ 349 SecBrkRngLmtgStatRed 25;
BA_REL_ "GenSigRxStartValue" BU_SG_REL_ ADIMa_PCE SG_ 349 SecBrkModCrtThrmlCapRed "0";
BA_REL_ "GenSigRxStartValue" BU_SG_REL_ EBCM_PCE SG_ 349 SecBrkModCrtThrmlCapRed "0";
BA_REL_ "GenSigSuprvResp" BU_SG_REL_ EBCM_PCE SG_ 349 SecBrkModCrtThrmlCapRed 1;
BA_REL_ "GenSigTimeoutMsg" BU_SG_REL_ EBCM_PCE SG_ 349 SecBrkModCrtThrmlCapRed 349;
BA_REL_ "GenSigTimeoutTime" BU_SG_REL_ EBCM_PCE SG_ 349 SecBrkModCrtThrmlCapRed 25;
BA_REL_ "GenSigRxStartValue" BU_SG_REL_ ADIMa_PCE SG_ 349 SecDrvIntvtnMdDetTORed "False";
BA_REL_ "GenSigSuprvResp" BU_SG_REL_ ADIMa_PCE SG_ 349 SecDrvIntvtnMdDetTORed 1;
BA_REL_ "GenSigTimeoutMsg" BU_SG_REL_ ADIMa_PCE SG_ 349 SecDrvIntvtnMdDetTORed 349;
BA_REL_ "GenSigTimeoutTime" BU_SG_REL_ ADIMa_PCE SG_ 349 SecDrvIntvtnMdDetTORed 25;
BA_REL_ "GenSigRxStartValue" BU_SG_REL_ EBCM_PCE SG_ 349 SecDrvIntvtnMdDetTORed "False";
BA_REL_ "GenSigSuprvResp" BU_SG_REL_ EBCM_PCE SG_ 349 SecDrvIntvtnMdDetTORed 1;
BA_REL_ "GenSigTimeoutMsg" BU_SG_REL_ EBCM_PCE SG_ 349 SecDrvIntvtnMdDetTORed 349;
BA_REL_ "GenSigTimeoutTime" BU_SG_REL_ EBCM_PCE SG_ 349 SecDrvIntvtnMdDetTORed 25;
BA_REL_ "GenSigSuprvResp" BU_SG_REL_ ADIMa_PCE SG_ 402 SecEstSrfcMuTypRed 1;
BA_REL_ "GenSigTimeoutMsg" BU_SG_REL_ ADIMa_PCE SG_ 402 SecEstSrfcMuTypRed 402;
BA_REL_ "GenSigTimeoutTime" BU_SG_REL_ ADIMa_PCE SG_ 402 SecEstSrfcMuTypRed 50;
BA_REL_ "GenSigSuprvResp" BU_SG_REL_ ADIMa_PCE SG_ 402 SecEstSrfcMuCapRedV 1;
BA_REL_ "GenSigTimeoutMsg" BU_SG_REL_ ADIMa_PCE SG_ 402 SecEstSrfcMuCapRedV 402;
BA_REL_ "GenSigTimeoutTime" BU_SG_REL_ ADIMa_PCE SG_ 402 SecEstSrfcMuCapRedV 50;
BA_REL_ "GenSigVBitResp" BU_SG_REL_ ADIMa_PCE SG_ 402 SecEstSrfcMuCapRed 1;
BA_REL_ "GenSigSuprvResp" BU_SG_REL_ ADIMa_PCE SG_ 402 SecEstSrfcMuCapRed 1;
BA_REL_ "GenSigTimeoutMsg" BU_SG_REL_ ADIMa_PCE SG_ 402 SecEstSrfcMuCapRed 402;
BA_REL_ "GenSigTimeoutTime" BU_SG_REL_ ADIMa_PCE SG_ 402 SecEstSrfcMuCapRed 50;
BA_REL_ "GenSigSuprvResp" BU_SG_REL_ ADIMa_PCE SG_ 402 SecBrkModCapRedStat 1;
BA_REL_ "GenSigTimeoutMsg" BU_SG_REL_ ADIMa_PCE SG_ 402 SecBrkModCapRedStat 404;
BA_REL_ "GenSigTimeoutTime" BU_SG_REL_ ADIMa_PCE SG_ 402 SecBrkModCapRedStat 50;
BA_REL_ "GenSigSuprvResp" BU_SG_REL_ ADIMa_PCE SG_ 402 SecMaxAvlBrkTrqRed 1;
BA_REL_ "GenSigTimeoutMsg" BU_SG_REL_ ADIMa_PCE SG_ 402 SecMaxAvlBrkTrqRed 402;
BA_REL_ "GenSigTimeoutTime" BU_SG_REL_ ADIMa_PCE SG_ 402 SecMaxAvlBrkTrqRed 50;
BA_REL_ "GenSigSuprvResp" BU_SG_REL_ ADIMa_PCE SG_ 402 SecMaxAvlBrkTrqGradRed 1;
BA_REL_ "GenSigTimeoutMsg" BU_SG_REL_ ADIMa_PCE SG_ 402 SecMaxAvlBrkTrqGradRed 402;
BA_REL_ "GenSigTimeoutTime" BU_SG_REL_ ADIMa_PCE SG_ 402 SecMaxAvlBrkTrqGradRed 50;
BA_REL_ "GenSigRxStartValue" BU_SG_REL_ ADIMa_PCE SG_ 346 SecAutoAxlTrqReqStatChksm "0";
BA_REL_ "GenSigRxStartValue" BU_SG_REL_ ADIMa_PCE SG_ 346 SecAutoAxlTrqReqStatARC "0";
BA_REL_ "GenSigRxStartValue" BU_SG_REL_ ADIMa_PCE SG_ 346 SecAutoEstBrkTrqAppStat "0";
BA_REL_ "GenSigSuprvResp" BU_SG_REL_ ADIMa_PCE SG_ 346 SecAutoEstBrkTrqAppStat 1;
BA_REL_ "GenSigTimeoutMsg" BU_SG_REL_ ADIMa_PCE SG_ 346 SecAutoEstBrkTrqAppStat 346;
BA_REL_ "GenSigTimeoutTime" BU_SG_REL_ ADIMa_PCE SG_ 346 SecAutoEstBrkTrqAppStat 10;
BA_REL_ "GenSigRxStartValue" BU_SG_REL_ ADIMa_PCE SG_ 346 SecBrkModStat "0";
BA_REL_ "GenSigSuprvResp" BU_SG_REL_ ADIMa_PCE SG_ 346 SecBrkModStat 1;
BA_REL_ "GenSigTimeoutMsg" BU_SG_REL_ ADIMa_PCE SG_ 346 SecBrkModStat 346;
BA_REL_ "GenSigTimeoutTime" BU_SG_REL_ ADIMa_PCE SG_ 346 SecBrkModStat 10;
BA_REL_ "GenSigRxStartValue" BU_SG_REL_ EBCM_PCE SG_ 346 SecAutoBrkSysDrInfcStat "Unknown";
BA_REL_ "GenSigSuprvResp" BU_SG_REL_ EBCM_PCE SG_ 346 SecAutoBrkSysDrInfcStat 1;
BA_REL_ "GenSigTimeoutMsg" BU_SG_REL_ EBCM_PCE SG_ 346 SecAutoBrkSysDrInfcStat 346;
BA_REL_ "GenSigTimeoutTime" BU_SG_REL_ EBCM_PCE SG_ 346 SecAutoBrkSysDrInfcStat 25;
BA_REL_ "GenSigRxStartValue" BU_SG_REL_ ADIMa_PCE SG_ 346 SecAutoBrkSysDrInfcStat "0";
BA_REL_ "GenSigSuprvResp" BU_SG_REL_ ADIMa_PCE SG_ 346 SecAutoBrkSysDrInfcStat 1;
BA_REL_ "GenSigTimeoutMsg" BU_SG_REL_ ADIMa_PCE SG_ 346 SecAutoBrkSysDrInfcStat 346;
BA_REL_ "GenSigTimeoutTime" BU_SG_REL_ ADIMa_PCE SG_ 346 SecAutoBrkSysDrInfcStat 10;
BA_REL_ "GenSigRxStartValue" BU_SG_REL_ ADIMa_PCE SG_ 346 SecAutoEstBrkTrqApd "0";
BA_REL_ "GenSigSuprvResp" BU_SG_REL_ ADIMa_PCE SG_ 346 SecAutoEstBrkTrqApd 1;
BA_REL_ "GenSigTimeoutMsg" BU_SG_REL_ ADIMa_PCE SG_ 346 SecAutoEstBrkTrqApd 346;
BA_REL_ "GenSigTimeoutTime" BU_SG_REL_ ADIMa_PCE SG_ 346 SecAutoEstBrkTrqApd 10;
BA_REL_ "GenSigRxStartValue" BU_SG_REL_ ADIMa_PCE SG_ 346 SecAutoArbBrkTrqReq "0";
BA_REL_ "GenSigSuprvResp" BU_SG_REL_ ADIMa_PCE SG_ 346 SecAutoArbBrkTrqReq 1;
BA_REL_ "GenSigTimeoutMsg" BU_SG_REL_ ADIMa_PCE SG_ 346 SecAutoArbBrkTrqReq 346;
BA_REL_ "GenSigTimeoutTime" BU_SG_REL_ ADIMa_PCE SG_ 346 SecAutoArbBrkTrqReq 10;
BA_REL_ "GenSigSuprvResp" BU_SG_REL_ ADIMa_PCE SG_ 344 CSS_CoPilotCibAvail 1;
BA_REL_ "GenSigTimeoutMsg" BU_SG_REL_ ADIMa_PCE SG_ 344 CSS_CoPilotCibAvail 344;
BA_REL_ "GenSigTimeoutTime" BU_SG_REL_ ADIMa_PCE SG_ 344 CSS_CoPilotCibAvail 25;
BA_REL_ "GenSigSuprvResp" BU_SG_REL_ ADIMa_PCE SG_ 344 CSS_CoPilotSysFltStat 1;
BA_REL_ "GenSigTimeoutMsg" BU_SG_REL_ ADIMa_PCE SG_ 344 CSS_CoPilotSysFltStat 344;
BA_REL_ "GenSigTimeoutTime" BU_SG_REL_ ADIMa_PCE SG_ 344 CSS_CoPilotSysFltStat 25;
BA_REL_ "GenSigSuprvResp" BU_SG_REL_ ADIMa_PCE SG_ 344 CSS_CoPilotRvbAvail 1;
BA_REL_ "GenSigTimeoutMsg" BU_SG_REL_ ADIMa_PCE SG_ 344 CSS_CoPilotRvbAvail 344;
BA_REL_ "GenSigTimeoutTime" BU_SG_REL_ ADIMa_PCE SG_ 344 CSS_CoPilotRvbAvail 25;
BA_REL_ "GenSigSuprvResp" BU_SG_REL_ ADIMa_PCE SG_ 344 CSS_CoPilotPcmAvail 1;
BA_REL_ "GenSigTimeoutMsg" BU_SG_REL_ ADIMa_PCE SG_ 344 CSS_CoPilotPcmAvail 344;
BA_REL_ "GenSigTimeoutTime" BU_SG_REL_ ADIMa_PCE SG_ 344 CSS_CoPilotPcmAvail 25;
BA_REL_ "GenSigSuprvResp" BU_SG_REL_ ADIMa_PCE SG_ 344 CSS_CoPilotFcaAvail 1;
BA_REL_ "GenSigTimeoutMsg" BU_SG_REL_ ADIMa_PCE SG_ 344 CSS_CoPilotFcaAvail 344;
BA_REL_ "GenSigTimeoutTime" BU_SG_REL_ ADIMa_PCE SG_ 344 CSS_CoPilotFcaAvail 25;
BA_REL_ "GenSigSuprvResp" BU_SG_REL_ ADIMa_PCE SG_ 344 CSS_CoPilotBrkExpctd 1;
BA_REL_ "GenSigTimeoutMsg" BU_SG_REL_ ADIMa_PCE SG_ 344 CSS_CoPilotBrkExpctd 344;
BA_REL_ "GenSigTimeoutTime" BU_SG_REL_ ADIMa_PCE SG_ 344 CSS_CoPilotBrkExpctd 25;
BA_REL_ "GenSigRxStartValue" BU_SG_REL_ ADIMa_PCE SG_ 344 CoPilotSysStatInfoChcksm "0";
BA_REL_ "GenSigRxStartValue" BU_SG_REL_ ADIMa_PCE SG_ 344 CoPilotSysStatInfoARC "0";
BA_REL_ "GenSigSuprvResp" BU_SG_REL_ ADIMa_PCE SG_ 344 StrgAngTrqBsdEstSrfcMuConf 1;
BA_REL_ "GenSigTimeoutMsg" BU_SG_REL_ ADIMa_PCE SG_ 344 StrgAngTrqBsdEstSrfcMuConf 344;
BA_REL_ "GenSigTimeoutTime" BU_SG_REL_ ADIMa_PCE SG_ 344 StrgAngTrqBsdEstSrfcMuConf 25;
BA_REL_ "GenSigSuprvResp" BU_SG_REL_ ADIMa_PCE SG_ 344 StrgAngTrqBsdEstSrfcMuCapV 1;
BA_REL_ "GenSigTimeoutMsg" BU_SG_REL_ ADIMa_PCE SG_ 344 StrgAngTrqBsdEstSrfcMuCapV 344;
BA_REL_ "GenSigTimeoutTime" BU_SG_REL_ ADIMa_PCE SG_ 344 StrgAngTrqBsdEstSrfcMuCapV 25;
BA_REL_ "GenSigSuprvResp" BU_SG_REL_ ADIMa_PCE SG_ 344 StrgAngTrqBsdEstSrfcMuCap 1;
BA_REL_ "GenSigTimeoutMsg" BU_SG_REL_ ADIMa_PCE SG_ 344 StrgAngTrqBsdEstSrfcMuCap 344;
BA_REL_ "GenSigTimeoutTime" BU_SG_REL_ ADIMa_PCE SG_ 344 StrgAngTrqBsdEstSrfcMuCap 25;
BA_REL_ "GenSigSuprvResp" BU_SG_REL_ ADIMa_PCE SG_ 344 LatVlctyBsdSrfcMuCap 1;
BA_REL_ "GenSigTimeoutMsg" BU_SG_REL_ ADIMa_PCE SG_ 344 LatVlctyBsdSrfcMuCap 344;
BA_REL_ "GenSigTimeoutTime" BU_SG_REL_ ADIMa_PCE SG_ 344 LatVlctyBsdSrfcMuCap 25;
BA_REL_ "GenSigRxStartValue" BU_SG_REL_ ADIMa_PCE SG_ 531 SecDynCtrlStatChksm "0";
BA_REL_ "GenSigRxStartValue" BU_SG_REL_ ADIMa_PCE SG_ 531 SecDynCtrlStatARC "0";
BA_REL_ "GenSigRxStartValue" BU_SG_REL_ ADIMa_PCE SG_ 531 Blkpdldet "False";
BA_REL_ "GenSigSuprvResp" BU_SG_REL_ ADIMa_PCE SG_ 531 Blkpdldet 1;
BA_REL_ "GenSigTimeoutMsg" BU_SG_REL_ ADIMa_PCE SG_ 531 Blkpdldet 531;
BA_REL_ "GenSigTimeoutTime" BU_SG_REL_ ADIMa_PCE SG_ 531 Blkpdldet 50;
BA_REL_ "GenSigSuprvResp" BU_SG_REL_ EBCM_PCE SG_ 531 Blkpdldet 1;
BA_REL_ "GenSigTimeoutMsg" BU_SG_REL_ EBCM_PCE SG_ 531 Blkpdldet 531;
BA_REL_ "GenSigTimeoutTime" BU_SG_REL_ EBCM_PCE SG_ 531 Blkpdldet 250;
BA_REL_ "GenSigRxStartValue" BU_SG_REL_ ADIMa_PCE SG_ 531 SecGrsHydCmpDtctd "False";
BA_REL_ "GenSigSuprvResp" BU_SG_REL_ ADIMa_PCE SG_ 531 SecGrsHydCmpDtctd 1;
BA_REL_ "GenSigTimeoutMsg" BU_SG_REL_ ADIMa_PCE SG_ 531 SecGrsHydCmpDtctd 531;
BA_REL_ "GenSigTimeoutTime" BU_SG_REL_ ADIMa_PCE SG_ 531 SecGrsHydCmpDtctd 50;
BA_REL_ "GenSigRxStartValue" BU_SG_REL_ ADIMa_PCE SG_ 531 SecGrsHydLkDtctd "False";
BA_REL_ "GenSigSuprvResp" BU_SG_REL_ ADIMa_PCE SG_ 531 SecGrsHydLkDtctd 1;
BA_REL_ "GenSigTimeoutMsg" BU_SG_REL_ ADIMa_PCE SG_ 531 SecGrsHydLkDtctd 531;
BA_REL_ "GenSigTimeoutTime" BU_SG_REL_ ADIMa_PCE SG_ 531 SecGrsHydLkDtctd 50;
BA_REL_ "GenSigRxStartValue" BU_SG_REL_ ADIMa_PCE SG_ 531 SecLatStabSysStat "Unknown";
BA_REL_ "GenSigSuprvResp" BU_SG_REL_ ADIMa_PCE SG_ 531 SecLatStabSysStat 1;
BA_REL_ "GenSigTimeoutMsg" BU_SG_REL_ ADIMa_PCE SG_ 531 SecLatStabSysStat 531;
BA_REL_ "GenSigTimeoutTime" BU_SG_REL_ ADIMa_PCE SG_ 531 SecLatStabSysStat 50;
BA_REL_ "GenSigRxStartValue" BU_SG_REL_ ADIMa_PCE SG_ 531 SecLongStabSysStat "Unknown";
BA_REL_ "GenSigSuprvResp" BU_SG_REL_ ADIMa_PCE SG_ 531 SecLongStabSysStat 1;
BA_REL_ "GenSigTimeoutMsg" BU_SG_REL_ ADIMa_PCE SG_ 531 SecLongStabSysStat 531;
BA_REL_ "GenSigTimeoutTime" BU_SG_REL_ ADIMa_PCE SG_ 531 SecLongStabSysStat 50;
BA_REL_ "GenSigRxStartValue" BU_SG_REL_ ADIMa_PCE SG_ 235 AutoCoPAxlTrqCmnd2PVal "0";
BA_REL_ "GenSigRxStartValue" BU_SG_REL_ ADIMa_PCE SG_ 235 ACATC2_AutoCoPCntrlAct "0";
BA_REL_ "GenSigSuprvResp" BU_SG_REL_ ADIMa_PCE SG_ 235 ACATC2_AutoCoPCntrlAct 1;
BA_REL_ "GenSigTimeoutMsg" BU_SG_REL_ ADIMa_PCE SG_ 235 ACATC2_AutoCoPCntrlAct 235;
BA_REL_ "GenSigTimeoutTime" BU_SG_REL_ ADIMa_PCE SG_ 235 ACATC2_AutoCoPCntrlAct 25;
BA_REL_ "GenSigRxStartValue" BU_SG_REL_ ADIMa_PCE SG_ 235 ACATC2_CoPAxlTrqReq "0";
BA_REL_ "GenSigSuprvResp" BU_SG_REL_ ADIMa_PCE SG_ 235 ACATC2_CoPAxlTrqReq 1;
BA_REL_ "GenSigTimeoutMsg" BU_SG_REL_ ADIMa_PCE SG_ 235 ACATC2_CoPAxlTrqReq 235;
BA_REL_ "GenSigTimeoutTime" BU_SG_REL_ ADIMa_PCE SG_ 235 ACATC2_CoPAxlTrqReq 25;
BA_REL_ "GenSigRxStartValue" BU_SG_REL_ ADIMa_PCE SG_ 235 AutoCoPAxlTrqCmnd2ARC "0";
BA_REL_ "GenSigRxStartValue" BU_SG_REL_ CMMb_PCE SG_ 342 StgCmndTgtAng "0";
BA_REL_ "GenSigSuprvResp" BU_SG_REL_ CMMb_PCE SG_ 342 StgCmndTgtAng 1;
BA_REL_ "GenSigTimeoutMsg" BU_SG_REL_ CMMb_PCE SG_ 342 StgCmndTgtAng 342;
BA_REL_ "GenSigTimeoutTime" BU_SG_REL_ CMMb_PCE SG_ 342 StgCmndTgtAng 30;
BA_REL_ "GenSigRxStartValue" BU_SG_REL_ CMMa_PCE SG_ 342 StgCmndTgtAng "0";
BA_REL_ "GenSigSuprvResp" BU_SG_REL_ CMMa_PCE SG_ 342 StgCmndTgtAng 1;
BA_REL_ "GenSigTimeoutMsg" BU_SG_REL_ CMMa_PCE SG_ 342 StgCmndTgtAng 342;
BA_REL_ "GenSigTimeoutTime" BU_SG_REL_ CMMa_PCE SG_ 342 StgCmndTgtAng 30;
BA_REL_ "GenSigRxStartValue" BU_SG_REL_ EOCM2cp_K2_PCE SG_ 342 StgCmndTgtAng "0";
BA_REL_ "GenSigSuprvResp" BU_SG_REL_ EOCM2cp_K2_PCE SG_ 342 StgCmndTgtAng 1;
BA_REL_ "GenSigTimeoutMsg" BU_SG_REL_ EOCM2cp_K2_PCE SG_ 342 StgCmndTgtAng 342;
BA_REL_ "GenSigTimeoutTime" BU_SG_REL_ EOCM2cp_K2_PCE SG_ 342 StgCmndTgtAng 25;
BA_REL_ "GenSigRxStartValue" BU_SG_REL_ ADIMa_PCE SG_ 342 StgCmndTgtAng "0";
BA_REL_ "GenSigSuprvResp" BU_SG_REL_ ADIMa_PCE SG_ 342 StgCmndTgtAng 1;
BA_REL_ "GenSigTimeoutMsg" BU_SG_REL_ ADIMa_PCE SG_ 342 StgCmndTgtAng 342;
BA_REL_ "GenSigTimeoutTime" BU_SG_REL_ ADIMa_PCE SG_ 342 StgCmndTgtAng 25;
BA_REL_ "GenSigRxStartValue" BU_SG_REL_ CMMb_PCE SG_ 342 StrgCmndMsgStatV "Valid";
BA_REL_ "GenSigRxStartValue" BU_SG_REL_ CMMa_PCE SG_ 342 StrgCmndMsgStatV "Valid";
BA_REL_ "GenSigRxStartValue" BU_SG_REL_ EOCM2cp_K2_PCE SG_ 342 StrgCmndMsgStatV "Valid";
BA_REL_ "GenSigSuprvResp" BU_SG_REL_ EOCM2cp_K2_PCE SG_ 342 StrgCmndMsgStatV 1;
BA_REL_ "GenSigTimeoutMsg" BU_SG_REL_ EOCM2cp_K2_PCE SG_ 342 StrgCmndMsgStatV 342;
BA_REL_ "GenSigTimeoutTime" BU_SG_REL_ EOCM2cp_K2_PCE SG_ 342 StrgCmndMsgStatV 25;
BA_REL_ "GenSigRxStartValue" BU_SG_REL_ ADIMa_PCE SG_ 342 StrgCmndMsgStatV "Valid";
BA_REL_ "GenSigSuprvResp" BU_SG_REL_ ADIMa_PCE SG_ 342 StrgCmndMsgStatV 1;
BA_REL_ "GenSigTimeoutMsg" BU_SG_REL_ ADIMa_PCE SG_ 342 StrgCmndMsgStatV 342;
BA_REL_ "GenSigTimeoutTime" BU_SG_REL_ ADIMa_PCE SG_ 342 StrgCmndMsgStatV 25;
BA_REL_ "GenSigVBitResp" BU_SG_REL_ CMMb_PCE SG_ 342 StrgCmndMsgStat 1;
BA_REL_ "GenSigRxStartValue" BU_SG_REL_ CMMb_PCE SG_ 342 StrgCmndMsgStat "Communication Normal";
BA_REL_ "GenSigSuprvResp" BU_SG_REL_ CMMb_PCE SG_ 342 StrgCmndMsgStat 1;
BA_REL_ "GenSigTimeoutMsg" BU_SG_REL_ CMMb_PCE SG_ 342 StrgCmndMsgStat 342;
BA_REL_ "GenSigTimeoutTime" BU_SG_REL_ CMMb_PCE SG_ 342 StrgCmndMsgStat 30;
BA_REL_ "GenSigVBitResp" BU_SG_REL_ CMMa_PCE SG_ 342 StrgCmndMsgStat 1;
BA_REL_ "GenSigRxStartValue" BU_SG_REL_ CMMa_PCE SG_ 342 StrgCmndMsgStat "Communication Normal";
BA_REL_ "GenSigSuprvResp" BU_SG_REL_ CMMa_PCE SG_ 342 StrgCmndMsgStat 1;
BA_REL_ "GenSigTimeoutMsg" BU_SG_REL_ CMMa_PCE SG_ 342 StrgCmndMsgStat 342;
BA_REL_ "GenSigTimeoutTime" BU_SG_REL_ CMMa_PCE SG_ 342 StrgCmndMsgStat 30;
BA_REL_ "GenSigVBitResp" BU_SG_REL_ EOCM2cp_K2_PCE SG_ 342 StrgCmndMsgStat 1;
BA_REL_ "GenSigRxStartValue" BU_SG_REL_ EOCM2cp_K2_PCE SG_ 342 StrgCmndMsgStat "0";
BA_REL_ "GenSigSuprvResp" BU_SG_REL_ EOCM2cp_K2_PCE SG_ 342 StrgCmndMsgStat 1;
BA_REL_ "GenSigTimeoutMsg" BU_SG_REL_ EOCM2cp_K2_PCE SG_ 342 StrgCmndMsgStat 342;
BA_REL_ "GenSigTimeoutTime" BU_SG_REL_ EOCM2cp_K2_PCE SG_ 342 StrgCmndMsgStat 25;
BA_REL_ "GenSigVBitResp" BU_SG_REL_ ADIMa_PCE SG_ 342 StrgCmndMsgStat 1;
BA_REL_ "GenSigRxStartValue" BU_SG_REL_ ADIMa_PCE SG_ 342 StrgCmndMsgStat "0";
BA_REL_ "GenSigSuprvResp" BU_SG_REL_ ADIMa_PCE SG_ 342 StrgCmndMsgStat 1;
BA_REL_ "GenSigTimeoutMsg" BU_SG_REL_ ADIMa_PCE SG_ 342 StrgCmndMsgStat 342;
BA_REL_ "GenSigTimeoutTime" BU_SG_REL_ ADIMa_PCE SG_ 342 StrgCmndMsgStat 25;
BA_REL_ "GenSigRxStartValue" BU_SG_REL_ CMMb_PCE SG_ 342 StrgCmndMsgUtlzdV "Valid";
BA_REL_ "GenSigRxStartValue" BU_SG_REL_ CMMa_PCE SG_ 342 StrgCmndMsgUtlzdV "Valid";
BA_REL_ "GenSigRxStartValue" BU_SG_REL_ EOCM2cp_K2_PCE SG_ 342 StrgCmndMsgUtlzdV "Valid";
BA_REL_ "GenSigSuprvResp" BU_SG_REL_ EOCM2cp_K2_PCE SG_ 342 StrgCmndMsgUtlzdV 1;
BA_REL_ "GenSigTimeoutMsg" BU_SG_REL_ EOCM2cp_K2_PCE SG_ 342 StrgCmndMsgUtlzdV 342;
BA_REL_ "GenSigTimeoutTime" BU_SG_REL_ EOCM2cp_K2_PCE SG_ 342 StrgCmndMsgUtlzdV 25;
BA_REL_ "GenSigRxStartValue" BU_SG_REL_ ADIMa_PCE SG_ 342 StrgCmndMsgUtlzdV "Valid";
BA_REL_ "GenSigSuprvResp" BU_SG_REL_ ADIMa_PCE SG_ 342 StrgCmndMsgUtlzdV 1;
BA_REL_ "GenSigTimeoutMsg" BU_SG_REL_ ADIMa_PCE SG_ 342 StrgCmndMsgUtlzdV 342;
BA_REL_ "GenSigTimeoutTime" BU_SG_REL_ ADIMa_PCE SG_ 342 StrgCmndMsgUtlzdV 25;
BA_REL_ "GenSigVBitResp" BU_SG_REL_ CMMb_PCE SG_ 342 StrgCmndMsgUtlzd 1;
BA_REL_ "GenSigRxStartValue" BU_SG_REL_ CMMb_PCE SG_ 342 StrgCmndMsgUtlzd "Primary Controller";
BA_REL_ "GenSigSuprvResp" BU_SG_REL_ CMMb_PCE SG_ 342 StrgCmndMsgUtlzd 1;
BA_REL_ "GenSigTimeoutMsg" BU_SG_REL_ CMMb_PCE SG_ 342 StrgCmndMsgUtlzd 342;
BA_REL_ "GenSigTimeoutTime" BU_SG_REL_ CMMb_PCE SG_ 342 StrgCmndMsgUtlzd 30;
BA_REL_ "GenSigVBitResp" BU_SG_REL_ CMMa_PCE SG_ 342 StrgCmndMsgUtlzd 1;
BA_REL_ "GenSigRxStartValue" BU_SG_REL_ CMMa_PCE SG_ 342 StrgCmndMsgUtlzd "Primary Controller";
BA_REL_ "GenSigSuprvResp" BU_SG_REL_ CMMa_PCE SG_ 342 StrgCmndMsgUtlzd 1;
BA_REL_ "GenSigTimeoutMsg" BU_SG_REL_ CMMa_PCE SG_ 342 StrgCmndMsgUtlzd 342;
BA_REL_ "GenSigTimeoutTime" BU_SG_REL_ CMMa_PCE SG_ 342 StrgCmndMsgUtlzd 30;
BA_REL_ "GenSigVBitResp" BU_SG_REL_ EOCM2cp_K2_PCE SG_ 342 StrgCmndMsgUtlzd 1;
BA_REL_ "GenSigRxStartValue" BU_SG_REL_ EOCM2cp_K2_PCE SG_ 342 StrgCmndMsgUtlzd "0";
BA_REL_ "GenSigSuprvResp" BU_SG_REL_ EOCM2cp_K2_PCE SG_ 342 StrgCmndMsgUtlzd 1;
BA_REL_ "GenSigTimeoutMsg" BU_SG_REL_ EOCM2cp_K2_PCE SG_ 342 StrgCmndMsgUtlzd 342;
BA_REL_ "GenSigTimeoutTime" BU_SG_REL_ EOCM2cp_K2_PCE SG_ 342 StrgCmndMsgUtlzd 25;
BA_REL_ "GenSigVBitResp" BU_SG_REL_ ADIMa_PCE SG_ 342 StrgCmndMsgUtlzd 1;
BA_REL_ "GenSigRxStartValue" BU_SG_REL_ ADIMa_PCE SG_ 342 StrgCmndMsgUtlzd "0";
BA_REL_ "GenSigSuprvResp" BU_SG_REL_ ADIMa_PCE SG_ 342 StrgCmndMsgUtlzd 1;
BA_REL_ "GenSigTimeoutMsg" BU_SG_REL_ ADIMa_PCE SG_ 342 StrgCmndMsgUtlzd 342;
BA_REL_ "GenSigTimeoutTime" BU_SG_REL_ ADIMa_PCE SG_ 342 StrgCmndMsgUtlzd 25;
BA_REL_ "GenSigRxStartValue" BU_SG_REL_ CMMb_PCE SG_ 342 AutoStrgCmndStatV "Valid";
BA_REL_ "GenSigRxStartValue" BU_SG_REL_ CMMa_PCE SG_ 342 AutoStrgCmndStatV "Valid";
BA_REL_ "GenSigRxStartValue" BU_SG_REL_ EOCM2cp_K2_PCE SG_ 342 AutoStrgCmndStatV "Valid";
BA_REL_ "GenSigSuprvResp" BU_SG_REL_ EOCM2cp_K2_PCE SG_ 342 AutoStrgCmndStatV 1;
BA_REL_ "GenSigTimeoutMsg" BU_SG_REL_ EOCM2cp_K2_PCE SG_ 342 AutoStrgCmndStatV 342;
BA_REL_ "GenSigTimeoutTime" BU_SG_REL_ EOCM2cp_K2_PCE SG_ 342 AutoStrgCmndStatV 25;
BA_REL_ "GenSigRxStartValue" BU_SG_REL_ ADIMa_PCE SG_ 342 AutoStrgCmndStatV "Valid";
BA_REL_ "GenSigSuprvResp" BU_SG_REL_ ADIMa_PCE SG_ 342 AutoStrgCmndStatV 1;
BA_REL_ "GenSigTimeoutMsg" BU_SG_REL_ ADIMa_PCE SG_ 342 AutoStrgCmndStatV 342;
BA_REL_ "GenSigTimeoutTime" BU_SG_REL_ ADIMa_PCE SG_ 342 AutoStrgCmndStatV 25;
BA_REL_ "GenSigRxStartValue" BU_SG_REL_ CMMb_PCE SG_ 342 StgTtlEffTrqDlvd "0";
BA_REL_ "GenSigSuprvResp" BU_SG_REL_ CMMb_PCE SG_ 342 StgTtlEffTrqDlvd 1;
BA_REL_ "GenSigTimeoutMsg" BU_SG_REL_ CMMb_PCE SG_ 342 StgTtlEffTrqDlvd 342;
BA_REL_ "GenSigTimeoutTime" BU_SG_REL_ CMMb_PCE SG_ 342 StgTtlEffTrqDlvd 30;
BA_REL_ "GenSigRxStartValue" BU_SG_REL_ CMMa_PCE SG_ 342 StgTtlEffTrqDlvd "0";
BA_REL_ "GenSigSuprvResp" BU_SG_REL_ CMMa_PCE SG_ 342 StgTtlEffTrqDlvd 1;
BA_REL_ "GenSigTimeoutMsg" BU_SG_REL_ CMMa_PCE SG_ 342 StgTtlEffTrqDlvd 342;
BA_REL_ "GenSigTimeoutTime" BU_SG_REL_ CMMa_PCE SG_ 342 StgTtlEffTrqDlvd 30;
BA_REL_ "GenSigRxStartValue" BU_SG_REL_ EOCM2cp_K2_PCE SG_ 342 StgTtlEffTrqDlvd "0";
BA_REL_ "GenSigSuprvResp" BU_SG_REL_ EOCM2cp_K2_PCE SG_ 342 StgTtlEffTrqDlvd 1;
BA_REL_ "GenSigTimeoutMsg" BU_SG_REL_ EOCM2cp_K2_PCE SG_ 342 StgTtlEffTrqDlvd 342;
BA_REL_ "GenSigTimeoutTime" BU_SG_REL_ EOCM2cp_K2_PCE SG_ 342 StgTtlEffTrqDlvd 25;
BA_REL_ "GenSigRxStartValue" BU_SG_REL_ ADIMa_PCE SG_ 342 StgTtlEffTrqDlvd "0";
BA_REL_ "GenSigSuprvResp" BU_SG_REL_ ADIMa_PCE SG_ 342 StgTtlEffTrqDlvd 1;
BA_REL_ "GenSigTimeoutMsg" BU_SG_REL_ ADIMa_PCE SG_ 342 StgTtlEffTrqDlvd 342;
BA_REL_ "GenSigTimeoutTime" BU_SG_REL_ ADIMa_PCE SG_ 342 StgTtlEffTrqDlvd 25;
BA_REL_ "GenSigRxStartValue" BU_SG_REL_ EBOOST_OBD_PCE SG_ 342 StgTtlEffTrqDlvd "0";
BA_REL_ "GenSigSuprvResp" BU_SG_REL_ EBOOST_OBD_PCE SG_ 342 StgTtlEffTrqDlvd 1;
BA_REL_ "GenSigTimeoutMsg" BU_SG_REL_ EBOOST_OBD_PCE SG_ 342 StgTtlEffTrqDlvd 342;
BA_REL_ "GenSigTimeoutTime" BU_SG_REL_ EBOOST_OBD_PCE SG_ 342 StgTtlEffTrqDlvd 25;
BA_REL_ "GenSigRxStartValue" BU_SG_REL_ EBCM_PCE SG_ 342 StgTtlEffTrqDlvd "0";
BA_REL_ "GenSigSuprvResp" BU_SG_REL_ EBCM_PCE SG_ 342 StgTtlEffTrqDlvd 1;
BA_REL_ "GenSigTimeoutMsg" BU_SG_REL_ EBCM_PCE SG_ 342 StgTtlEffTrqDlvd 342;
BA_REL_ "GenSigTimeoutTime" BU_SG_REL_ EBCM_PCE SG_ 342 StgTtlEffTrqDlvd 25;
BA_REL_ "GenSigRxStartValue" BU_SG_REL_ CMMb_PCE SG_ 342 StgTrqSnsrVStat "Valid";
BA_REL_ "GenSigRxStartValue" BU_SG_REL_ CMMa_PCE SG_ 342 StgTrqSnsrVStat "Valid";
BA_REL_ "GenSigRxStartValue" BU_SG_REL_ EOCM2cp_K2_PCE SG_ 342 StgTrqSnsrVStat "Valid";
BA_REL_ "GenSigSuprvResp" BU_SG_REL_ EOCM2cp_K2_PCE SG_ 342 StgTrqSnsrVStat 1;
BA_REL_ "GenSigTimeoutMsg" BU_SG_REL_ EOCM2cp_K2_PCE SG_ 342 StgTrqSnsrVStat 342;
BA_REL_ "GenSigTimeoutTime" BU_SG_REL_ EOCM2cp_K2_PCE SG_ 342 StgTrqSnsrVStat 25;
BA_REL_ "GenSigRxStartValue" BU_SG_REL_ ADIMa_PCE SG_ 342 StgTrqSnsrVStat "Valid";
BA_REL_ "GenSigSuprvResp" BU_SG_REL_ ADIMa_PCE SG_ 342 StgTrqSnsrVStat 1;
BA_REL_ "GenSigTimeoutMsg" BU_SG_REL_ ADIMa_PCE SG_ 342 StgTrqSnsrVStat 342;
BA_REL_ "GenSigTimeoutTime" BU_SG_REL_ ADIMa_PCE SG_ 342 StgTrqSnsrVStat 25;
BA_REL_ "GenSigRxStartValue" BU_SG_REL_ EBOOST_OBD_PCE SG_ 342 StgTrqSnsrVStat "Valid";
BA_REL_ "GenSigSuprvResp" BU_SG_REL_ EBOOST_OBD_PCE SG_ 342 StgTrqSnsrVStat 1;
BA_REL_ "GenSigTimeoutMsg" BU_SG_REL_ EBOOST_OBD_PCE SG_ 342 StgTrqSnsrVStat 342;
BA_REL_ "GenSigTimeoutTime" BU_SG_REL_ EBOOST_OBD_PCE SG_ 342 StgTrqSnsrVStat 25;
BA_REL_ "GenSigRxStartValue" BU_SG_REL_ EBCM_PCE SG_ 342 StgTrqSnsrVStat "Valid";
BA_REL_ "GenSigSuprvResp" BU_SG_REL_ EBCM_PCE SG_ 342 StgTrqSnsrVStat 1;
BA_REL_ "GenSigTimeoutMsg" BU_SG_REL_ EBCM_PCE SG_ 342 StgTrqSnsrVStat 342;
BA_REL_ "GenSigTimeoutTime" BU_SG_REL_ EBCM_PCE SG_ 342 StgTrqSnsrVStat 25;
BA_REL_ "GenSigRxStartValue" BU_SG_REL_ CMMb_PCE SG_ 342 StgSysOtptStatV "Valid";
BA_REL_ "GenSigRxStartValue" BU_SG_REL_ CMMa_PCE SG_ 342 StgSysOtptStatV "Valid";
BA_REL_ "GenSigRxStartValue" BU_SG_REL_ EOCM2cp_K2_PCE SG_ 342 StgSysOtptStatV "Valid";
BA_REL_ "GenSigSuprvResp" BU_SG_REL_ EOCM2cp_K2_PCE SG_ 342 StgSysOtptStatV 1;
BA_REL_ "GenSigTimeoutMsg" BU_SG_REL_ EOCM2cp_K2_PCE SG_ 342 StgSysOtptStatV 342;
BA_REL_ "GenSigTimeoutTime" BU_SG_REL_ EOCM2cp_K2_PCE SG_ 342 StgSysOtptStatV 25;
BA_REL_ "GenSigRxStartValue" BU_SG_REL_ ADIMa_PCE SG_ 342 StgSysOtptStatV "Valid";
BA_REL_ "GenSigSuprvResp" BU_SG_REL_ ADIMa_PCE SG_ 342 StgSysOtptStatV 1;
BA_REL_ "GenSigTimeoutMsg" BU_SG_REL_ ADIMa_PCE SG_ 342 StgSysOtptStatV 342;
BA_REL_ "GenSigTimeoutTime" BU_SG_REL_ ADIMa_PCE SG_ 342 StgSysOtptStatV 25;
BA_REL_ "GenSigVBitResp" BU_SG_REL_ CMMb_PCE SG_ 342 StgSysOtptStat 1;
BA_REL_ "GenSigRxStartValue" BU_SG_REL_ CMMb_PCE SG_ 342 StgSysOtptStat "Unknown";
BA_REL_ "GenSigSuprvResp" BU_SG_REL_ CMMb_PCE SG_ 342 StgSysOtptStat 1;
BA_REL_ "GenSigTimeoutMsg" BU_SG_REL_ CMMb_PCE SG_ 342 StgSysOtptStat 342;
BA_REL_ "GenSigTimeoutTime" BU_SG_REL_ CMMb_PCE SG_ 342 StgSysOtptStat 30;
BA_REL_ "GenSigVBitResp" BU_SG_REL_ CMMa_PCE SG_ 342 StgSysOtptStat 1;
BA_REL_ "GenSigRxStartValue" BU_SG_REL_ CMMa_PCE SG_ 342 StgSysOtptStat "Unknown";
BA_REL_ "GenSigSuprvResp" BU_SG_REL_ CMMa_PCE SG_ 342 StgSysOtptStat 1;
BA_REL_ "GenSigTimeoutMsg" BU_SG_REL_ CMMa_PCE SG_ 342 StgSysOtptStat 342;
BA_REL_ "GenSigTimeoutTime" BU_SG_REL_ CMMa_PCE SG_ 342 StgSysOtptStat 30;
BA_REL_ "GenSigVBitResp" BU_SG_REL_ EOCM2cp_K2_PCE SG_ 342 StgSysOtptStat 1;
BA_REL_ "GenSigRxStartValue" BU_SG_REL_ EOCM2cp_K2_PCE SG_ 342 StgSysOtptStat "0";
BA_REL_ "GenSigSuprvResp" BU_SG_REL_ EOCM2cp_K2_PCE SG_ 342 StgSysOtptStat 1;
BA_REL_ "GenSigTimeoutMsg" BU_SG_REL_ EOCM2cp_K2_PCE SG_ 342 StgSysOtptStat 342;
BA_REL_ "GenSigTimeoutTime" BU_SG_REL_ EOCM2cp_K2_PCE SG_ 342 StgSysOtptStat 25;
BA_REL_ "GenSigVBitResp" BU_SG_REL_ ADIMa_PCE SG_ 342 StgSysOtptStat 1;
BA_REL_ "GenSigRxStartValue" BU_SG_REL_ ADIMa_PCE SG_ 342 StgSysOtptStat "0";
BA_REL_ "GenSigSuprvResp" BU_SG_REL_ ADIMa_PCE SG_ 342 StgSysOtptStat 1;
BA_REL_ "GenSigTimeoutMsg" BU_SG_REL_ ADIMa_PCE SG_ 342 StgSysOtptStat 342;
BA_REL_ "GenSigTimeoutTime" BU_SG_REL_ ADIMa_PCE SG_ 342 StgSysOtptStat 25;
BA_REL_ "GenSigRxStartValue" BU_SG_REL_ CMMb_PCE SG_ 342 StgOtptTempLmtgSte "Unknown";
BA_REL_ "GenSigSuprvResp" BU_SG_REL_ CMMb_PCE SG_ 342 StgOtptTempLmtgSte 1;
BA_REL_ "GenSigTimeoutMsg" BU_SG_REL_ CMMb_PCE SG_ 342 StgOtptTempLmtgSte 342;
BA_REL_ "GenSigTimeoutTime" BU_SG_REL_ CMMb_PCE SG_ 342 StgOtptTempLmtgSte 30;
BA_REL_ "GenSigRxStartValue" BU_SG_REL_ CMMa_PCE SG_ 342 StgOtptTempLmtgSte "Unknown";
BA_REL_ "GenSigSuprvResp" BU_SG_REL_ CMMa_PCE SG_ 342 StgOtptTempLmtgSte 1;
BA_REL_ "GenSigTimeoutMsg" BU_SG_REL_ CMMa_PCE SG_ 342 StgOtptTempLmtgSte 342;
BA_REL_ "GenSigTimeoutTime" BU_SG_REL_ CMMa_PCE SG_ 342 StgOtptTempLmtgSte 30;
BA_REL_ "GenSigRxStartValue" BU_SG_REL_ EOCM2cp_K2_PCE SG_ 342 StgOtptTempLmtgSte "0";
BA_REL_ "GenSigSuprvResp" BU_SG_REL_ EOCM2cp_K2_PCE SG_ 342 StgOtptTempLmtgSte 1;
BA_REL_ "GenSigTimeoutMsg" BU_SG_REL_ EOCM2cp_K2_PCE SG_ 342 StgOtptTempLmtgSte 342;
BA_REL_ "GenSigTimeoutTime" BU_SG_REL_ EOCM2cp_K2_PCE SG_ 342 StgOtptTempLmtgSte 25;
BA_REL_ "GenSigRxStartValue" BU_SG_REL_ ADIMa_PCE SG_ 342 StgOtptTempLmtgSte "0";
BA_REL_ "GenSigSuprvResp" BU_SG_REL_ ADIMa_PCE SG_ 342 StgOtptTempLmtgSte 1;
BA_REL_ "GenSigTimeoutMsg" BU_SG_REL_ ADIMa_PCE SG_ 342 StgOtptTempLmtgSte 342;
BA_REL_ "GenSigTimeoutTime" BU_SG_REL_ ADIMa_PCE SG_ 342 StgOtptTempLmtgSte 25;
BA_REL_ "GenSigRxStartValue" BU_SG_REL_ CMMb_PCE SG_ 342 StgAngRtLmtV "Valid";
BA_REL_ "GenSigRxStartValue" BU_SG_REL_ CMMa_PCE SG_ 342 StgAngRtLmtV "Valid";
BA_REL_ "GenSigRxStartValue" BU_SG_REL_ EOCM2cp_K2_PCE SG_ 342 StgAngRtLmtV "Valid";
BA_REL_ "GenSigSuprvResp" BU_SG_REL_ EOCM2cp_K2_PCE SG_ 342 StgAngRtLmtV 1;
BA_REL_ "GenSigTimeoutMsg" BU_SG_REL_ EOCM2cp_K2_PCE SG_ 342 StgAngRtLmtV 342;
BA_REL_ "GenSigTimeoutTime" BU_SG_REL_ EOCM2cp_K2_PCE SG_ 342 StgAngRtLmtV 25;
BA_REL_ "GenSigRxStartValue" BU_SG_REL_ ADIMa_PCE SG_ 342 StgAngRtLmtV "Valid";
BA_REL_ "GenSigSuprvResp" BU_SG_REL_ ADIMa_PCE SG_ 342 StgAngRtLmtV 1;
BA_REL_ "GenSigTimeoutMsg" BU_SG_REL_ ADIMa_PCE SG_ 342 StgAngRtLmtV 342;
BA_REL_ "GenSigTimeoutTime" BU_SG_REL_ ADIMa_PCE SG_ 342 StgAngRtLmtV 25;
BA_REL_ "GenSigVBitResp" BU_SG_REL_ CMMb_PCE SG_ 342 StgAngRtLmt 1;
BA_REL_ "GenSigRxStartValue" BU_SG_REL_ CMMb_PCE SG_ 342 StgAngRtLmt "0";
BA_REL_ "GenSigSuprvResp" BU_SG_REL_ CMMb_PCE SG_ 342 StgAngRtLmt 1;
BA_REL_ "GenSigTimeoutMsg" BU_SG_REL_ CMMb_PCE SG_ 342 StgAngRtLmt 342;
BA_REL_ "GenSigTimeoutTime" BU_SG_REL_ CMMb_PCE SG_ 342 StgAngRtLmt 30;
BA_REL_ "GenSigVBitResp" BU_SG_REL_ CMMa_PCE SG_ 342 StgAngRtLmt 1;
BA_REL_ "GenSigRxStartValue" BU_SG_REL_ CMMa_PCE SG_ 342 StgAngRtLmt "0";
BA_REL_ "GenSigSuprvResp" BU_SG_REL_ CMMa_PCE SG_ 342 StgAngRtLmt 1;
BA_REL_ "GenSigTimeoutMsg" BU_SG_REL_ CMMa_PCE SG_ 342 StgAngRtLmt 342;
BA_REL_ "GenSigTimeoutTime" BU_SG_REL_ CMMa_PCE SG_ 342 StgAngRtLmt 30;
BA_REL_ "GenSigVBitResp" BU_SG_REL_ EOCM2cp_K2_PCE SG_ 342 StgAngRtLmt 1;
BA_REL_ "GenSigRxStartValue" BU_SG_REL_ EOCM2cp_K2_PCE SG_ 342 StgAngRtLmt "0";
BA_REL_ "GenSigSuprvResp" BU_SG_REL_ EOCM2cp_K2_PCE SG_ 342 StgAngRtLmt 1;
BA_REL_ "GenSigTimeoutMsg" BU_SG_REL_ EOCM2cp_K2_PCE SG_ 342 StgAngRtLmt 342;
BA_REL_ "GenSigTimeoutTime" BU_SG_REL_ EOCM2cp_K2_PCE SG_ 342 StgAngRtLmt 25;
BA_REL_ "GenSigVBitResp" BU_SG_REL_ ADIMa_PCE SG_ 342 StgAngRtLmt 1;
BA_REL_ "GenSigRxStartValue" BU_SG_REL_ ADIMa_PCE SG_ 342 StgAngRtLmt "0";
BA_REL_ "GenSigSuprvResp" BU_SG_REL_ ADIMa_PCE SG_ 342 StgAngRtLmt 1;
BA_REL_ "GenSigTimeoutMsg" BU_SG_REL_ ADIMa_PCE SG_ 342 StgAngRtLmt 342;
BA_REL_ "GenSigTimeoutTime" BU_SG_REL_ ADIMa_PCE SG_ 342 StgAngRtLmt 25;
BA_REL_ "GenSigVBitResp" BU_SG_REL_ CMMb_PCE SG_ 342 AutoStrgCmndStat 1;
BA_REL_ "GenSigRxStartValue" BU_SG_REL_ CMMb_PCE SG_ 342 AutoStrgCmndStat "Unknown";
BA_REL_ "GenSigSuprvResp" BU_SG_REL_ CMMb_PCE SG_ 342 AutoStrgCmndStat 1;
BA_REL_ "GenSigTimeoutMsg" BU_SG_REL_ CMMb_PCE SG_ 342 AutoStrgCmndStat 342;
BA_REL_ "GenSigTimeoutTime" BU_SG_REL_ CMMb_PCE SG_ 342 AutoStrgCmndStat 30;
BA_REL_ "GenSigVBitResp" BU_SG_REL_ CMMa_PCE SG_ 342 AutoStrgCmndStat 1;
BA_REL_ "GenSigRxStartValue" BU_SG_REL_ CMMa_PCE SG_ 342 AutoStrgCmndStat "Unknown";
BA_REL_ "GenSigSuprvResp" BU_SG_REL_ CMMa_PCE SG_ 342 AutoStrgCmndStat 1;
BA_REL_ "GenSigTimeoutMsg" BU_SG_REL_ CMMa_PCE SG_ 342 AutoStrgCmndStat 342;
BA_REL_ "GenSigTimeoutTime" BU_SG_REL_ CMMa_PCE SG_ 342 AutoStrgCmndStat 30;
BA_REL_ "GenSigVBitResp" BU_SG_REL_ EOCM2cp_K2_PCE SG_ 342 AutoStrgCmndStat 1;
BA_REL_ "GenSigRxStartValue" BU_SG_REL_ EOCM2cp_K2_PCE SG_ 342 AutoStrgCmndStat "0";
BA_REL_ "GenSigSuprvResp" BU_SG_REL_ EOCM2cp_K2_PCE SG_ 342 AutoStrgCmndStat 1;
BA_REL_ "GenSigTimeoutMsg" BU_SG_REL_ EOCM2cp_K2_PCE SG_ 342 AutoStrgCmndStat 342;
BA_REL_ "GenSigTimeoutTime" BU_SG_REL_ EOCM2cp_K2_PCE SG_ 342 AutoStrgCmndStat 25;
BA_REL_ "GenSigVBitResp" BU_SG_REL_ ADIMa_PCE SG_ 342 AutoStrgCmndStat 1;
BA_REL_ "GenSigRxStartValue" BU_SG_REL_ ADIMa_PCE SG_ 342 AutoStrgCmndStat "0";
BA_REL_ "GenSigSuprvResp" BU_SG_REL_ ADIMa_PCE SG_ 342 AutoStrgCmndStat 1;
BA_REL_ "GenSigTimeoutMsg" BU_SG_REL_ ADIMa_PCE SG_ 342 AutoStrgCmndStat 342;
BA_REL_ "GenSigTimeoutTime" BU_SG_REL_ ADIMa_PCE SG_ 342 AutoStrgCmndStat 25;
BA_REL_ "GenSigRxStartValue" BU_SG_REL_ CMMb_PCE SG_ 342 AutoStgStatChksm "0";
BA_REL_ "GenSigRxStartValue" BU_SG_REL_ CMMa_PCE SG_ 342 AutoStgStatChksm "0";
BA_REL_ "GenSigRxStartValue" BU_SG_REL_ EOCM2cp_K2_PCE SG_ 342 AutoStgStatChksm "0";
BA_REL_ "GenSigRxStartValue" BU_SG_REL_ ADIMa_PCE SG_ 342 AutoStgStatChksm "0";
BA_REL_ "GenSigRxStartValue" BU_SG_REL_ CMMb_PCE SG_ 342 AutoStgStatARC "0";
BA_REL_ "GenSigRxStartValue" BU_SG_REL_ CMMa_PCE SG_ 342 AutoStgStatARC "0";
BA_REL_ "GenSigRxStartValue" BU_SG_REL_ EOCM2cp_K2_PCE SG_ 342 AutoStgStatARC "0";
BA_REL_ "GenSigRxStartValue" BU_SG_REL_ ADIMa_PCE SG_ 342 AutoStgStatARC "0";
BA_REL_ "GenSigRxStartValue" BU_SG_REL_ CMMb_PCE SG_ 342 StgOvrdDetn "Initialization";
BA_REL_ "GenSigSuprvResp" BU_SG_REL_ CMMb_PCE SG_ 342 StgOvrdDetn 1;
BA_REL_ "GenSigTimeoutMsg" BU_SG_REL_ CMMb_PCE SG_ 342 StgOvrdDetn 342;
BA_REL_ "GenSigTimeoutTime" BU_SG_REL_ CMMb_PCE SG_ 342 StgOvrdDetn 30;
BA_REL_ "GenSigRxStartValue" BU_SG_REL_ CMMa_PCE SG_ 342 StgOvrdDetn "Initialization";
BA_REL_ "GenSigSuprvResp" BU_SG_REL_ CMMa_PCE SG_ 342 StgOvrdDetn 1;
BA_REL_ "GenSigTimeoutMsg" BU_SG_REL_ CMMa_PCE SG_ 342 StgOvrdDetn 342;
BA_REL_ "GenSigTimeoutTime" BU_SG_REL_ CMMa_PCE SG_ 342 StgOvrdDetn 30;
BA_REL_ "GenSigRxStartValue" BU_SG_REL_ EOCM2cp_K2_PCE SG_ 342 StgOvrdDetn "Initialization";
BA_REL_ "GenSigSuprvResp" BU_SG_REL_ EOCM2cp_K2_PCE SG_ 342 StgOvrdDetn 1;
BA_REL_ "GenSigTimeoutMsg" BU_SG_REL_ EOCM2cp_K2_PCE SG_ 342 StgOvrdDetn 342;
BA_REL_ "GenSigTimeoutTime" BU_SG_REL_ EOCM2cp_K2_PCE SG_ 342 StgOvrdDetn 25;
BA_REL_ "GenSigRxStartValue" BU_SG_REL_ ADIMa_PCE SG_ 342 StgOvrdDetn "Initialization";
BA_REL_ "GenSigSuprvResp" BU_SG_REL_ ADIMa_PCE SG_ 342 StgOvrdDetn 1;
BA_REL_ "GenSigTimeoutMsg" BU_SG_REL_ ADIMa_PCE SG_ 342 StgOvrdDetn 342;
BA_REL_ "GenSigTimeoutTime" BU_SG_REL_ ADIMa_PCE SG_ 342 StgOvrdDetn 25;
BA_REL_ "GenSigRxStartValue" BU_SG_REL_ EBOOST_OBD_PCE SG_ 342 StgOvrdDetn "Initialization";
BA_REL_ "GenSigSuprvResp" BU_SG_REL_ EBOOST_OBD_PCE SG_ 342 StgOvrdDetn 1;
BA_REL_ "GenSigTimeoutMsg" BU_SG_REL_ EBOOST_OBD_PCE SG_ 342 StgOvrdDetn 342;
BA_REL_ "GenSigTimeoutTime" BU_SG_REL_ EBOOST_OBD_PCE SG_ 342 StgOvrdDetn 25;
BA_REL_ "GenSigRxStartValue" BU_SG_REL_ EBCM_PCE SG_ 342 StgOvrdDetn "Initialization";
BA_REL_ "GenSigSuprvResp" BU_SG_REL_ EBCM_PCE SG_ 342 StgOvrdDetn 1;
BA_REL_ "GenSigTimeoutMsg" BU_SG_REL_ EBCM_PCE SG_ 342 StgOvrdDetn 342;
BA_REL_ "GenSigTimeoutTime" BU_SG_REL_ EBCM_PCE SG_ 342 StgOvrdDetn 25;
BA_REL_ "GenSigRxStartValue" BU_SG_REL_ ADIMa_PCE SG_ 354 EstBrkRtrTempStat "Normal";
BA_REL_ "GenSigSuprvResp" BU_SG_REL_ ADIMa_PCE SG_ 354 EstBrkRtrTempStat 1;
BA_REL_ "GenSigTimeoutMsg" BU_SG_REL_ ADIMa_PCE SG_ 354 EstBrkRtrTempStat 354;
BA_REL_ "GenSigTimeoutTime" BU_SG_REL_ ADIMa_PCE SG_ 354 EstBrkRtrTempStat 50;
BA_REL_ "GenSigRxStartValue" BU_SG_REL_ ADIMa_PCE SG_ 354 PriDynCtrlStatChksm "0";
BA_REL_ "GenSigRxStartValue" BU_SG_REL_ ADIMa_PCE SG_ 354 PriDynCtrlStatARC "0";
BA_REL_ "GenSigRxStartValue" BU_SG_REL_ ADIMa_PCE SG_ 354 EstBrkRtrTempRR "2.857";
BA_REL_ "GenSigSuprvResp" BU_SG_REL_ ADIMa_PCE SG_ 354 EstBrkRtrTempRR 1;
BA_REL_ "GenSigTimeoutMsg" BU_SG_REL_ ADIMa_PCE SG_ 354 EstBrkRtrTempRR 354;
BA_REL_ "GenSigTimeoutTime" BU_SG_REL_ ADIMa_PCE SG_ 354 EstBrkRtrTempRR 50;
BA_REL_ "GenSigRxStartValue" BU_SG_REL_ ADIMa_PCE SG_ 354 EstBrkRtrTempRF "2.857";
BA_REL_ "GenSigSuprvResp" BU_SG_REL_ ADIMa_PCE SG_ 354 EstBrkRtrTempRF 1;
BA_REL_ "GenSigTimeoutMsg" BU_SG_REL_ ADIMa_PCE SG_ 354 EstBrkRtrTempRF 354;
BA_REL_ "GenSigTimeoutTime" BU_SG_REL_ ADIMa_PCE SG_ 354 EstBrkRtrTempRF 50;
BA_REL_ "GenSigRxStartValue" BU_SG_REL_ ADIMa_PCE SG_ 354 EstBrkRtrTempLR "2.857";
BA_REL_ "GenSigSuprvResp" BU_SG_REL_ ADIMa_PCE SG_ 354 EstBrkRtrTempLR 1;
BA_REL_ "GenSigTimeoutMsg" BU_SG_REL_ ADIMa_PCE SG_ 354 EstBrkRtrTempLR 354;
BA_REL_ "GenSigTimeoutTime" BU_SG_REL_ ADIMa_PCE SG_ 354 EstBrkRtrTempLR 50;
BA_REL_ "GenSigRxStartValue" BU_SG_REL_ ADIMa_PCE SG_ 354 EstBrkRtrTempLF "2.857";
BA_REL_ "GenSigSuprvResp" BU_SG_REL_ ADIMa_PCE SG_ 354 EstBrkRtrTempLF 1;
BA_REL_ "GenSigTimeoutMsg" BU_SG_REL_ ADIMa_PCE SG_ 354 EstBrkRtrTempLF 354;
BA_REL_ "GenSigTimeoutTime" BU_SG_REL_ ADIMa_PCE SG_ 354 EstBrkRtrTempLF 50;
BA_REL_ "GenSigRxStartValue" BU_SG_REL_ ADIMa_PCE SG_ 354 PriGrsBrkIneffDtctd "False";
BA_REL_ "GenSigSuprvResp" BU_SG_REL_ ADIMa_PCE SG_ 354 PriGrsBrkIneffDtctd 1;
BA_REL_ "GenSigTimeoutMsg" BU_SG_REL_ ADIMa_PCE SG_ 354 PriGrsBrkIneffDtctd 354;
BA_REL_ "GenSigTimeoutTime" BU_SG_REL_ ADIMa_PCE SG_ 354 PriGrsBrkIneffDtctd 50;
BA_REL_ "GenSigRxStartValue" BU_SG_REL_ ADIMa_PCE SG_ 354 PriGrsHydCmpDtctd "False";
BA_REL_ "GenSigSuprvResp" BU_SG_REL_ ADIMa_PCE SG_ 354 PriGrsHydCmpDtctd 1;
BA_REL_ "GenSigTimeoutMsg" BU_SG_REL_ ADIMa_PCE SG_ 354 PriGrsHydCmpDtctd 354;
BA_REL_ "GenSigTimeoutTime" BU_SG_REL_ ADIMa_PCE SG_ 354 PriGrsHydCmpDtctd 50;
BA_REL_ "GenSigRxStartValue" BU_SG_REL_ ADIMa_PCE SG_ 354 PriGrsHydLkDtctd "False";
BA_REL_ "GenSigSuprvResp" BU_SG_REL_ ADIMa_PCE SG_ 354 PriGrsHydLkDtctd 1;
BA_REL_ "GenSigTimeoutMsg" BU_SG_REL_ ADIMa_PCE SG_ 354 PriGrsHydLkDtctd 354;
BA_REL_ "GenSigTimeoutTime" BU_SG_REL_ ADIMa_PCE SG_ 354 PriGrsHydLkDtctd 50;
BA_REL_ "GenSigRxStartValue" BU_SG_REL_ ADIMa_PCE SG_ 354 RdRghnsStat "Normal";
BA_REL_ "GenSigSuprvResp" BU_SG_REL_ ADIMa_PCE SG_ 354 RdRghnsStat 1;
BA_REL_ "GenSigTimeoutMsg" BU_SG_REL_ ADIMa_PCE SG_ 354 RdRghnsStat 354;
BA_REL_ "GenSigTimeoutTime" BU_SG_REL_ ADIMa_PCE SG_ 354 RdRghnsStat 50;
BA_REL_ "GenSigRxStartValue" BU_SG_REL_ ADIMa_PCE SG_ 354 RdRghnsIndctn "0";
BA_REL_ "GenSigSuprvResp" BU_SG_REL_ ADIMa_PCE SG_ 354 RdRghnsIndctn 1;
BA_REL_ "GenSigTimeoutMsg" BU_SG_REL_ ADIMa_PCE SG_ 354 RdRghnsIndctn 354;
BA_REL_ "GenSigTimeoutTime" BU_SG_REL_ ADIMa_PCE SG_ 354 RdRghnsIndctn 50;
BA_REL_ "GenSigRxStartValue" BU_SG_REL_ ADIMa_PCE SG_ 354 EPBApplSt "Unknown";
BA_REL_ "GenSigSuprvResp" BU_SG_REL_ ADIMa_PCE SG_ 354 EPBApplSt 1;
BA_REL_ "GenSigTimeoutMsg" BU_SG_REL_ ADIMa_PCE SG_ 354 EPBApplSt 354;
BA_REL_ "GenSigTimeoutTime" BU_SG_REL_ ADIMa_PCE SG_ 354 EPBApplSt 50;
BA_REL_ "GenSigSuprvResp" BU_SG_REL_ EOCM2cp_K2_PCE SG_ 354 EPBApplSt 1;
BA_REL_ "GenSigTimeoutMsg" BU_SG_REL_ EOCM2cp_K2_PCE SG_ 354 EPBApplSt 354;
BA_REL_ "GenSigTimeoutTime" BU_SG_REL_ EOCM2cp_K2_PCE SG_ 354 EPBApplSt 25;
BA_REL_ "GenSigRxStartValue" BU_SG_REL_ ADIMa_PCE SG_ 354 EPBStat "Unknown";
BA_REL_ "GenSigSuprvResp" BU_SG_REL_ ADIMa_PCE SG_ 354 EPBStat 1;
BA_REL_ "GenSigTimeoutMsg" BU_SG_REL_ ADIMa_PCE SG_ 354 EPBStat 354;
BA_REL_ "GenSigTimeoutTime" BU_SG_REL_ ADIMa_PCE SG_ 354 EPBStat 50;
BA_REL_ "GenSigSuprvResp" BU_SG_REL_ EOCM2cp_K2_PCE SG_ 354 EPBStat 1;
BA_REL_ "GenSigTimeoutMsg" BU_SG_REL_ EOCM2cp_K2_PCE SG_ 354 EPBStat 354;
BA_REL_ "GenSigTimeoutTime" BU_SG_REL_ EOCM2cp_K2_PCE SG_ 354 EPBStat 25;
BA_REL_ "GenSigRxStartValue" BU_SG_REL_ ADIMa_PCE SG_ 354 BrkFldLvlIndStat "Normal";
BA_REL_ "GenSigSuprvResp" BU_SG_REL_ ADIMa_PCE SG_ 354 BrkFldLvlIndStat 1;
BA_REL_ "GenSigTimeoutMsg" BU_SG_REL_ ADIMa_PCE SG_ 354 BrkFldLvlIndStat 354;
BA_REL_ "GenSigTimeoutTime" BU_SG_REL_ ADIMa_PCE SG_ 354 BrkFldLvlIndStat 50;
BA_REL_ "GenSigRxStartValue" BU_SG_REL_ ADIMa_PCE SG_ 354 BrkFldLvILwFldDtctd "False";
BA_REL_ "GenSigSuprvResp" BU_SG_REL_ ADIMa_PCE SG_ 354 BrkFldLvILwFldDtctd 1;
BA_REL_ "GenSigTimeoutMsg" BU_SG_REL_ ADIMa_PCE SG_ 354 BrkFldLvILwFldDtctd 354;
BA_REL_ "GenSigTimeoutTime" BU_SG_REL_ ADIMa_PCE SG_ 354 BrkFldLvILwFldDtctd 50;
BA_REL_ "GenSigRxStartValue" BU_SG_REL_ ADIMa_PCE SG_ 354 PriESCStat "Unknown";
BA_REL_ "GenSigSuprvResp" BU_SG_REL_ ADIMa_PCE SG_ 354 PriESCStat 1;
BA_REL_ "GenSigTimeoutMsg" BU_SG_REL_ ADIMa_PCE SG_ 354 PriESCStat 354;
BA_REL_ "GenSigTimeoutTime" BU_SG_REL_ ADIMa_PCE SG_ 354 PriESCStat 50;
BA_REL_ "GenSigRxStartValue" BU_SG_REL_ ADIMa_PCE SG_ 354 PriTCSStat "Unknown";
BA_REL_ "GenSigSuprvResp" BU_SG_REL_ ADIMa_PCE SG_ 354 PriTCSStat 1;
BA_REL_ "GenSigTimeoutMsg" BU_SG_REL_ ADIMa_PCE SG_ 354 PriTCSStat 354;
BA_REL_ "GenSigTimeoutTime" BU_SG_REL_ ADIMa_PCE SG_ 354 PriTCSStat 50;
BA_REL_ "GenSigRxStartValue" BU_SG_REL_ ADIMa_PCE SG_ 354 PriABSStat "Unknown";
BA_REL_ "GenSigSuprvResp" BU_SG_REL_ ADIMa_PCE SG_ 354 PriABSStat 1;
BA_REL_ "GenSigTimeoutMsg" BU_SG_REL_ ADIMa_PCE SG_ 354 PriABSStat 354;
BA_REL_ "GenSigTimeoutTime" BU_SG_REL_ ADIMa_PCE SG_ 354 PriABSStat 50;
BA_REL_ "GenSigRxStartValue" BU_SG_REL_ ADIMa_PCE SG_ 354 PriDRPStat "Unknown";
BA_REL_ "GenSigSuprvResp" BU_SG_REL_ ADIMa_PCE SG_ 354 PriDRPStat 1;
BA_REL_ "GenSigTimeoutMsg" BU_SG_REL_ ADIMa_PCE SG_ 354 PriDRPStat 354;
BA_REL_ "GenSigTimeoutTime" BU_SG_REL_ ADIMa_PCE SG_ 354 PriDRPStat 50;
VAL_ 323 EBOOSTBtryVtgAvgV 1 "Invalid" 0 "Valid" ;
VAL_ 356 EBCMBtryVtgAvgV 1 "Invalid" 0 "Valid" ;
VAL_ 291 EPSBBtryVtgAvgV 1 "Invalid" 0 "Valid" ;
VAL_ 291 EPSaBtryVtgAvgV 1 "Invalid" 0 "Valid" ;
VAL_ 211 MtrRslvrAvgDrvWhlPstnV 1 "Invalid" 0 "Valid" ;
VAL_ 1010 SecuredVehSpdSrcDrvnRed 3 "Transmission Output Speed" 2 "Averaged Driven Wheel Speed" 1 "Motor RPM" 0 " No Source Available" ;
VAL_ 1010 SecuredVehSpdAvlblDrvnRed 1 "true" 0 "false" ;
VAL_ 1010 SecuredVehSpdDrvnRedV 1 "Invalid" 0 "Valid" ;
VAL_ 407 BrkPedDrvOvrdDtdESC 3 "Unknown" 2 "External Source Building Pressure" 1 "ESC Building System Pressure" 0 "ESC System Pressure Inactive" ;
VAL_ 407 VrtlMstCylPrsQlfr 2 "Faulted" 1 "Normal" 0 "Unknown" ;
VAL_ 407 BrkFldLvlLw197V 1 "Invalid" 0 "Valid" ;
VAL_ 407 BrkFldLvlLw197 1 "true" 0 "false" ;
VAL_ 407 AxSnsrOffstLngTrmV 1 "Invalid" 0 "Valid" ;
VAL_ 313 ActrBrkFldFlwReqStat 2 "qTarget_EBRmaxPerformance" 1 "qTarget_EBR" 0 "qTarget_Off" ;
VAL_ 313 ABSAtv139 1 "true" 0 "false" ;
VAL_ 313 MstCylPrsCrct1Stat 2 "Faulted" 1 "Normal" 0 "Unknown" ;
VAL_ 313 EBCMhydctrlAct 1 "true" 0 "false" ;
VAL_ 406 EstWhlBrkPrsStatRed 3 "Invalid" 2 "Reduced Accuracy" 1 "Valid" 0 "Unknown" ;
VAL_ 312 PriCoPCmdMsgStat 3 "Dual Communication Failure" 2 "Secondary Communication Failed" 1 "Main Communication Failed" 0 "Communication Normal" ;
VAL_ 312 PriADSCmdMsgStat 3 "Dual Communication Failure" 2 "Secondary Communication Failed" 1 "Main Communication Failed" 0 "Communication Normal" ;
VAL_ 312 PriBrkSysArbStat 7 "Supervisor Override" 6 "Automatic Brake Apply 2" 5 "Automatic Brake Apply 1" 4 "CoPilot Override Request Honored" 3 "Redundant ADS Request Honored" 2 "Main ADS Request Honored" 1 "No Autonomous Request" 0 "Unknown" ;
VAL_ 312 PriBrkSysStat 6 "Degraded Mode 5" 5 "Degraded Mode 4" 4 "Degraded Mode 3" 3 "Degraded Mode 2" 2 "Degraded Mode 1" 1 "Full Function" 0 "Unknown" ;
VAL_ 312 PriBrkRngLmtgStat 3 "Request Rate Limited" 2 "Req Value Limited Maximum" 1 "Req Value Limited Minimum" 0 "Request Not Limited" ;
VAL_ 312 PriBrkModSbSte 5 "Loss of Request" 4 "Full System" 3 "Failed Operational" 2 "Failed Degraded" 1 "Unable to Execute Requests" 0 "Faulted" ;
VAL_ 312 PriDrvIntvtnMdDetTO 1 "true" 0 "false" ;
VAL_ 404 SpltMuCntrlRedV 1 "Invalid" 0 "Valid" ;
VAL_ 404 SpltMuCntrlRed 2 "Split Driver Side High" 1 "Split Driver Side Low" 0 "Inactive" ;
VAL_ 404 PriEstSrfcMuTypRed 3 "Invalid" 2 "Actual Surface Estimate" 1 "Minimum Surface Estimate" 0 "Unknown" ;
VAL_ 404 PriBrkModCapStatRed 1 "Active" 0 "Not Active" ;
VAL_ 310 Diagpresreqstat 4 "Request Cancelled " 3 "Secondary Braking Req Honored" 2 "Primary Braking Request Honored" 1 "No Dynamic Request" 0 "Unknown" ;
VAL_ 310 Diagpresreqavl 1 "Invalid" 0 "Valid" ;
VAL_ 310 PriSuffBrkTrqStdstl 1 "true" 0 "false" ;
VAL_ 310 PriAutoBrkSysDrInfcStat 3 "Failed" 2 "Driver Intervention Not Detected" 1 "Driver Intervention Detected" 0 "Unknown" ;
VAL_ 310 PriBrkModStat 3 "Failed" 2 "Active" 1 "Available" 0 "Not Available" ;
VAL_ 310 PriAutoEstBrkTrqAppStat 2 "Valid" 1 "Reduced Accuracy" 0 "Invalid" ;
VAL_ 341 PrkBrkReqiB 1 "Apply" 0 "No Request" ;
VAL_ 341 ExtBrkReqStat 3 "External Brake Req Active" 2 "External Brake Req Available" 1 "External Brake Req Not Available" 0 "Unknown" ;
VAL_ 341 StrkOtptRodTgtQlfr 2 "Faulted" 1 "Normal" 0 "Unknown" ;
VAL_ 341 StrkOtptRodActlQlfr 2 "Faulted" 1 "Normal" 0 "Unknown" ;
VAL_ 403 PedOvrdBrkiBst 3 "Unknown" 2 "External Override of Brake Pedal" 1 "iBooster EBR in Control" 0 "iBooster Inactive" ;
VAL_ 403 iBstStat 7 "iBooster Ready" 6 "iBooster PostRun Reduced" 5 "iBooster Reduced" 2 "iBooster Diagnosis" 1 "iBooster Failure iBoosterOff" 0 "Unknown" 3 "iBooster Autonomous Diagnosis" 4 "iBooster Standalone" ;
VAL_ 403 HbcSptRedq 1 "true" 0 "false" ;
VAL_ 403 eBstDiagAtv 1 "true" 0 "false" ;
VAL_ 403 EBstRnotPrsQlfr 2 "Faulted" 1 "Normal" 0 "Unknown" ;
VAL_ 403 BrkPedApdQlfr 2 "Faulted" 1 "Normal" 0 "Unknown" ;
VAL_ 403 BrkPedApd 1 "true" 0 "false" ;
VAL_ 349 SecCoPCmdMsgStatRed 3 "Dual Communication Failure" 2 "Secondary Communication Failed" 1 "Main Communication Failed" 0 "Communication Normal" ;
VAL_ 349 SecBrkSysArbStatRed 7 "Supervisor Override" 6 "Automatic Brake Apply 2" 5 "Automatic Brake Apply 1" 4 "CoPilot Override Request Honored" 3 "Redundant ADS Request Honored" 2 "Main ADS Request Honored" 1 "No Autonomous Request" 0 "Unknown" ;
VAL_ 349 SecADSCmdMsgStatRed 3 "Dual Communication Failure" 2 "Secondary Communication Failed" 1 "Main Communication Failed" 0 "Communication Normal" ;
VAL_ 349 SecBrkModSbSteRed 5 "Loss of Request" 4 "Full System" 3 "Failed Operational" 2 "Failed Degraded" 1 "Unable to Execute Requests" 0 "Faulted" ;
VAL_ 349 SecBrkSysStatRed 6 "Degraded Mode 5" 5 "Degraded Mode 4" 4 "Degraded Mode 3" 3 "Degraded Mode 2" 2 "Degraded Mode 1" 1 "Full Function" 0 "Unknown" ;
VAL_ 349 SecBrkRngLmtgStatRed 3 "Request Rate Limited" 2 "Req Value Limited Maximum" 1 "Req Value Limited Minimum" 0 "Request Not Limited" ;
VAL_ 349 SecDrvIntvtnMdDetTORed 1 "true" 0 "false" ;
VAL_ 402 SecEstSrfcMuTypRed 3 "Invalid" 2 "Actual Surface Estimate" 1 "Minimum Surface Estimate" 0 "Unknown" ;
VAL_ 402 SecEstSrfcMuCapRedV 1 "Invalid" 0 "Valid" ;
VAL_ 402 SecBrkModCapRedStat 1 "Active" 0 "Not Active" ;
VAL_ 346 SecAutoEstBrkTrqAppStat 2 "Valid" 1 "Reduced Accuracy" 0 "Invalid" ;
VAL_ 346 SecBrkModStat 3 "Failed" 2 "Active" 1 "Available" 0 "Not Available" ;
VAL_ 346 SecAutoBrkSysDrInfcStat 3 "Failed" 2 "Driver Intervention Not Detected" 1 "Driver Intervention Detected" 0 "Unknown" ;
VAL_ 344 CSS_CoPilotCibAvail 1 "true" 0 "false" ;
VAL_ 344 CSS_CoPilotSysFltStat 5 "Copilot System Failure" 4 "Partial Function Fault Detected" 3 "Redundancy Fault Detected" 2 "Environmental Interference" 1 "Operational" 0 "Unknown" ;
VAL_ 344 CSS_CoPilotRvbAvail 1 "true" 0 "false" ;
VAL_ 344 CSS_CoPilotPcmAvail 1 "true" 0 "false" ;
VAL_ 344 CSS_CoPilotFcaAvail 1 "true" 0 "false" ;
VAL_ 344 CSS_CoPilotBrkExpctd 1 "true" 0 "false" ;
VAL_ 344 StrgAngTrqBsdEstSrfcMuConf 2 "Indeterminate" 1 "Use Data" 0 "Do Not Use Data" ;
VAL_ 344 StrgAngTrqBsdEstSrfcMuCapV 1 "Invalid" 0 "Valid" ;
VAL_ 531 Blkpdldet 1 "true" 0 "false" ;
VAL_ 531 SecGrsHydCmpDtctd 1 "true" 0 "false" ;
VAL_ 531 SecGrsHydLkDtctd 1 "true" 0 "false" ;
VAL_ 531 SecLatStabSysStat 3 "Failed" 2 "Active" 1 "Available" 0 "Unknown" ;
VAL_ 531 SecLongStabSysStat 3 "Failed" 2 "Active" 1 "Available" 0 "Unknown" ;
VAL_ 235 ACATC2_AutoCoPCntrlAct 1 "true" 0 "false" ;
VAL_ 342 StrgCmndMsgStatV 1 "Invalid" 0 "Valid" ;
VAL_ 342 StrgCmndMsgStat 3 "Dual Communication Failure" 2 "Redundant Communication Failed" 1 "Primary Communication Failed" 0 "Communication Normal" ;
VAL_ 342 StrgCmndMsgUtlzdV 1 "Invalid" 0 "Valid" ;
VAL_ 342 StrgCmndMsgUtlzd 1 "Redundant Controller" 0 "Primary Controller" ;
VAL_ 342 AutoStrgCmndStatV 1 "Invalid" 0 "Valid" ;
VAL_ 342 StgTrqSnsrVStat 1 "Invalid" 0 "Valid" ;
VAL_ 342 StgSysOtptStatV 1 "Invalid" 0 "Valid" ;
VAL_ 342 StgSysOtptStat 3 "Failed" 2 "Single Controller" 1 "Fail Operational" 0 "Unknown" ;
VAL_ 342 StgOtptTempLmtgSte 4 "Voltage" 3 "Thermal" 2 "Safety Limit Exceeded" 1 "Normal" 0 "Unknown" 7 "ECU Fault Limited" 6 "Friction Limited" 5 "Lash Exceeded" ;
VAL_ 342 StgAngRtLmtV 1 "Invalid" 0 "Valid" ;
VAL_ 342 AutoStrgCmndStat 6 "Failed" 5 "Emergency Steering Profile" 4 "Temporarily Limited" 3 "Active" 2 "Ready" 1 "Temporarily Inhibited" 0 "Unknown" ;
VAL_ 342 StgOvrdDetn 3 "Disabled" 2 "False" 1 "True" 0 "Initialization" ;
VAL_ 354 EstBrkRtrTempStat 1 "Failed" 0 "Normal" ;
VAL_ 354 PriGrsBrkIneffDtctd 1 "true" 0 "false" ;
VAL_ 354 PriGrsHydCmpDtctd 1 "true" 0 "false" ;
VAL_ 354 PriGrsHydLkDtctd 1 "true" 0 "false" ;
VAL_ 354 RdRghnsStat 1 "Failed" 0 "Normal" ;
VAL_ 354 EPBApplSt 3 "Applied" 2 "Transitioning" 1 "Released" 0 "Unknown" ;
VAL_ 354 EPBStat 3 "Failed" 2 "Reduced Performance" 1 "Normal" 0 "Unknown" ;
VAL_ 354 BrkFldLvlIndStat 1 "Failed" 0 "Normal" ;
VAL_ 354 BrkFldLvILwFldDtctd 1 "true" 0 "false" ;
VAL_ 354 PriESCStat 3 "Failed" 2 "Active" 1 "Available" 0 "Unknown" ;
VAL_ 354 PriTCSStat 3 "Failed" 2 "Active" 1 "Available" 0 "Unknown" ;
VAL_ 354 PriABSStat 3 "Failed" 2 "Active" 1 "Available" 0 "Unknown" ;
VAL_ 354 PriDRPStat 3 "Failed" 2 "Active" 1 "Available" 0 "Unknown" ;
SIG_GROUP_ 344 CoPilotSysStat 1 : CSS_CoPilotCibAvail CSS_CoPilotSysFltStat CSS_CoPilotRvbAvail CSS_CoPilotPcmAvail CSS_CoPilotFcaAvail CSS_CoPilotBrkExpctd;
SIG_GROUP_ 235 AutoCoPAxlTrqCmnd2 1 : ACATC2_AutoCoPCntrlAct ACATC2_CoPAxlTrqReq;
